VERSION ""

NS_ :

BS_:

BU_: TestTool AFL_AHL LDM_LH LDM_RH

BO_ 515 LightDistributionSystem: 5 AFL_AHL
 SG_ DistrCksm : 0|8@1+ (1,0) [0|255] ""  LDM_RH,LDM_LH
 SG_ RtCntryLghtDstrbtn : 15|1@1+ (1,0) [0|1] ""  LDM_LH,LDM_RH
 SG_ LftCntryLghtDstrbtn : 14|1@1+ (1,0) [0|1] ""  LDM_RH,LDM_LH
 SG_ RtAdvrsWthrLghtDstrbtn : 13|1@1+ (1,0) [0|1] ""  LDM_LH,LDM_RH
 SG_ LftAdvrsWthrLghtDstrbtn : 12|1@1+ (1,0) [0|1] ""  LDM_RH,LDM_LH
 SG_ DistrArc : 8|4@1+ (1,0) [0|15] ""  LDM_RH,LDM_LH
 SG_ RtGFHBLghtDstrbtnMtrwyLvl : 21|3@1+ (1,0) [0|7] ""  LDM_LH,LDM_RH
 SG_ RtDistrGFHB : 20|1@1+ (1,0) [0|1] ""  LDM_LH,LDM_RH
 SG_ LftGFHBLghtDstrbtnMtrwyLvl : 17|3@1+ (1,0) [0|7] ""  LDM_RH,LDM_LH
 SG_ LftDistrGFHB : 16|1@1+ (1,0) [0|1] ""  LDM_RH,LDM_LH
 SG_ LftMtrwyLghtDstrbtnLvl : 28|3@1+ (1,0) [0|7] ""  LDM_RH,LDM_LH
 SG_ RtMtrwyLghtDstrbtnLvl : 31|3@1+ (1,0) [0|7] ""  LDM_LH,LDM_RH
 SG_ RtHBLghtDstrbtn : 27|1@1+ (1,0) [0|1] ""  LDM_LH,LDM_RH
 SG_ LftHBLghtDstrbtn : 26|1@1+ (1,0) [0|1] ""  LDM_RH,LDM_LH
 SG_ RtHBFlshrLghtDstrbtn : 25|1@1+ (1,0) [0|1] ""  LDM_LH,LDM_RH
 SG_ LftHBFlshrLghtDstrbtn : 24|1@1+ (1,0) [0|1] ""  LDM_RH,LDM_LH
 SG_ RtTwnLghtDstrbtn : 37|1@1+ (1,0) [0|1] ""  LDM_LH,LDM_RH
 SG_ LftTwnLghtDstrbtn : 36|1@1+ (1,0) [0|1] ""  LDM_RH,LDM_LH
 SG_ RtPdstrnLghtDstrbtn : 35|1@1+ (1,0) [0|1] ""  LDM_LH,LDM_RH
 SG_ LftPdstrnLghtDstrbtn : 34|1@1+ (1,0) [0|1] ""  LDM_RH,LDM_LH

BO_ 1942 RtUsdtDiagResp: 8 LDM_RH
 SG_ RtUsdtDiagRsp : 7|64@0+ (1,0) [0|0] ""  TestTool

BO_ 1814 RtPhyDiagReq: 8 TestTool
 SG_ RtPhyDiagReq : 7|64@0+ (1,0) [0|1.84467440737096E+019] ""  LDM_RH

BO_ 2015 FuncDiagReq: 8 TestTool
 SG_ DiagInf : 7|64@0+ (1,0) [0|0] ""  LDM_RH,LDM_LH

BO_ 1813 LftPhyDiagReq: 8 TestTool
 SG_ LftPhyDiagReq : 7|64@0+ (1,0) [0|1.84467440737096E+019] ""  LDM_LH

BO_ 1941 LftUsdtDiagResp: 8 LDM_LH
 SG_ LftUsdtDiagRsp : 7|64@0+ (1,0) [0|0] ""  TestTool

BO_ 2161836032 ExtendIdTest: 8 TestTool
 SG_ Resp_LDMR_DgnInf : 7|64@0+ (1,0) [0|1.84467440737096E+019] ""  LDM_RH

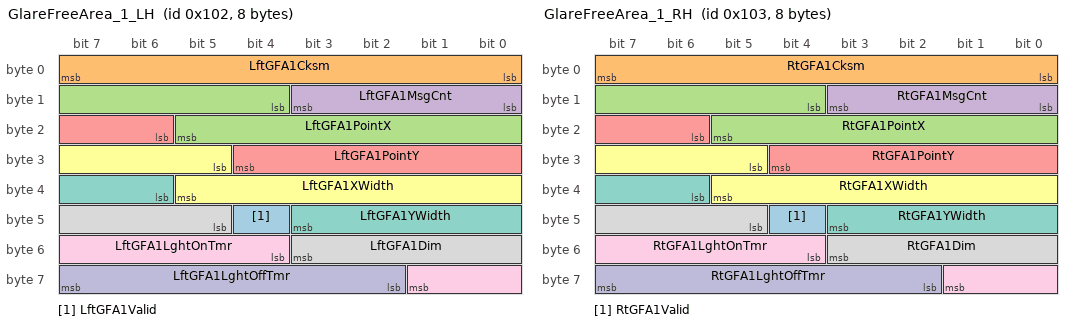
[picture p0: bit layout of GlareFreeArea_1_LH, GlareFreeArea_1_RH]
BO_ 258 GlareFreeArea_1_LH: 8 AFL_AHL
 SG_ LftGFA1Valid : 44|1@1+ (1,0) [0|1] ""  LDM_LH
 SG_ LftGFA1Cksm : 0|8@1+ (1,0) [0|255] ""  LDM_LH
 SG_ LftGFA1PointX : 12|10@1- (0.1,0) [-51.2|51.1] "deg"  LDM_LH
 SG_ LftGFA1MsgCnt : 8|4@1+ (1,0) [0|15] ""  LDM_LH
 SG_ LftGFA1PointY : 22|7@1- (0.1,0) [-6.4|6.3] "deg"  LDM_LH
 SG_ LftGFA1XWidth : 29|9@1+ (0.1,0) [0|51.1] "deg"  LDM_LH
 SG_ LftGFA1YWidth : 38|6@1+ (0.1,0) [0|6.3] "deg"  LDM_LH
 SG_ LftGFA1Dim : 45|7@1+ (1,0) [0|100] "%"  LDM_LH
 SG_ LftGFA1LghtOnTmr : 52|6@1+ (0.05,0) [0|3.15] "s"  LDM_LH
 SG_ LftGFA1LghtOffTmr : 58|6@1+ (0.05,0) [0|3.15] "s"  LDM_LH

BO_ 259 GlareFreeArea_1_RH: 8 AFL_AHL
 SG_ RtGFA1Valid : 44|1@1+ (1,0) [0|1] ""  LDM_RH
 SG_ RtGFA1Cksm : 0|8@1+ (1,0) [0|255] ""  LDM_RH
 SG_ RtGFA1PointX : 12|10@1- (0.1,0) [-51.2|51.1] "deg"  LDM_RH
 SG_ RtGFA1MsgCnt : 8|4@1+ (1,0) [0|15] ""  LDM_RH
 SG_ RtGFA1PointY : 22|7@1- (0.1,0) [-6.4|6.3] "deg"  LDM_RH
 SG_ RtGFA1XWidth : 29|9@1+ (0.1,0) [0|51.1] "deg"  LDM_RH
 SG_ RtGFA1YWidth : 38|6@1+ (0.1,0) [0|6.3] "deg"  LDM_RH
 SG_ RtGFA1Dim : 45|7@1+ (1,0) [0|100] "%"  LDM_RH
 SG_ RtGFA1LghtOnTmr : 52|6@1+ (0.05,0) [0|3.15] "s"  LDM_RH
 SG_ RtGFA1LghtOffTmr : 58|6@1+ (0.05,0) [0|3.15] "s"  LDM_RH

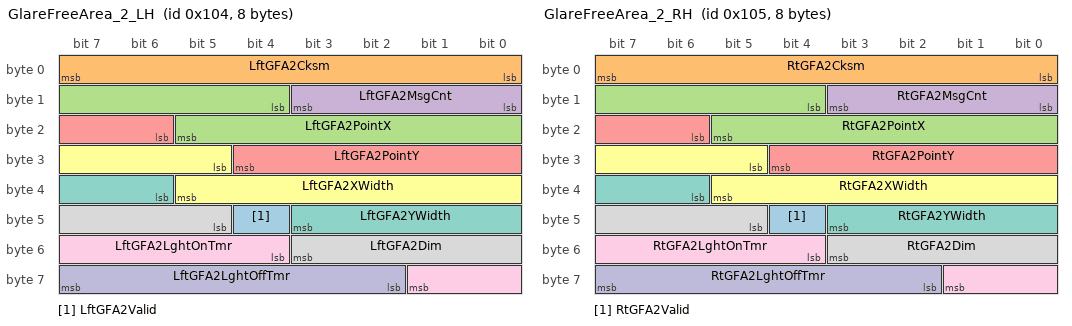
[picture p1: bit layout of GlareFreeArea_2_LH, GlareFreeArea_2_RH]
BO_ 260 GlareFreeArea_2_LH: 8 AFL_AHL
 SG_ LftGFA2Valid : 44|1@1+ (1,0) [0|1] ""  LDM_LH
 SG_ LftGFA2Cksm : 0|8@1+ (1,0) [0|255] ""  LDM_LH
 SG_ LftGFA2PointX : 12|10@1- (0.1,0) [-51.2|51.1] "deg"  LDM_LH
 SG_ LftGFA2MsgCnt : 8|4@1+ (1,0) [0|15] ""  LDM_LH
 SG_ LftGFA2PointY : 22|7@1- (0.1,0) [-6.4|6.3] "deg"  LDM_LH
 SG_ LftGFA2XWidth : 29|9@1+ (0.1,0) [0|51.1] "deg"  LDM_LH
 SG_ LftGFA2YWidth : 38|6@1+ (0.1,0) [0|6.3] "deg"  LDM_LH
 SG_ LftGFA2Dim : 45|7@1+ (1,0) [0|100] "%"  LDM_LH
 SG_ LftGFA2LghtOnTmr : 52|6@1+ (0.05,0) [0|3.15] "s"  LDM_LH
 SG_ LftGFA2LghtOffTmr : 58|6@1+ (0.05,0) [0|3.15] "s"  LDM_LH

BO_ 261 GlareFreeArea_2_RH: 8 AFL_AHL
 SG_ RtGFA2Valid : 44|1@1+ (1,0) [0|1] ""  LDM_RH
 SG_ RtGFA2Cksm : 0|8@1+ (1,0) [0|255] ""  LDM_RH
 SG_ RtGFA2PointX : 12|10@1- (0.1,0) [-51.2|51.1] "deg"  LDM_RH
 SG_ RtGFA2MsgCnt : 8|4@1+ (1,0) [0|15] ""  LDM_RH
 SG_ RtGFA2PointY : 22|7@1- (0.1,0) [-6.4|6.3] "deg"  LDM_RH
 SG_ RtGFA2XWidth : 29|9@1+ (0.1,0) [0|51.1] "deg"  LDM_RH
 SG_ RtGFA2YWidth : 38|6@1+ (0.1,0) [0|6.3] "deg"  LDM_RH
 SG_ RtGFA2Dim : 45|7@1+ (1,0) [0|100] "%"  LDM_RH
 SG_ RtGFA2LghtOnTmr : 52|6@1+ (0.05,0) [0|3.15] "s"  LDM_RH
 SG_ RtGFA2LghtOffTmr : 58|6@1+ (0.05,0) [0|3.15] "s"  LDM_RH

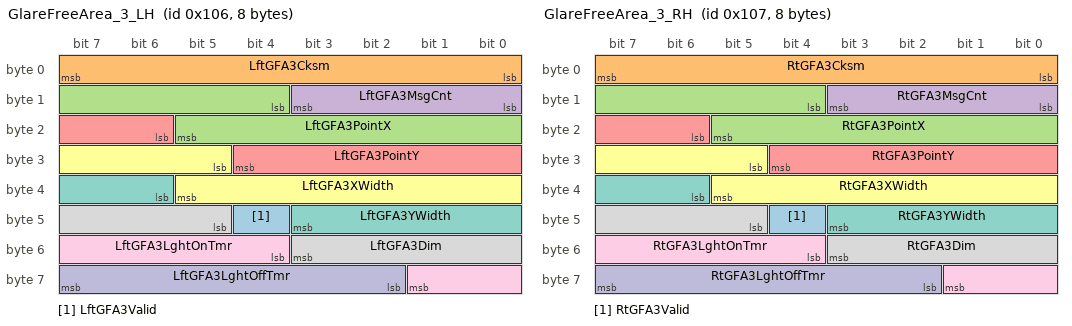
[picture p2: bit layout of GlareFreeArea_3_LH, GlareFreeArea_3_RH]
BO_ 262 GlareFreeArea_3_LH: 8 AFL_AHL
 SG_ LftGFA3Valid : 44|1@1+ (1,0) [0|1] ""  LDM_LH
 SG_ LftGFA3Cksm : 0|8@1+ (1,0) [0|255] ""  LDM_LH
 SG_ LftGFA3PointX : 12|10@1- (0.1,0) [-51.2|51.1] "deg"  LDM_LH
 SG_ LftGFA3MsgCnt : 8|4@1+ (1,0) [0|15] ""  LDM_LH
 SG_ LftGFA3PointY : 22|7@1- (0.1,0) [-6.4|6.3] "deg"  LDM_LH
 SG_ LftGFA3XWidth : 29|9@1+ (0.1,0) [0|51.1] "deg"  LDM_LH
 SG_ LftGFA3YWidth : 38|6@1+ (0.1,0) [0|6.3] "deg"  LDM_LH
 SG_ LftGFA3Dim : 45|7@1+ (1,0) [0|100] "%"  LDM_LH
 SG_ LftGFA3LghtOnTmr : 52|6@1+ (0.05,0) [0|3.15] "s"  LDM_LH
 SG_ LftGFA3LghtOffTmr : 58|6@1+ (0.05,0) [0|3.15] "s"  LDM_LH

BO_ 263 GlareFreeArea_3_RH: 8 AFL_AHL
 SG_ RtGFA3Valid : 44|1@1+ (1,0) [0|1] ""  LDM_RH
 SG_ RtGFA3Cksm : 0|8@1+ (1,0) [0|255] ""  LDM_RH
 SG_ RtGFA3PointX : 12|10@1- (0.1,0) [-51.2|51.1] "deg"  LDM_RH
 SG_ RtGFA3MsgCnt : 8|4@1+ (1,0) [0|15] ""  LDM_RH
 SG_ RtGFA3PointY : 22|7@1- (0.1,0) [-6.4|6.3] "deg"  LDM_RH
 SG_ RtGFA3XWidth : 29|9@1+ (0.1,0) [0|51.1] "deg"  LDM_RH
 SG_ RtGFA3YWidth : 38|6@1+ (0.1,0) [0|6.3] "deg"  LDM_RH
 SG_ RtGFA3Dim : 45|7@1+ (1,0) [0|100] "%"  LDM_RH
 SG_ RtGFA3LghtOnTmr : 52|6@1+ (0.05,0) [0|3.15] "s"  LDM_RH
 SG_ RtGFA3LghtOffTmr : 58|6@1+ (0.05,0) [0|3.15] "s"  LDM_RH

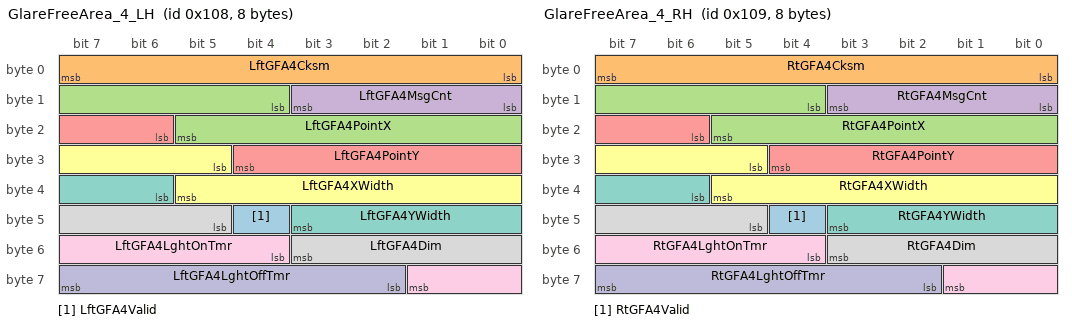
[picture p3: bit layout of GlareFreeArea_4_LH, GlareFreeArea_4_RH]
BO_ 264 GlareFreeArea_4_LH: 8 AFL_AHL
 SG_ LftGFA4Valid : 44|1@1+ (1,0) [0|1] ""  LDM_LH
 SG_ LftGFA4Cksm : 0|8@1+ (1,0) [0|255] ""  LDM_LH
 SG_ LftGFA4PointX : 12|10@1- (0.1,0) [-51.2|51.1] "deg"  LDM_LH
 SG_ LftGFA4MsgCnt : 8|4@1+ (1,0) [0|15] ""  LDM_LH
 SG_ LftGFA4PointY : 22|7@1- (0.1,0) [-6.4|6.3] "deg"  LDM_LH
 SG_ LftGFA4XWidth : 29|9@1+ (0.1,0) [0|51.1] "deg"  LDM_LH
 SG_ LftGFA4YWidth : 38|6@1+ (0.1,0) [0|6.3] "deg"  LDM_LH
 SG_ LftGFA4Dim : 45|7@1+ (1,0) [0|100] "%"  LDM_LH
 SG_ LftGFA4LghtOnTmr : 52|6@1+ (0.05,0) [0|3.15] "s"  LDM_LH
 SG_ LftGFA4LghtOffTmr : 58|6@1+ (0.05,0) [0|3.15] "s"  LDM_LH

BO_ 265 GlareFreeArea_4_RH: 8 AFL_AHL
 SG_ RtGFA4Valid : 44|1@1+ (1,0) [0|0] ""  LDM_RH
 SG_ RtGFA4Cksm : 0|8@1+ (1,0) [0|255] ""  LDM_RH
 SG_ RtGFA4PointX : 12|10@1- (0.1,0) [-51.2|51.1] "deg"  LDM_RH
 SG_ RtGFA4MsgCnt : 8|4@1+ (1,0) [0|15] ""  LDM_RH
 SG_ RtGFA4PointY : 22|7@1- (0.1,0) [-6.4|6.3] "deg"  LDM_RH
 SG_ RtGFA4XWidth : 29|9@1+ (0.1,0) [0|51.1] "deg"  LDM_RH
 SG_ RtGFA4YWidth : 38|6@1+ (0.1,0) [0|6.3] "deg"  LDM_RH
 SG_ RtGFA4Dim : 45|7@1+ (1,0) [0|100] "%"  LDM_RH
 SG_ RtGFA4LghtOnTmr : 52|6@1+ (0.05,0) [0|3.15] "s"  LDM_RH
 SG_ RtGFA4LghtOffTmr : 58|6@1+ (0.05,0) [0|3.15] "s"  LDM_RH

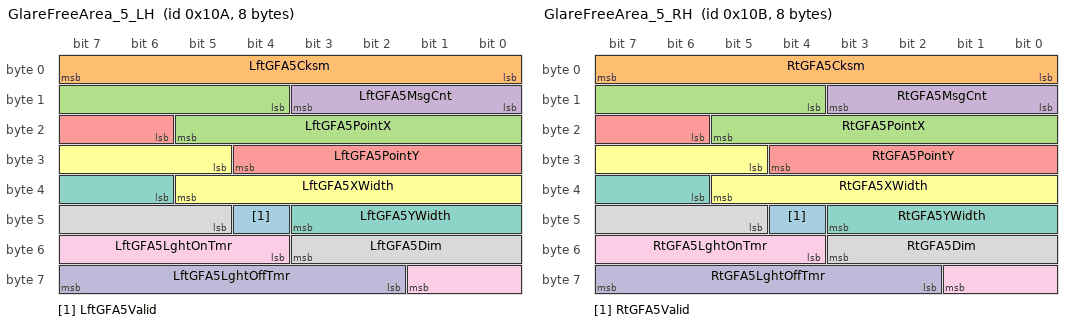
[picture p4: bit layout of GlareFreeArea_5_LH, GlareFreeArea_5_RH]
BO_ 266 GlareFreeArea_5_LH: 8 AFL_AHL
 SG_ LftGFA5Valid : 44|1@1+ (1,0) [0|0] ""  LDM_LH
 SG_ LftGFA5Cksm : 0|8@1+ (1,0) [0|255] ""  LDM_LH
 SG_ LftGFA5PointX : 12|10@1- (0.1,0) [-51.2|51.1] "deg"  LDM_LH
 SG_ LftGFA5MsgCnt : 8|4@1+ (1,0) [0|15] ""  LDM_LH
 SG_ LftGFA5PointY : 22|7@1- (0.1,0) [-6.4|6.3] "deg"  LDM_LH
 SG_ LftGFA5XWidth : 29|9@1+ (0.1,0) [0|51.1] "deg"  LDM_LH
 SG_ LftGFA5YWidth : 38|6@1+ (0.1,0) [0|6.3] "deg"  LDM_LH
 SG_ LftGFA5Dim : 45|7@1+ (1,0) [0|100] "%"  LDM_LH
 SG_ LftGFA5LghtOnTmr : 52|6@1+ (0.05,0) [0|3.15] "s"  LDM_LH
 SG_ LftGFA5LghtOffTmr : 58|6@1+ (0.05,0) [0|3.15] "s"  LDM_LH

BO_ 267 GlareFreeArea_5_RH: 8 AFL_AHL
 SG_ RtGFA5Valid : 44|1@1+ (1,0) [0|1] ""  LDM_RH
 SG_ RtGFA5Cksm : 0|8@1+ (1,0) [0|255] ""  LDM_RH
 SG_ RtGFA5PointX : 12|10@1- (0.1,0) [-51.2|51.1] "deg"  LDM_RH
 SG_ RtGFA5MsgCnt : 8|4@1+ (1,0) [0|15] ""  LDM_RH
 SG_ RtGFA5PointY : 22|7@1- (0.1,0) [-6.4|6.3] "deg"  LDM_RH
 SG_ RtGFA5XWidth : 29|9@1+ (0.1,0) [0|51.1] "deg"  LDM_RH
 SG_ RtGFA5YWidth : 38|6@1+ (0.1,0) [0|6.3] "deg"  LDM_RH
 SG_ RtGFA5Dim : 45|7@1+ (1,0) [0|100] "%"  LDM_RH
 SG_ RtGFA5LghtOnTmr : 52|6@1+ (0.05,0) [0|3.15] "s"  LDM_RH
 SG_ RtGFA5LghtOffTmr : 58|6@1+ (0.05,0) [0|3.15] "s"  LDM_RH

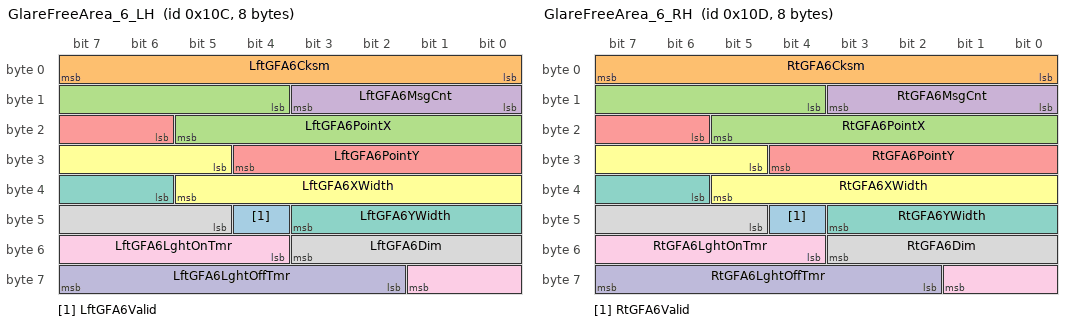
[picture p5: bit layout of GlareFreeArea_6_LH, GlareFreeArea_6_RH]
BO_ 268 GlareFreeArea_6_LH: 8 AFL_AHL
 SG_ LftGFA6Valid : 44|1@1+ (1,0) [0|1] ""  LDM_LH
 SG_ LftGFA6Cksm : 0|8@1+ (1,0) [0|255] ""  LDM_LH
 SG_ LftGFA6PointX : 12|10@1- (0.1,0) [-51.2|51.1] "deg"  LDM_LH
 SG_ LftGFA6MsgCnt : 8|4@1+ (1,0) [0|15] ""  LDM_LH
 SG_ LftGFA6PointY : 22|7@1- (0.1,0) [-6.4|6.3] "deg"  LDM_LH
 SG_ LftGFA6XWidth : 29|9@1+ (0.1,0) [0|51.1] "deg"  LDM_LH
 SG_ LftGFA6YWidth : 38|6@1+ (0.1,0) [0|6.3] "deg"  LDM_LH
 SG_ LftGFA6Dim : 45|7@1+ (1,0) [0|100] "%"  LDM_LH
 SG_ LftGFA6LghtOnTmr : 52|6@1+ (0.05,0) [0|3.15] "s"  LDM_LH
 SG_ LftGFA6LghtOffTmr : 58|6@1+ (0.05,0) [0|3.15] "s"  LDM_LH

BO_ 269 GlareFreeArea_6_RH: 8 AFL_AHL
 SG_ RtGFA6Valid : 44|1@1+ (1,0) [0|0] ""  LDM_RH
 SG_ RtGFA6Cksm : 0|8@1+ (1,0) [0|255] ""  LDM_RH
 SG_ RtGFA6PointX : 12|10@1- (0.1,0) [-51.2|51.1] "deg"  LDM_RH
 SG_ RtGFA6MsgCnt : 8|4@1+ (1,0) [0|15] ""  LDM_RH
 SG_ RtGFA6PointY : 22|7@1- (0.1,0) [-6.4|6.3] "deg"  LDM_RH
 SG_ RtGFA6XWidth : 29|9@1+ (0.1,0) [0|51.1] "deg"  LDM_RH
 SG_ RtGFA6YWidth : 38|6@1+ (0.1,0) [0|6.3] "deg"  LDM_RH
 SG_ RtGFA6Dim : 45|7@1+ (1,0) [0|100] "%"  LDM_RH
 SG_ RtGFA6LghtOnTmr : 52|6@1+ (0.05,0) [0|3.15] "s"  LDM_RH
 SG_ RtGFA6LghtOffTmr : 58|6@1+ (0.05,0) [0|3.15] "s"  LDM_RH

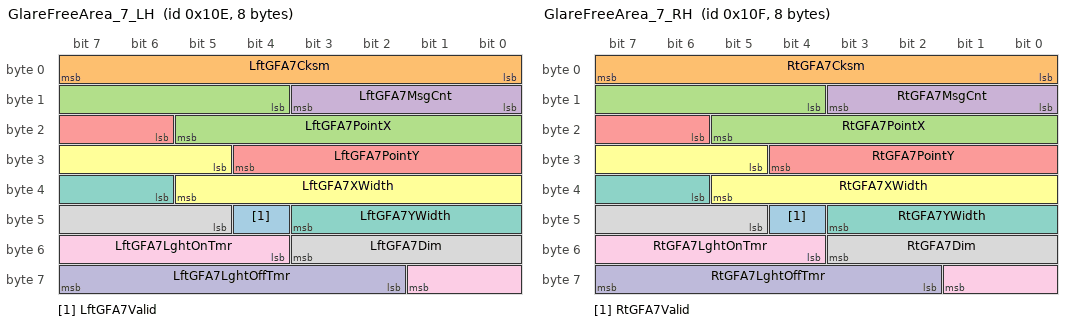
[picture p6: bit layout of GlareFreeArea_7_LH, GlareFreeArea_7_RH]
BO_ 270 GlareFreeArea_7_LH: 8 AFL_AHL
 SG_ LftGFA7Valid : 44|1@1+ (1,0) [0|0] ""  LDM_LH
 SG_ LftGFA7Cksm : 0|8@1+ (1,0) [0|255] ""  LDM_LH
 SG_ LftGFA7PointX : 12|10@1- (0.1,0) [-51.2|51.1] "deg"  LDM_LH
 SG_ LftGFA7MsgCnt : 8|4@1+ (1,0) [0|15] ""  LDM_LH
 SG_ LftGFA7PointY : 22|7@1- (0.1,0) [-6.4|6.3] "deg"  LDM_LH
 SG_ LftGFA7XWidth : 29|9@1+ (0.1,0) [0|51.1] "deg"  LDM_LH
 SG_ LftGFA7YWidth : 38|6@1+ (0.1,0) [0|6.3] "deg"  LDM_LH
 SG_ LftGFA7Dim : 45|7@1+ (1,0) [0|100] "%"  LDM_LH
 SG_ LftGFA7LghtOnTmr : 52|6@1+ (0.05,0) [0|3.15] "s"  LDM_LH
 SG_ LftGFA7LghtOffTmr : 58|6@1+ (0.05,0) [0|3.15] "s"  LDM_LH

BO_ 271 GlareFreeArea_7_RH: 8 AFL_AHL
 SG_ RtGFA7Valid : 44|1@1+ (1,0) [0|0] ""  LDM_RH
 SG_ RtGFA7Cksm : 0|8@1+ (1,0) [0|255] ""  LDM_RH
 SG_ RtGFA7PointX : 12|10@1- (0.1,0) [-51.2|51.1] "deg"  LDM_RH
 SG_ RtGFA7MsgCnt : 8|4@1+ (1,0) [0|15] ""  LDM_RH
 SG_ RtGFA7PointY : 22|7@1- (0.1,0) [-6.4|6.3] "deg"  LDM_RH
 SG_ RtGFA7XWidth : 29|9@1+ (0.1,0) [0|51.1] "deg"  LDM_RH
 SG_ RtGFA7YWidth : 38|6@1+ (0.1,0) [0|6.3] "deg"  LDM_RH
 SG_ RtGFA7Dim : 45|7@1+ (1,0) [0|100] "%"  LDM_RH
 SG_ RtGFA7LghtOnTmr : 52|6@1+ (0.05,0) [0|3.15] "s"  LDM_RH
 SG_ RtGFA7LghtOffTmr : 58|6@1+ (0.05,0) [0|3.15] "s"  LDM_RH

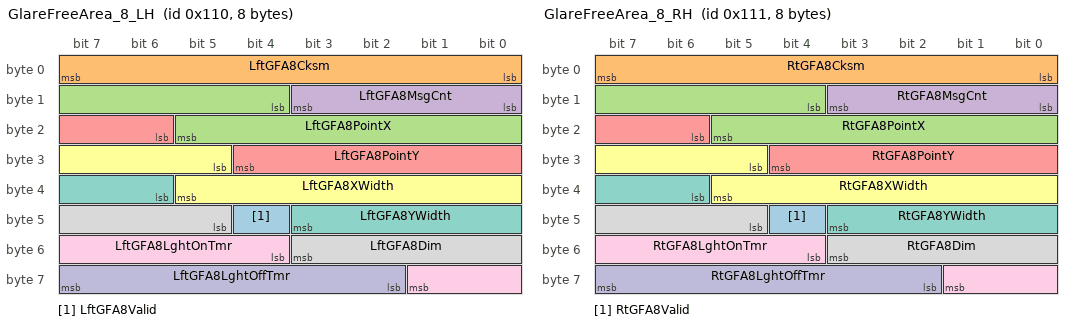
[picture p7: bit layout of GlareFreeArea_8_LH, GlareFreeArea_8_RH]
BO_ 272 GlareFreeArea_8_LH: 8 AFL_AHL
 SG_ LftGFA8Valid : 44|1@1+ (1,0) [0|0] ""  LDM_LH
 SG_ LftGFA8Cksm : 0|8@1+ (1,0) [0|255] ""  LDM_LH
 SG_ LftGFA8PointX : 12|10@1- (0.1,0) [-51.2|51.1] "deg"  LDM_LH
 SG_ LftGFA8MsgCnt : 8|4@1+ (1,0) [0|15] ""  LDM_LH
 SG_ LftGFA8PointY : 22|7@1- (0.1,0) [-6.4|6.3] "deg"  LDM_LH
 SG_ LftGFA8XWidth : 29|9@1+ (0.1,0) [0|51.1] "deg"  LDM_LH
 SG_ LftGFA8YWidth : 38|6@1+ (0.1,0) [0|6.3] "deg"  LDM_LH
 SG_ LftGFA8Dim : 45|7@1+ (1,0) [0|100] "%"  LDM_LH
 SG_ LftGFA8LghtOnTmr : 52|6@1+ (0.05,0) [0|3.15] "s"  LDM_LH
 SG_ LftGFA8LghtOffTmr : 58|6@1+ (0.05,0) [0|3.15] "s"  LDM_LH

BO_ 273 GlareFreeArea_8_RH: 8 AFL_AHL
 SG_ RtGFA8Valid : 44|1@1+ (1,0) [0|1] ""  LDM_RH
 SG_ RtGFA8Cksm : 0|8@1+ (1,0) [0|255] ""  LDM_RH
 SG_ RtGFA8PointX : 12|10@1- (0.1,0) [-51.2|51.1] "deg"  LDM_RH
 SG_ RtGFA8MsgCnt : 8|4@1+ (1,0) [0|15] ""  LDM_RH
 SG_ RtGFA8PointY : 22|7@1- (0.1,0) [-6.4|6.3] "deg"  LDM_RH
 SG_ RtGFA8XWidth : 29|9@1+ (0.1,0) [0|51.1] "deg"  LDM_RH
 SG_ RtGFA8YWidth : 38|6@1+ (0.1,0) [0|6.3] "deg"  LDM_RH
 SG_ RtGFA8Dim : 45|7@1+ (1,0) [0|100] "%"  LDM_RH
 SG_ RtGFA8LghtOnTmr : 52|6@1+ (0.05,0) [0|3.15] "s"  LDM_RH
 SG_ RtGFA8LghtOffTmr : 58|6@1+ (0.05,0) [0|3.15] "s"  LDM_RH

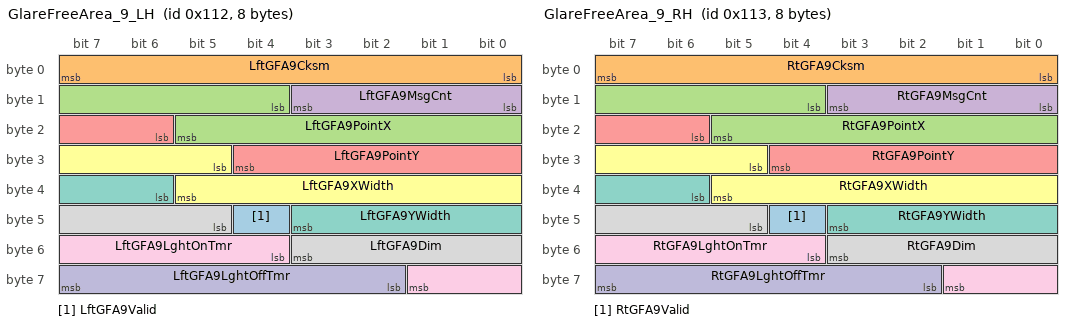
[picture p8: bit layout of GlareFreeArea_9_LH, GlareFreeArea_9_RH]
BO_ 274 GlareFreeArea_9_LH: 8 AFL_AHL
 SG_ LftGFA9Valid : 44|1@1+ (1,0) [0|0] ""  LDM_LH
 SG_ LftGFA9Cksm : 0|8@1+ (1,0) [0|255] ""  LDM_LH
 SG_ LftGFA9PointX : 12|10@1- (0.1,0) [-51.2|51.1] "deg"  LDM_LH
 SG_ LftGFA9MsgCnt : 8|4@1+ (1,0) [0|15] ""  LDM_LH
 SG_ LftGFA9PointY : 22|7@1- (0.1,0) [-6.4|6.3] "deg"  LDM_LH
 SG_ LftGFA9XWidth : 29|9@1+ (0.1,0) [0|51.1] "deg"  LDM_LH
 SG_ LftGFA9YWidth : 38|6@1+ (0.1,0) [0|6.3] "deg"  LDM_LH
 SG_ LftGFA9Dim : 45|7@1+ (1,0) [0|100] "%"  LDM_LH
 SG_ LftGFA9LghtOnTmr : 52|6@1+ (0.05,0) [0|3.15] "s"  LDM_LH
 SG_ LftGFA9LghtOffTmr : 58|6@1+ (0.05,0) [0|3.15] "s"  LDM_LH

BO_ 275 GlareFreeArea_9_RH: 8 AFL_AHL
 SG_ RtGFA9Valid : 44|1@1+ (1,0) [0|1] ""  LDM_RH
 SG_ RtGFA9Cksm : 0|8@1+ (1,0) [0|255] ""  LDM_RH
 SG_ RtGFA9PointX : 12|10@1- (0.1,0) [-51.2|51.1] "deg"  LDM_RH
 SG_ RtGFA9MsgCnt : 8|4@1+ (1,0) [0|15] ""  LDM_RH
 SG_ RtGFA9PointY : 22|7@1- (0.1,0) [-6.4|6.3] "deg"  LDM_RH
 SG_ RtGFA9XWidth : 29|9@1+ (0.1,0) [0|51.1] "deg"  LDM_RH
 SG_ RtGFA9YWidth : 38|6@1+ (0.1,0) [0|6.3] "deg"  LDM_RH
 SG_ RtGFA9Dim : 45|7@1+ (1,0) [0|100] "%"  LDM_RH
 SG_ RtGFA9LghtOnTmr : 52|6@1+ (0.05,0) [0|3.15] "s"  LDM_RH
 SG_ RtGFA9LghtOffTmr : 58|6@1+ (0.05,0) [0|3.15] "s"  LDM_RH

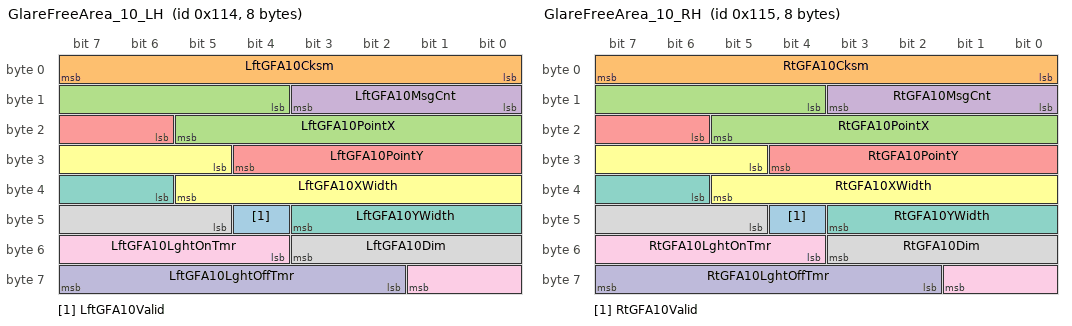
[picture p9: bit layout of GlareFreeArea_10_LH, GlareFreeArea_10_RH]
BO_ 276 GlareFreeArea_10_LH: 8 AFL_AHL
 SG_ LftGFA10Valid : 44|1@1+ (1,0) [0|1] ""  LDM_LH
 SG_ LftGFA10Cksm : 0|8@1+ (1,0) [0|255] ""  LDM_LH
 SG_ LftGFA10PointX : 12|10@1- (0.1,0) [-51.2|51.1] "deg"  LDM_LH
 SG_ LftGFA10MsgCnt : 8|4@1+ (1,0) [0|15] ""  LDM_LH
 SG_ LftGFA10PointY : 22|7@1- (0.1,0) [-6.4|6.3] "deg"  LDM_LH
 SG_ LftGFA10XWidth : 29|9@1+ (0.1,0) [0|51.1] "deg"  LDM_LH
 SG_ LftGFA10YWidth : 38|6@1+ (0.1,0) [0|6.3] "deg"  LDM_LH
 SG_ LftGFA10Dim : 45|7@1+ (1,0) [0|100] "%"  LDM_LH
 SG_ LftGFA10LghtOnTmr : 52|6@1+ (0.05,0) [0|3.15] "s"  LDM_LH
 SG_ LftGFA10LghtOffTmr : 58|6@1+ (0.05,0) [0|3.15] "s"  LDM_LH

BO_ 277 GlareFreeArea_10_RH: 8 AFL_AHL
 SG_ RtGFA10Valid : 44|1@1+ (1,0) [0|1] ""  LDM_RH
 SG_ RtGFA10Cksm : 0|8@1+ (1,0) [0|255] ""  LDM_RH
 SG_ RtGFA10PointX : 12|10@1- (0.1,0) [-51.2|51.1] "deg"  LDM_RH
 SG_ RtGFA10MsgCnt : 8|4@1+ (1,0) [0|15] ""  LDM_RH
 SG_ RtGFA10PointY : 22|7@1- (0.1,0) [-6.4|6.3] "deg"  LDM_RH
 SG_ RtGFA10XWidth : 29|9@1+ (0.1,0) [0|51.1] "deg"  LDM_RH
 SG_ RtGFA10YWidth : 38|6@1+ (0.1,0) [0|6.3] "deg"  LDM_RH
 SG_ RtGFA10Dim : 45|7@1+ (1,0) [0|100] "%"  LDM_RH
 SG_ RtGFA10LghtOnTmr : 52|6@1+ (0.05,0) [0|3.15] "s"  LDM_RH
 SG_ RtGFA10LghtOffTmr : 58|6@1+ (0.05,0) [0|3.15] "s"  LDM_RH

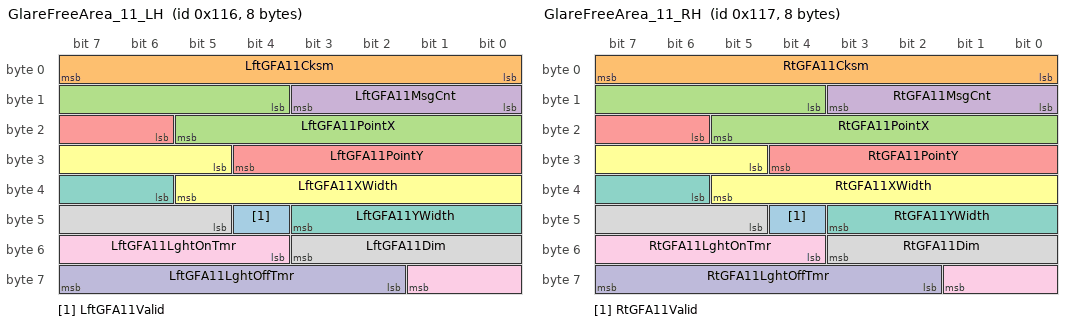
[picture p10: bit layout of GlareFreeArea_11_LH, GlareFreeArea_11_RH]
BO_ 278 GlareFreeArea_11_LH: 8 AFL_AHL
 SG_ LftGFA11Valid : 44|1@1+ (1,0) [0|1] ""  LDM_LH
 SG_ LftGFA11Cksm : 0|8@1+ (1,0) [0|255] ""  LDM_LH
 SG_ LftGFA11PointX : 12|10@1- (0.1,0) [-51.2|51.1] "deg"  LDM_LH
 SG_ LftGFA11MsgCnt : 8|4@1+ (1,0) [0|15] ""  LDM_LH
 SG_ LftGFA11PointY : 22|7@1- (0.1,0) [-6.4|6.3] "deg"  LDM_LH
 SG_ LftGFA11XWidth : 29|9@1+ (0.1,0) [0|51.1] "deg"  LDM_LH
 SG_ LftGFA11YWidth : 38|6@1+ (0.1,0) [0|6.3] "deg"  LDM_LH
 SG_ LftGFA11Dim : 45|7@1+ (1,0) [0|100] "%"  LDM_LH
 SG_ LftGFA11LghtOnTmr : 52|6@1+ (0.05,0) [0|3.15] "s"  LDM_LH
 SG_ LftGFA11LghtOffTmr : 58|6@1+ (0.05,0) [0|3.15] "s"  LDM_LH

BO_ 279 GlareFreeArea_11_RH: 8 AFL_AHL
 SG_ RtGFA11Valid : 44|1@1+ (1,0) [0|1] ""  LDM_RH
 SG_ RtGFA11Cksm : 0|8@1+ (1,0) [0|255] ""  LDM_RH
 SG_ RtGFA11PointX : 12|10@1- (0.1,0) [-51.2|51.1] "deg"  LDM_RH
 SG_ RtGFA11MsgCnt : 8|4@1+ (1,0) [0|15] ""  LDM_RH
 SG_ RtGFA11PointY : 22|7@1- (0.1,0) [-6.4|6.3] "deg"  LDM_RH
 SG_ RtGFA11XWidth : 29|9@1+ (0.1,0) [0|51.1] "deg"  LDM_RH
 SG_ RtGFA11YWidth : 38|6@1+ (0.1,0) [0|6.3] "deg"  LDM_RH
 SG_ RtGFA11Dim : 45|7@1+ (1,0) [0|100] "%"  LDM_RH
 SG_ RtGFA11LghtOnTmr : 52|6@1+ (0.05,0) [0|3.15] "s"  LDM_RH
 SG_ RtGFA11LghtOffTmr : 58|6@1+ (0.05,0) [0|3.15] "s"  LDM_RH

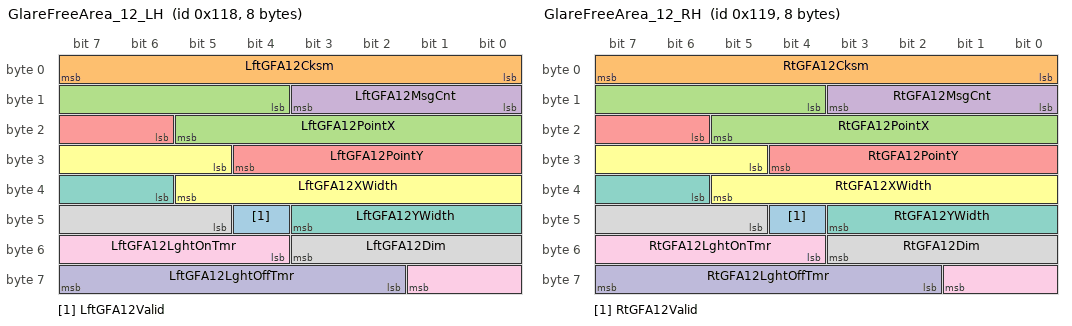
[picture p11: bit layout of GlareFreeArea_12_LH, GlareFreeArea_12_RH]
BO_ 280 GlareFreeArea_12_LH: 8 AFL_AHL
 SG_ LftGFA12Valid : 44|1@1+ (1,0) [0|1] ""  LDM_LH
 SG_ LftGFA12Cksm : 0|8@1+ (1,0) [0|255] ""  LDM_LH
 SG_ LftGFA12PointX : 12|10@1- (0.1,0) [-51.2|51.1] "deg"  LDM_LH
 SG_ LftGFA12MsgCnt : 8|4@1+ (1,0) [0|15] ""  LDM_LH
 SG_ LftGFA12PointY : 22|7@1- (0.1,0) [-6.4|6.3] "deg"  LDM_LH
 SG_ LftGFA12XWidth : 29|9@1+ (0.1,0) [0|51.1] "deg"  LDM_LH
 SG_ LftGFA12YWidth : 38|6@1+ (0.1,0) [0|6.3] "deg"  LDM_LH
 SG_ LftGFA12Dim : 45|7@1+ (1,0) [0|100] "%"  LDM_LH
 SG_ LftGFA12LghtOnTmr : 52|6@1+ (0.05,0) [0|3.15] "s"  LDM_LH
 SG_ LftGFA12LghtOffTmr : 58|6@1+ (0.05,0) [0|3.15] "s"  LDM_LH

BO_ 281 GlareFreeArea_12_RH: 8 AFL_AHL
 SG_ RtGFA12Valid : 44|1@1+ (1,0) [0|1] ""  LDM_RH
 SG_ RtGFA12Cksm : 0|8@1+ (1,0) [0|255] ""  LDM_RH
 SG_ RtGFA12PointX : 12|10@1- (0.1,0) [-51.2|51.1] "deg"  LDM_RH
 SG_ RtGFA12MsgCnt : 8|4@1+ (1,0) [0|15] ""  LDM_RH
 SG_ RtGFA12PointY : 22|7@1- (0.1,0) [-6.4|6.3] "deg"  LDM_RH
 SG_ RtGFA12XWidth : 29|9@1+ (0.1,0) [0|51.1] "deg"  LDM_RH
 SG_ RtGFA12YWidth : 38|6@1+ (0.1,0) [0|6.3] "deg"  LDM_RH
 SG_ RtGFA12Dim : 45|7@1+ (1,0) [0|100] "%"  LDM_RH
 SG_ RtGFA12LghtOnTmr : 52|6@1+ (0.05,0) [0|3.15] "s"  LDM_RH
 SG_ RtGFA12LghtOffTmr : 58|6@1+ (0.05,0) [0|3.15] "s"  LDM_RH

BO_ 481 GlareFreeHighBeamControl_RH: 2 AFL_AHL
 SG_ RtDiagLed : 15|8@0+ (1,0) [0|0] ""  LDM_RH
 SG_ RtRoutineCtrl : 7|1@0+ (1,0) [0|0] ""  LDM_RH

BO_ 512 LightCenterOfGravityMovement: 7 AFL_AHL
 SG_ LCGM_LghtCntrWdthLftSdEdg : 7|11@0- (0.1,0) [-102.4|102.3] "LCGM_LghtCntrWdthLftSdEdg_Units"  LDM_LH
 SG_ LCGM_LghtCntrWdthRtSdEdg : 23|11@0- (0.1,0) [-102.4|102.3] "LCGM_LghtCntrWdthRtSdEdg_Units"  LDM_RH
 SG_ LCGM_CntrLghtLvl : 39|8@0+ (0.5,0) [0|127.5] "LCGM_CntrLghtLvl_Units"  LDM_LH,LDM_RH
 SG_ LCGM_BckgrndLghtLvl : 47|8@0+ (0.5,0) [0|127.5] "LCGM_BckgrndLghtLvl_Units"  LDM_LH,LDM_RH
 SG_ LCGM_FnctnStat : 55|1@0+ (1,0) [0|1] ""  LDM_LH,LDM_RH

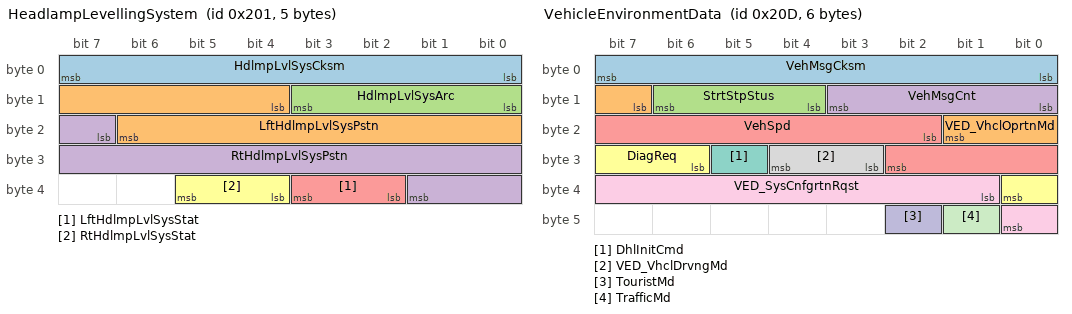
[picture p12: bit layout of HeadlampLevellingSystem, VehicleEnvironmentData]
BO_ 513 HeadlampLevellingSystem: 5 AFL_AHL
 SG_ HdlmpLvlSysCksm : 0|8@1+ (1,0) [0|255] ""  LDM_RH,LDM_LH
 SG_ LftHdlmpLvlSysPstn : 12|11@1- (0.01,0) [-10.24|10.23] "%"  LDM_RH,LDM_LH
 SG_ HdlmpLvlSysArc : 8|4@1+ (1,0) [0|15] ""  LDM_RH,LDM_LH
 SG_ RtHdlmpLvlSysPstn : 23|11@1- (0.01,0) [-10.24|10.23] "%"  LDM_LH,LDM_RH
 SG_ LftHdlmpLvlSysStat : 34|2@1+ (1,0) [0|3] "Enum"  LDM_RH,LDM_LH
 SG_ RtHdlmpLvlSysStat : 36|2@1+ (1,0) [0|3] "Enum"  LDM_LH,LDM_RH

BO_ 514 DynamicBendingLightSystem: 5 AFL_AHL
 SG_ DBLS_Chcksm : 0|8@1+ (1,0) [0|255] ""  LDM_RH,LDM_LH
 SG_ DBLS_LftHdlmpSwvlAngl : 12|11@1- (0.05,0) [-51.2|51.15] "DBLS_LftHdlmpSwvlAngl_Units"  LDM_RH,LDM_LH
 SG_ DBLS_MssgCntr : 8|4@1+ (1,0) [0|15] ""  LDM_RH,LDM_LH
 SG_ DBLS_RtHdlmpSwvlAngl : 23|11@1- (0.05,0) [-51.2|51.15] "DBLS_RtHdlmpSwvlAngl_Units"  LDM_LH,LDM_RH

BO_ 516 StaticBendingLightSystem: 2 AFL_AHL
 SG_ LftBndDim : 7|8@0+ (0.5,0) [0|100] "%"  LDM_LH
 SG_ RtBndDim : 15|8@0+ (0.5,0) [0|100] "%"  LDM_RH

BO_ 523 StartStopLightSystem: 4 AFL_AHL
 SG_ SSLS_Chcksm : 7|8@0+ (1,0) [0|255] ""  LDM_RH,LDM_LH
 SG_ SSLS_LftHdlmpStrtStpIntnstyVal : 11|8@0+ (0.5,0) [0|127.5] "SSLS_LftHdlmpStrtStpIntnstyVal_U"  LDM_RH,LDM_LH
 SG_ SSLS_MssgCntr : 15|4@0+ (1,0) [0|15] ""  LDM_RH,LDM_LH
 SG_ SSLS_RtHdlmpStrtStpIntnstyVal : 19|8@0+ (0.5,0) [0|127.5] "SSLS_RtHdlmpStrtStpIntnstyVal_"  LDM_RH,LDM_LH

BO_ 525 VehicleEnvironmentData: 6 AFL_AHL
 SG_ VehMsgCksm : 0|8@1+ (1,0) [0|255] ""  LDM_RH,LDM_LH
 SG_ VED_VhclOprtnMd : 15|3@1+ (1,0) [0|7] ""  LDM_RH,LDM_LH
 SG_ StrtStpStus : 12|3@1+ (1,0) [0|7] ""  LDM_LH,LDM_RH
 SG_ VehMsgCnt : 8|4@1+ (1,0) [0|15] ""  LDM_RH,LDM_LH
 SG_ VehSpd : 18|9@1+ (1,0) [0|511] "km/h"  LDM_LH,LDM_RH
 SG_ DiagReq : 30|3@1+ (1,0) [0|7] ""  LDM_RH,LDM_LH
 SG_ DhlInitCmd : 29|1@1+ (1,0) [0|1] "Enum"  LDM_LH,LDM_RH
 SG_ VED_VhclDrvngMd : 27|2@1+ (1,0) [0|3] ""  LDM_RH,LDM_LH
 SG_ VED_SysCnfgrtnRqst : 33|8@1+ (1,0) [0|255] ""  LDM_RH,LDM_LH
 SG_ TouristMd : 42|1@1+ (1,0) [0|1] ""  LDM_LH,LDM_RH
 SG_ TrafficMd : 41|1@1+ (1,0) [0|1] ""  LDM_LH,LDM_RH

BO_ 1024 SysSt_LftGlareFreeHighBeam: 8 LDM_LH
 SG_ LftGFHBSysSts : 8|56@1+ (1,0) [0|7.20575940379279E+016] ""  AFL_AHL
 SG_ LftGFHBCksm : 0|8@1+ (1,0) [0|255] ""  AFL_AHL

BO_ 1025 SysSt_RtGlareFreeHighBeam: 8 LDM_RH
 SG_ RtGFHBSysSts : 8|56@1+ (1,0) [0|7.20575940379279E+016] ""  AFL_AHL
 SG_ RtGFHBCksm : 0|8@1+ (1,0) [0|255] ""  AFL_AHL

BO_ 1026 SysSt_LftLevellingSystem: 8 LDM_LH
 SG_ LftDhlSysSts : 8|56@1+ (1,0) [0|7.20575940379279E+016] ""  AFL_AHL
 SG_ LftDhlCksm : 0|8@1+ (1,0) [0|255] ""  AFL_AHL

BO_ 1027 SysSt_RtLevellingSystem: 8 LDM_RH
 SG_ RtDhlSysSts : 8|56@1+ (1,0) [0|7.20575940379279E+016] ""  AFL_AHL
 SG_ RtDhlCksm : 0|8@1+ (1,0) [0|255] ""  AFL_AHL

BO_ 1028 SysSt_LftDynBendingLight: 8 LDM_LH
 SG_ LftDBndCksm : 0|8@1+ (1,0) [0|255] ""  AFL_AHL
 SG_ LftDBndSysSts : 8|56@1+ (1,0) [0|7.20575940379279E+016] ""  AFL_AHL

BO_ 1029 SysSt_RtDynBendingLight: 8 LDM_RH
 SG_ RtDBndCksm : 0|8@1+ (1,0) [0|255] ""  AFL_AHL
 SG_ RtDBndSysSts : 8|56@1+ (1,0) [0|7.20575940379279E+016] ""  AFL_AHL

BO_ 1030 SysSt_LftLightDistribution: 8 LDM_LH
 SG_ LftDistrSysSts : 8|56@1+ (1,0) [0|7.20575940379279E+016] ""  AFL_AHL
 SG_ LftDistrCksm : 0|8@1+ (1,0) [0|255] ""  AFL_AHL

BO_ 1031 SysSt_RtLightDistribution: 8 LDM_RH
 SG_ RtDistrSysSts : 8|56@1+ (1,0) [0|7.20575940379279E+016] ""  AFL_AHL
 SG_ RtDistrCksm : 0|8@1+ (1,0) [0|255] ""  AFL_AHL

BO_ 1032 SysSt_LftStaticBendingLight: 8 LDM_LH
 SG_ LftBndSysSts : 11|52@0+ (1,0) [0|4.5035996273705E+015] ""  AFL_AHL

BO_ 1033 SysSt_RtStaticBendingLight: 8 LDM_RH
 SG_ RtBndSysSts : 11|52@0+ (1,0) [0|4.5035996273705E+015] ""  AFL_AHL

BO_ 1042 SysSt_LftLowBeam: 8 LDM_LH
 SG_ LftLbSysSts : 8|56@1+ (1,0) [0|7.20575940379279E+016] ""  AFL_AHL
 SG_ LftLbCksm : 0|8@1+ (1,0) [0|255] ""  AFL_AHL

BO_ 1043 SysSt_RtLowBeam: 8 LDM_RH
 SG_ RtLbSysSts : 8|56@1+ (1,0) [0|7.20575940379279E+016] ""  AFL_AHL
 SG_ RtLbCksm : 0|8@1+ (1,0) [0|255] ""  AFL_AHL

BO_ 1044 SysSt_LftHighBeam: 8 LDM_LH
 SG_ LftHbSysSts : 8|56@1+ (1,0) [0|7.20575940379279E+016] ""  AFL_AHL
 SG_ LftHbCksm : 0|8@1+ (1,0) [0|255] ""  AFL_AHL

BO_ 1045 SysSt_RtHighBeam: 8 LDM_RH
 SG_ RtHbSysSts : 8|56@1+ (1,0) [0|7.20575940379279E+016] ""  AFL_AHL
 SG_ RtHbCksm : 0|8@1+ (1,0) [0|255] ""  AFL_AHL

BO_ 1280 LftEcuIdent: 8 LDM_LH
 SG_ LftLdmInfo : 15|56@0+ (1,0) [0|7.20575940379279E+016] ""  AFL_AHL
 SG_ LftLdmInfoIdx : 7|8@0+ (1,0) [0|255] ""  AFL_AHL

BO_ 1281 RtEcuIdent: 8 LDM_RH
 SG_ RtLdmInfo : 15|56@0+ (1,0) [0|7.20575940379279E+016] ""  AFL_AHL
 SG_ RtLdmInfoIdx : 7|8@0+ (1,0) [0|255] ""  AFL_AHL

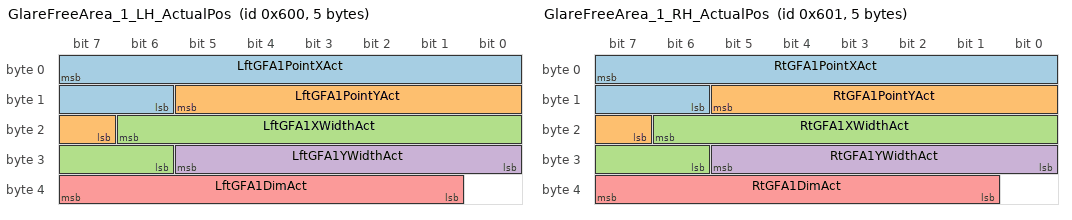
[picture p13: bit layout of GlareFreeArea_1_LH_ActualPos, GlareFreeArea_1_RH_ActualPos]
BO_ 1536 GlareFreeArea_1_LH_ActualPos: 5 LDM_LH
 SG_ LftGFA1PointXAct : 7|10@0- (0.1,0) [-51.2|51.1] "deg"  AFL_AHL
 SG_ LftGFA1PointYAct : 13|7@0- (0.1,0) [-6.4|6.3] "deg"  AFL_AHL
 SG_ LftGFA1XWidthAct : 22|9@0+ (0.1,0) [0|51.1] "deg"  AFL_AHL
 SG_ LftGFA1YWidthAct : 29|6@0+ (0.1,0) [0|6.3] "deg"  AFL_AHL
 SG_ LftGFA1DimAct : 39|7@0+ (1,0) [0|100] "%"  AFL_AHL

BO_ 1537 GlareFreeArea_1_RH_ActualPos: 5 LDM_RH
 SG_ RtGFA1PointXAct : 7|10@0- (0.1,0) [-51.2|51.1] "deg"  AFL_AHL
 SG_ RtGFA1PointYAct : 13|7@0- (0.1,0) [-6.4|6.3] "deg"  AFL_AHL
 SG_ RtGFA1XWidthAct : 22|9@0+ (0.1,0) [0|51.1] "deg"  AFL_AHL
 SG_ RtGFA1YWidthAct : 29|6@0+ (0.1,0) [0|6.3] "deg"  AFL_AHL
 SG_ RtGFA1DimAct : 39|7@0+ (1,0) [0|100] "%"  AFL_AHL

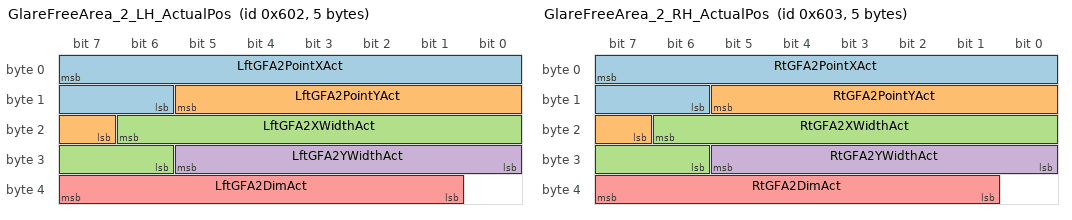
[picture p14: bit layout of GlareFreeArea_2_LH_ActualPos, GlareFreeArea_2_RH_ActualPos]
BO_ 1538 GlareFreeArea_2_LH_ActualPos: 5 LDM_LH
 SG_ LftGFA2PointXAct : 7|10@0- (0.1,0) [-51.2|51.1] "deg"  AFL_AHL
 SG_ LftGFA2PointYAct : 13|7@0- (0.1,0) [-6.4|6.3] "deg"  AFL_AHL
 SG_ LftGFA2XWidthAct : 22|9@0+ (0.1,0) [0|51.1] "deg"  AFL_AHL
 SG_ LftGFA2YWidthAct : 29|6@0+ (0.1,0) [0|6.3] "deg"  AFL_AHL
 SG_ LftGFA2DimAct : 39|7@0+ (1,0) [0|100] "%"  AFL_AHL

BO_ 1539 GlareFreeArea_2_RH_ActualPos: 5 LDM_RH
 SG_ RtGFA2PointXAct : 7|10@0- (0.1,0) [-51.2|51.1] "deg"  AFL_AHL
 SG_ RtGFA2PointYAct : 13|7@0- (0.1,0) [-6.4|6.3] "deg"  AFL_AHL
 SG_ RtGFA2XWidthAct : 22|9@0+ (0.1,0) [0|51.1] "deg"  AFL_AHL
 SG_ RtGFA2YWidthAct : 29|6@0+ (0.1,0) [0|6.3] "deg"  AFL_AHL
 SG_ RtGFA2DimAct : 39|7@0+ (1,0) [0|100] "%"  AFL_AHL

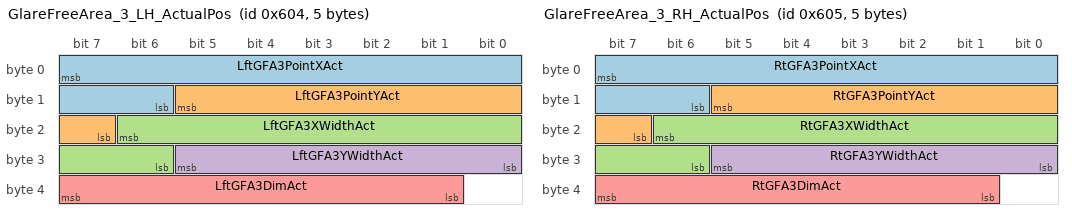
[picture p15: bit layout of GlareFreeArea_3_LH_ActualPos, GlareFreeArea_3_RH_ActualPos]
BO_ 1540 GlareFreeArea_3_LH_ActualPos: 5 LDM_LH
 SG_ LftGFA3PointXAct : 7|10@0- (0.1,0) [-51.2|51.1] "deg"  AFL_AHL
 SG_ LftGFA3PointYAct : 13|7@0- (0.1,0) [-6.4|6.3] "deg"  AFL_AHL
 SG_ LftGFA3XWidthAct : 22|9@0+ (0.1,0) [0|51.1] "deg"  AFL_AHL
 SG_ LftGFA3YWidthAct : 29|6@0+ (0.1,0) [0|6.3] "deg"  AFL_AHL
 SG_ LftGFA3DimAct : 39|7@0+ (1,0) [0|100] "%"  AFL_AHL

BO_ 1541 GlareFreeArea_3_RH_ActualPos: 5 LDM_RH
 SG_ RtGFA3PointXAct : 7|10@0- (0.1,0) [-51.2|51.1] "deg"  AFL_AHL
 SG_ RtGFA3PointYAct : 13|7@0- (0.1,0) [-6.4|6.3] "deg"  AFL_AHL
 SG_ RtGFA3XWidthAct : 22|9@0+ (0.1,0) [0|51.1] "deg"  AFL_AHL
 SG_ RtGFA3YWidthAct : 29|6@0+ (0.1,0) [0|6.3] "deg"  AFL_AHL
 SG_ RtGFA3DimAct : 39|7@0+ (1,0) [0|100] "%"  AFL_AHL

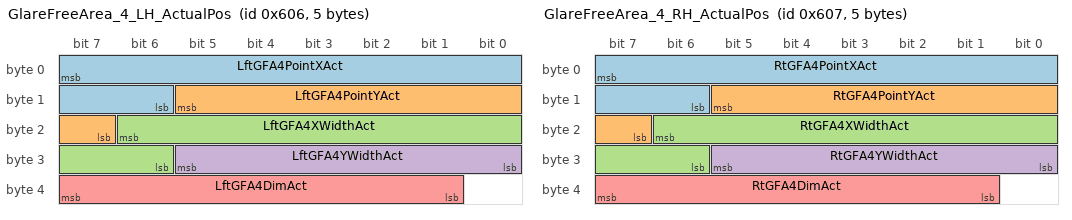
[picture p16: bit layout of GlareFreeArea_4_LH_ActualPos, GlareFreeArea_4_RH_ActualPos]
BO_ 1542 GlareFreeArea_4_LH_ActualPos: 5 LDM_LH
 SG_ LftGFA4PointXAct : 7|10@0- (0.1,0) [-51.2|51.1] "deg"  AFL_AHL
 SG_ LftGFA4PointYAct : 13|7@0- (0.1,0) [-6.4|6.3] "deg"  AFL_AHL
 SG_ LftGFA4XWidthAct : 22|9@0+ (0.1,0) [0|51.1] "deg"  AFL_AHL
 SG_ LftGFA4YWidthAct : 29|6@0+ (0.1,0) [0|6.3] "deg"  AFL_AHL
 SG_ LftGFA4DimAct : 39|7@0+ (1,0) [0|100] "%"  AFL_AHL

BO_ 1543 GlareFreeArea_4_RH_ActualPos: 5 LDM_RH
 SG_ RtGFA4PointXAct : 7|10@0- (0.1,0) [-51.2|51.1] "deg"  AFL_AHL
 SG_ RtGFA4PointYAct : 13|7@0- (0.1,0) [-6.4|6.3] "deg"  AFL_AHL
 SG_ RtGFA4XWidthAct : 22|9@0+ (0.1,0) [0|51.1] "deg"  AFL_AHL
 SG_ RtGFA4YWidthAct : 29|6@0+ (0.1,0) [0|6.3] "deg"  AFL_AHL
 SG_ RtGFA4DimAct : 39|7@0+ (1,0) [0|100] "%"  AFL_AHL

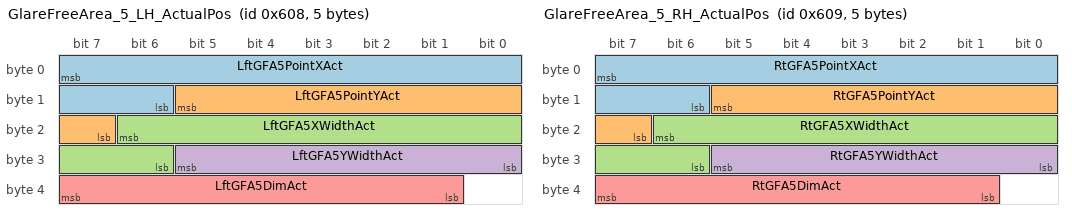
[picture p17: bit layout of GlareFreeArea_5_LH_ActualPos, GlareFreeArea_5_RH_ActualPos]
BO_ 1544 GlareFreeArea_5_LH_ActualPos: 5 LDM_LH
 SG_ LftGFA5PointXAct : 7|10@0- (0.1,0) [-51.2|51.1] "deg"  AFL_AHL
 SG_ LftGFA5PointYAct : 13|7@0- (0.1,0) [-6.4|6.3] "deg"  AFL_AHL
 SG_ LftGFA5XWidthAct : 22|9@0+ (0.1,0) [0|51.1] "deg"  AFL_AHL
 SG_ LftGFA5YWidthAct : 29|6@0+ (0.1,0) [0|6.3] "deg"  AFL_AHL
 SG_ LftGFA5DimAct : 39|7@0+ (1,0) [0|100] "%"  AFL_AHL

BO_ 1545 GlareFreeArea_5_RH_ActualPos: 5 LDM_RH
 SG_ RtGFA5PointXAct : 7|10@0- (0.1,0) [-51.2|51.1] "deg"  AFL_AHL
 SG_ RtGFA5PointYAct : 13|7@0- (0.1,0) [-6.4|6.3] "deg"  AFL_AHL
 SG_ RtGFA5XWidthAct : 22|9@0+ (0.1,0) [0|51.1] "deg"  AFL_AHL
 SG_ RtGFA5YWidthAct : 29|6@0+ (0.1,0) [0|6.3] "deg"  AFL_AHL
 SG_ RtGFA5DimAct : 39|7@0+ (1,0) [0|100] "%"  AFL_AHL

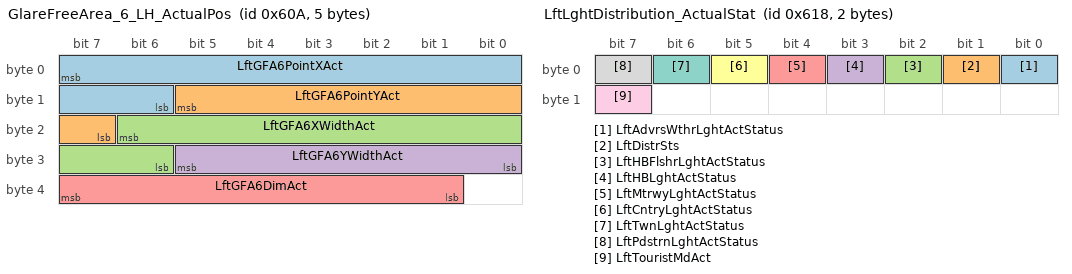
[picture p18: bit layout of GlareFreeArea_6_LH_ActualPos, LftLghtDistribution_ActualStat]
BO_ 1546 GlareFreeArea_6_LH_ActualPos: 5 LDM_LH
 SG_ LftGFA6PointXAct : 7|10@0- (0.1,0) [-51.2|51.1] "deg"  AFL_AHL
 SG_ LftGFA6PointYAct : 13|7@0- (0.1,0) [-6.4|6.3] "deg"  AFL_AHL
 SG_ LftGFA6XWidthAct : 22|9@0+ (0.1,0) [0|51.1] "deg"  AFL_AHL
 SG_ LftGFA6YWidthAct : 29|6@0+ (0.1,0) [0|6.3] "deg"  AFL_AHL
 SG_ LftGFA6DimAct : 39|7@0+ (1,0) [0|100] "%"  AFL_AHL

BO_ 1547 GlareFreeArea_6_RH_ActualPos: 5 LDM_RH
 SG_ RtGFA6PointXAct : 7|10@0- (0.1,0) [-51.2|51.1] "deg"  AFL_AHL
 SG_ RtGFA6PointYAct : 13|7@0- (0.1,0) [-6.4|6.3] "deg"  AFL_AHL
 SG_ RtGFA6XWidthAct : 22|9@0+ (0.1,0) [0|51.1] "deg"  AFL_AHL
 SG_ RtGFA6YWidthAct : 29|6@0+ (0.1,0) [0|6.3] "deg"  AFL_AHL
 SG_ RtGFA6DimAct : 39|7@0+ (1,0) [0|100] "%"  AFL_AHL

BO_ 1552 LftLghtCenterOfGravMov_ActPos: 6 LDM_LH
 SG_ LftLghtCntrWdthLftSdActPos : 7|11@0- (0.1,0) [-102.4|102.3] "LftLghtCntrWdthLftSdActPos_"  AFL_AHL
 SG_ LftLghtCntrWdthRtSdActPos : 23|11@0- (0.1,0) [-102.4|102.3] "LftLghtCntrWdthRtSdActPos"  AFL_AHL
 SG_ LftCntrLghtLvlActPos : 39|8@0+ (0.5,0) [0|127.5] "LftCntrLghtLvlActPos_Units"  AFL_AHL
 SG_ LftBckgrndLghtLvlActPos : 47|8@0+ (0.5,0) [0|127.5] "LftBckgrndLghtLvlActPos_Uni"  AFL_AHL

BO_ 1553 RtLghtCenterOfGravMov_ActPos: 6 LDM_RH
 SG_ RtLghtCntrWdthLftSdActPos : 7|11@0- (0.1,0) [-102.4|102.3] "RtLghtCntrWdthLftSdActPos_"  AFL_AHL
 SG_ RtLghtCntrWdthRtSdActPos : 23|11@0- (0.1,0) [-102.4|102.3] "RtLghtCntrWdthRtSdActPos"  AFL_AHL
 SG_ RtCntrLghtLvlActPos : 39|8@0+ (0.5,0) [0|127.5] "RtCntrLghtLvlActPos_Units"  AFL_AHL
 SG_ RtBckgrndLghtLvlActPos : 47|8@0+ (0.5,0) [0|127.5] "RtBckgrndLghtLvlActPos_Uni"  AFL_AHL

BO_ 1554 LftHdLmpLvlSystmActualPstn: 2 LDM_LH
 SG_ LftDhlPosAct : 7|11@0- (0.01,0) [-10.24|10.23] "%"  AFL_AHL

BO_ 1555 RtHdLmpLvlSystmActualPstn: 2 LDM_RH
 SG_ RtDhlPosAct : 7|11@0- (0.01,0) [-10.24|10.23] "%"  AFL_AHL

BO_ 1556 LftDynamicBendingLightSys_ActPos: 2 LDM_LH
 SG_ LftHdlmpSwvlActAngl : 7|11@0- (0.05,0) [-51.2|51.15] "LH_DBLS_LftHdlmpSwvlActAngl_Unit"  AFL_AHL

BO_ 1557 RtDynamicBendingLightSys_ActPos: 2 LDM_RH
 SG_ RtHdlmpSwvlActAngl : 7|11@0- (0.05,0) [-51.2|51.15] "RH_DBLS_RtHdlmpSwvlActAngl_Uni"  AFL_AHL

BO_ 1558 LftStaticBendingLightSys_ActPos: 1 LDM_LH
 SG_ LftBndDimAct : 7|8@0+ (0.5,0) [0|127.5] "%"  AFL_AHL

BO_ 1559 RtStaticBendingLightSys_ActPos: 1 LDM_RH
 SG_ RtBndDimAct : 7|8@0+ (0.5,0) [0|127.5] "%"  AFL_AHL

BO_ 1560 LftLghtDistribution_ActualStat: 2 LDM_LH
 SG_ LftAdvrsWthrLghtActStatus : 0|1@0+ (1,0) [0|1] ""  AFL_AHL
 SG_ LftDistrSts : 1|1@0+ (1,0) [0|1] ""  AFL_AHL
 SG_ LftHBFlshrLghtActStatus : 2|1@0+ (1,0) [0|1] ""  AFL_AHL
 SG_ LftHBLghtActStatus : 3|1@0+ (1,0) [0|1] ""  AFL_AHL
 SG_ LftMtrwyLghtActStatus : 4|1@0+ (1,0) [0|1] ""  AFL_AHL
 SG_ LftCntryLghtActStatus : 5|1@0+ (1,0) [0|1] ""  AFL_AHL
 SG_ LftTwnLghtActStatus : 6|1@0+ (1,0) [0|1] ""  AFL_AHL
 SG_ LftPdstrnLghtActStatus : 7|1@0+ (1,0) [0|1] ""  AFL_AHL
 SG_ LftTouristMdAct : 15|1@0+ (1,0) [0|1] ""  AFL_AHL

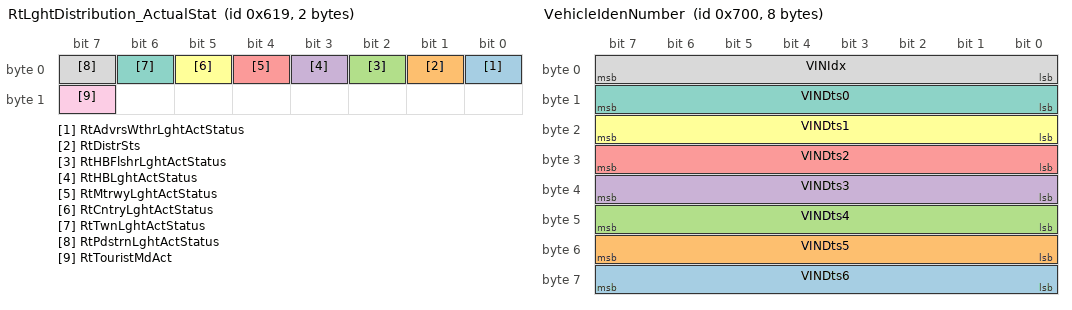
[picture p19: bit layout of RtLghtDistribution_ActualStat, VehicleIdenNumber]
BO_ 1561 RtLghtDistribution_ActualStat: 2 LDM_RH
 SG_ RtAdvrsWthrLghtActStatus : 0|1@0+ (1,0) [0|1] ""  AFL_AHL
 SG_ RtDistrSts : 1|1@0+ (1,0) [0|1] ""  AFL_AHL
 SG_ RtHBFlshrLghtActStatus : 2|1@0+ (1,0) [0|1] ""  AFL_AHL
 SG_ RtHBLghtActStatus : 3|1@0+ (1,0) [0|1] ""  AFL_AHL
 SG_ RtMtrwyLghtActStatus : 4|1@0+ (1,0) [0|1] ""  AFL_AHL
 SG_ RtCntryLghtActStatus : 5|1@0+ (1,0) [0|1] ""  AFL_AHL
 SG_ RtTwnLghtActStatus : 6|1@0+ (1,0) [0|1] ""  AFL_AHL
 SG_ RtPdstrnLghtActStatus : 7|1@0+ (1,0) [0|1] ""  AFL_AHL
 SG_ RtTouristMdAct : 15|1@0+ (1,0) [0|1] ""  AFL_AHL

BO_ 1584 GlareFreeArea_7_LH_ActualPos: 5 LDM_LH
 SG_ LftGFA7PointXAct : 7|10@0- (0.1,0) [-51.2|51.1] "deg"  AFL_AHL
 SG_ LftGFA7PointYAct : 13|7@0- (0.1,0) [-6.4|6.3] "deg"  AFL_AHL
 SG_ LftGFA7XWidthAct : 22|9@0+ (0.1,0) [0|51.1] "deg"  AFL_AHL
 SG_ LftGFA7YWidthAct : 29|6@0+ (0.1,0) [0|6.3] "deg"  AFL_AHL
 SG_ LftGFA7DimAct : 39|7@0+ (1,0) [0|100] "%"  AFL_AHL

BO_ 1585 GlareFreeArea_7_RH_ActualPos: 5 LDM_RH
 SG_ RtGFA7PointXAct : 7|10@0- (0.1,0) [-51.2|51.1] "deg"  AFL_AHL
 SG_ RtGFA7PointYAct : 13|7@0- (0.1,0) [-6.4|6.3] "deg"  AFL_AHL
 SG_ RtGFA7XWidthAct : 22|9@0+ (0.1,0) [0|51.1] "deg"  AFL_AHL
 SG_ RtGFA7YWidthAct : 29|6@0+ (0.1,0) [0|6.3] "deg"  AFL_AHL
 SG_ RtGFA7DimAct : 39|7@0+ (1,0) [0|100] "%"  AFL_AHL

BO_ 1586 GlareFreeArea_8_LH_ActualPos: 5 LDM_LH
 SG_ LftGFA8PointXAct : 7|10@0- (0.1,0) [-51.2|51.1] "deg"  AFL_AHL
 SG_ LftGFA8PointYAct : 13|7@0- (0.1,0) [-6.4|6.3] "deg"  AFL_AHL
 SG_ LftGFA8XWidthAct : 22|9@0+ (0.1,0) [0|51.1] "deg"  AFL_AHL
 SG_ LftGFA8YWidthAct : 29|6@0+ (0.1,0) [0|6.3] "deg"  AFL_AHL
 SG_ LftGFA8DimAct : 39|7@0+ (1,0) [0|100] "%"  AFL_AHL

BO_ 1587 GlareFreeArea_8_RH_ActualPos: 5 LDM_RH
 SG_ RtGFA8PointXAct : 7|10@0- (0.1,0) [-51.2|51.1] "deg"  AFL_AHL
 SG_ RtGFA8PointYAct : 13|7@0- (0.1,0) [-6.4|6.3] "deg"  AFL_AHL
 SG_ RtGFA8XWidthAct : 22|9@0+ (0.1,0) [0|51.1] "deg"  AFL_AHL
 SG_ RtGFA8YWidthAct : 29|6@0+ (0.1,0) [0|6.3] "deg"  AFL_AHL
 SG_ RtGFA8DimAct : 39|7@0+ (1,0) [0|100] "%"  AFL_AHL

BO_ 1588 GlareFreeArea_9_LH_ActualPos: 5 LDM_LH
 SG_ LftGFA9PointXAct : 7|10@0- (0.1,0) [-51.2|51.1] "deg"  AFL_AHL
 SG_ LftGFA9PointYAct : 13|7@0- (0.1,0) [-6.4|6.3] "deg"  AFL_AHL
 SG_ LftGFA9XWidthAct : 22|9@0+ (0.1,0) [0|51.1] "deg"  AFL_AHL
 SG_ LftGFA9YWidthAct : 29|6@0+ (0.1,0) [0|6.3] "deg"  AFL_AHL
 SG_ LftGFA9DimAct : 39|7@0+ (1,0) [0|100] "%"  AFL_AHL

BO_ 1589 GlareFreeArea_9_RH_ActualPos: 5 LDM_RH
 SG_ RtGFA9PointXAct : 7|10@0- (0.1,0) [-51.2|51.1] "deg"  AFL_AHL
 SG_ RtGFA9PointYAct : 13|7@0- (0.1,0) [-6.4|6.3] "deg"  AFL_AHL
 SG_ RtGFA9XWidthAct : 22|9@0+ (0.1,0) [0|51.1] "deg"  AFL_AHL
 SG_ RtGFA9YWidthAct : 29|6@0+ (0.1,0) [0|6.3] "deg"  AFL_AHL
 SG_ RtGFA9DimAct : 39|7@0+ (1,0) [0|100] "%"  AFL_AHL

BO_ 1590 GlareFreeArea_10_LH_ActualPos: 5 LDM_LH
 SG_ LftGFA10PointXAct : 7|10@0- (0.1,0) [-51.2|51.1] "deg"  AFL_AHL
 SG_ LftGFA10PointYAct : 13|7@0- (0.1,0) [-6.4|6.3] "deg"  AFL_AHL
 SG_ LftGFA10XWidthAct : 22|9@0+ (0.1,0) [0|51.1] "deg"  AFL_AHL
 SG_ LftGFA10YWidthAct : 29|6@0+ (0.1,0) [0|6.3] "deg"  AFL_AHL
 SG_ LftGFA10DimAct : 39|7@0+ (1,0) [0|100] "%"  AFL_AHL

BO_ 1591 GlareFreeArea_10_RH_ActualPos: 5 LDM_RH
 SG_ RtGFA10PointXAct : 7|10@0- (0.1,0) [-51.2|51.1] "deg"  AFL_AHL
 SG_ RtGFA10PointYAct : 13|7@0- (0.1,0) [-6.4|6.3] "deg"  AFL_AHL
 SG_ RtGFA10XWidthAct : 22|9@0+ (0.1,0) [0|51.1] "deg"  AFL_AHL
 SG_ RtGFA10YWidthAct : 29|6@0+ (0.1,0) [0|6.3] "deg"  AFL_AHL
 SG_ RtGFA10DimAct : 39|7@0+ (1,0) [0|100] "%"  AFL_AHL

BO_ 1592 GlareFreeArea_11_LH_ActualPos: 5 LDM_LH
 SG_ LftGFA11PointXAct : 7|10@0- (0.1,0) [-51.2|51.1] "deg"  AFL_AHL
 SG_ LftGFA11PointYAct : 13|7@0- (0.1,0) [-6.4|6.3] "deg"  AFL_AHL
 SG_ LftGFA11XWidthAct : 22|9@0+ (0.1,0) [0|51.1] "deg"  AFL_AHL
 SG_ LftGFA11YWidthAct : 29|6@0+ (0.1,0) [0|6.3] "deg"  AFL_AHL
 SG_ LftGFA11DimAct : 39|7@0+ (1,0) [0|100] "%"  AFL_AHL

BO_ 1593 GlareFreeArea_11_RH_ActualPos: 5 LDM_RH
 SG_ RtGFA11PointXAct : 7|10@0- (0.1,0) [-51.2|51.1] "deg"  AFL_AHL
 SG_ RtGFA11PointYAct : 13|7@0- (0.1,0) [-6.4|6.3] "deg"  AFL_AHL
 SG_ RtGFA11XWidthAct : 22|9@0+ (0.1,0) [0|51.1] "deg"  AFL_AHL
 SG_ RtGFA11YWidthAct : 29|6@0+ (0.1,0) [0|6.3] "deg"  AFL_AHL
 SG_ RtGFA11DimAct : 39|7@0+ (1,0) [0|100] "%"  AFL_AHL

BO_ 1594 GlareFreeArea_12_LH_ActualPos: 5 LDM_LH
 SG_ LftGFA12PointXAct : 7|10@0- (0.1,0) [-51.2|51.1] "deg"  AFL_AHL
 SG_ LftGFA12PointYAct : 13|7@0- (0.1,0) [-6.4|6.3] "deg"  AFL_AHL
 SG_ LftGFA12XWidthAct : 22|9@0+ (0.1,0) [0|51.1] "deg"  AFL_AHL
 SG_ LftGFA12YWidthAct : 29|6@0+ (0.1,0) [0|6.3] "deg"  AFL_AHL
 SG_ LftGFA12DimAct : 39|7@0+ (1,0) [0|100] "%"  AFL_AHL

BO_ 1595 GlareFreeArea_12_RH_ActualPos: 5 LDM_RH
 SG_ RtGFA12PointXAct : 7|10@0- (0.1,0) [-51.2|51.1] "deg"  AFL_AHL
 SG_ RtGFA12PointYAct : 13|7@0- (0.1,0) [-6.4|6.3] "deg"  AFL_AHL
 SG_ RtGFA12XWidthAct : 22|9@0+ (0.1,0) [0|51.1] "deg"  AFL_AHL
 SG_ RtGFA12YWidthAct : 29|6@0+ (0.1,0) [0|6.3] "deg"  AFL_AHL
 SG_ RtGFA12DimAct : 39|7@0+ (1,0) [0|100] "%"  AFL_AHL

BO_ 1792 VehicleIdenNumber: 8 AFL_AHL
 SG_ VINDts6 : 63|8@0+ (1,0) [0|0] "VIN_6_Units"  LDM_RH,LDM_LH
 SG_ VINDts5 : 55|8@0+ (1,0) [0|0] "VIN_5_Units"  LDM_RH,LDM_LH
 SG_ VINDts4 : 47|8@0+ (1,0) [0|0] "VIN_4_Units"  LDM_RH,LDM_LH
 SG_ VINDts3 : 39|8@0+ (1,0) [0|0] "VIN_3_Units"  LDM_RH,LDM_LH
 SG_ VINDts2 : 31|8@0+ (1,0) [0|0] "VIN_2_Units"  LDM_RH,LDM_LH
 SG_ VINDts1 : 23|8@0+ (1,0) [0|0] "VIN_1_Units"  LDM_RH,LDM_LH
 SG_ VINDts0 : 15|8@0+ (1,0) [0|0] ""  LDM_RH,LDM_LH
 SG_ VINIdx : 7|8@0+ (1,0) [0|255] ""  LDM_RH,LDM_LH

CM_ SG_ 515 DistrCksm "Light Distribution System Information : Light Distribution Cksm";
CM_ SG_ 515 RtCntryLghtDstrbtn "Light Distribution System Information : Right Headlamp Country Light Distribution";
CM_ SG_ 515 LftCntryLghtDstrbtn "Light Distribution System Information : Left Headlamp Country Light Distribution";
CM_ SG_ 515 RtAdvrsWthrLghtDstrbtn "Light Distribution System Information : Right Headlamp Adverse Weather Light Distribution";
CM_ SG_ 515 LftAdvrsWthrLghtDstrbtn "Light Distribution System Information : Left Headlamp Adverse Weather Light Distribution";
CM_ SG_ 515 DistrArc "Light Distribution System Information : Light Distribution Message Counter";
CM_ SG_ 515 RtGFHBLghtDstrbtnMtrwyLvl "Light Distribution System Information : Right Headlamp Glare Free High Beam Light Distribution Motorway Level 1";
CM_ SG_ 515 RtDistrGFHB "Light Distribution System Information : Right Headlamp Glare Free High Beam Light Distribution";
CM_ SG_ 515 LftGFHBLghtDstrbtnMtrwyLvl "Light Distribution System Information : Left Headlamp Glare Free High Beam Light Distribution Motorway Level 1";
CM_ SG_ 515 LftDistrGFHB "Light Distribution System Information : Left Headlamp Glare Free High Beam Light Distribution";
CM_ SG_ 515 LftMtrwyLghtDstrbtnLvl "Light Distribution System Information : Left Headlamp Motorway Light Distribution Level E1";
CM_ SG_ 515 RtMtrwyLghtDstrbtnLvl "Light Distribution System Information : Left Headlamp Motorway Light Distribution Level E0";
CM_ SG_ 515 RtHBLghtDstrbtn "Light Distribution System Information : Right Headlamp High Beam Light Distribution";
CM_ SG_ 515 LftHBLghtDstrbtn "Light Distribution System Information : Left Headlamp High Beam Light Distribution";
CM_ SG_ 515 RtHBFlshrLghtDstrbtn "Light Distribution System Information : Right Headlamp High Beam Flasher Light Distribution";
CM_ SG_ 515 LftHBFlshrLghtDstrbtn "Light Distribution System Information : Left Headlamp High Beam Flasher Light Distribution";
CM_ SG_ 515 RtTwnLghtDstrbtn "Light Distribution System Information : Right Headlamp Town Light Distribution";
CM_ SG_ 515 LftTwnLghtDstrbtn "Light Distribution System Information : Left Headlamp Town Light Distribution";
CM_ SG_ 515 RtPdstrnLghtDstrbtn "Light Distribution System Information : Right Headlamp Pedestrian Light Distribution";
CM_ SG_ 515 LftPdstrnLghtDstrbtn "Light Distribution System Information : Left Headlamp Pedestrian Light Distribution";
CM_ SG_ 258 LftGFA1Cksm "Glare Free Area 1 Left Headlamp Information : Left Headlamp Glare Free Area 1 Cksm";
CM_ SG_ 258 LftGFA1PointX "Glare Free Area 1 Left Headlamp Information : Left Headlamp Glare Free Area 1 Center Horizontal Position";
CM_ SG_ 258 LftGFA1MsgCnt "Glare Free Area 1 Left Headlamp Information : Left Headlamp Glare Free Area 1 Message Counter";
CM_ SG_ 258 LftGFA1PointY "Glare Free Area 1 Left Headlamp Information : Left Headlamp Glare Free Area 1 Center Vertical Position";
CM_ SG_ 258 LftGFA1XWidth "Glare Free Area 1 Left Headlamp Information : Left Headlamp Glare Free Area 1 Horizontal Half Width";
CM_ SG_ 258 LftGFA1YWidth "Glare Free Area 1 Left Headlamp Information : Left Headlamp Glare Free Area 1 Vertical Half Width";
CM_ SG_ 258 LftGFA1Dim "Glare Free Area 1 Left Headlamp Information : Left Headlamp Glare Free Area 1 Dim Value";
CM_ SG_ 258 LftGFA1LghtOnTmr "Glare Free Area 1 Left Headlamp Information : Left Headlamp Glare Free Area 1 Dim Up Time";
CM_ SG_ 258 LftGFA1LghtOffTmr "Glare Free Area 1 Left Headlamp Information : Left Headlamp Glare Free Area 1 Dim Down Time";
CM_ SG_ 259 RtGFA1Cksm "Glare Free Area 1 Right Headlamp Information : Right Headlamp Glare Free Area 1 Cksm";
CM_ SG_ 259 RtGFA1PointX "Glare Free Area 1 Right Headlamp Information : Right Headlamp Glare Free Area 1 Center Horizontal Position";
CM_ SG_ 259 RtGFA1MsgCnt "Glare Free Area 1 Right Headlamp Information : Right Headlamp Glare Free Area 1 Message Counter";
CM_ SG_ 259 RtGFA1PointY "Glare Free Area 1 Right Headlamp Information : Right Headlamp Glare Free Area 1 Center Vertical Position";
CM_ SG_ 259 RtGFA1XWidth "Glare Free Area 1 Right Headlamp Information : Right Headlamp Glare Free Area 1 Horizontal Half Width";
CM_ SG_ 259 RtGFA1YWidth "Glare Free Area 1 Right Headlamp Information : Right Headlamp Glare Free Area 1 Vertical Half Width";
CM_ SG_ 259 RtGFA1Dim "Glare Free Area 1 Right Headlamp Information : Right Headlamp Glare Free Area 1 Dim Value";
CM_ SG_ 259 RtGFA1LghtOnTmr "Glare Free Area 1 Right Headlamp Information : Right Headlamp Glare Free Area 1 Dim Up Time";
CM_ SG_ 259 RtGFA1LghtOffTmr "Glare Free Area 1 Right Headlamp Information : Right Headlamp Glare Free Area 1 Dim Down Time";
CM_ SG_ 260 LftGFA2Cksm "Glare Free Area 2 Left Headlamp Information : Left Headlamp Glare Free Area 2 Cksm";
CM_ SG_ 260 LftGFA2PointX "Glare Free Area 2 Left Headlamp Information : Left Headlamp Glare Free Area 2 Center Horizontal Position";
CM_ SG_ 260 LftGFA2MsgCnt "Glare Free Area 2 Left Headlamp Information : Left Headlamp Glare Free Area 2 Message Counter";
CM_ SG_ 260 LftGFA2PointY "Glare Free Area 2 Left Headlamp Information : Left Headlamp Glare Free Area 2 Center Vertical Position";
CM_ SG_ 260 LftGFA2XWidth "Glare Free Area 2 Left Headlamp Information : Left Headlamp Glare Free Area 2 Horizontal Half Width";
CM_ SG_ 260 LftGFA2YWidth "Glare Free Area 2 Left Headlamp Information : Left Headlamp Glare Free Area 2 Vertical Half Width";
CM_ SG_ 260 LftGFA2Dim "Glare Free Area 2 Left Headlamp Information : Left Headlamp Glare Free Area 2 Dim Value";
CM_ SG_ 260 LftGFA2LghtOnTmr "Glare Free Area 2 Left Headlamp Information : Left Headlamp Glare Free Area 2 Dim Up Time";
CM_ SG_ 260 LftGFA2LghtOffTmr "Glare Free Area 2 Left Headlamp Information : Left Headlamp Glare Free Area 2 Dim Down Time";
CM_ SG_ 261 RtGFA2Cksm "Glare Free Area 2 Right Headlamp Information : Right Headlamp Glare Free Area 2 Cksm";
CM_ SG_ 261 RtGFA2PointX "Glare Free Area 2 Right Headlamp Information : Right Headlamp Glare Free Area 2 Center Horizontal Position";
CM_ SG_ 261 RtGFA2MsgCnt "Glare Free Area 2 Right Headlamp Information : Right Headlamp Glare Free Area 2 Message Counter";
CM_ SG_ 261 RtGFA2PointY "Glare Free Area 2 Right Headlamp Information : Right Headlamp Glare Free Area 2 Center Vertical Position";
CM_ SG_ 261 RtGFA2XWidth "Glare Free Area 2 Right Headlamp Information : Right Headlamp Glare Free Area 2 Horizontal Half Width";
CM_ SG_ 261 RtGFA2YWidth "Glare Free Area 2 Right Headlamp Information : Right Headlamp Glare Free Area 2 Vertical Half Width";
CM_ SG_ 261 RtGFA2Dim "Glare Free Area 2 Right Headlamp Information : Right Headlamp Glare Free Area 2 Dim Value";
CM_ SG_ 261 RtGFA2LghtOnTmr "Glare Free Area 2 Right Headlamp Information : Right Headlamp Glare Free Area 2 Dim Up Time";
CM_ SG_ 261 RtGFA2LghtOffTmr "Glare Free Area 2 Right Headlamp Information : Right Headlamp Glare Free Area 2 Dim Down Time";
CM_ SG_ 262 LftGFA3Cksm "Glare Free Area 3 Left Headlamp Information : Left Headlamp Glare Free Area 3 Cksm";
CM_ SG_ 262 LftGFA3PointX "Glare Free Area 3 Left Headlamp Information : Left Headlamp Glare Free Area 3 Center Horizontal Position";
CM_ SG_ 262 LftGFA3MsgCnt "Glare Free Area 3 Left Headlamp Information : Left Headlamp Glare Free Area 3 Message Counter";
CM_ SG_ 262 LftGFA3PointY "Glare Free Area 3 Left Headlamp Information : Left Headlamp Glare Free Area 3 Center Vertical Position";
CM_ SG_ 262 LftGFA3XWidth "Glare Free Area 3 Left Headlamp Information : Left Headlamp Glare Free Area 3 Horizontal Half Width";
CM_ SG_ 262 LftGFA3YWidth "Glare Free Area 3 Left Headlamp Information : Left Headlamp Glare Free Area 3 Vertical Half Width";
CM_ SG_ 262 LftGFA3Dim "Glare Free Area 3 Left Headlamp Information : Left Headlamp Glare Free Area 3 Dim Value";
CM_ SG_ 262 LftGFA3LghtOnTmr "Glare Free Area 3 Left Headlamp Information : Left Headlamp Glare Free Area 3 Dim Up Time";
CM_ SG_ 262 LftGFA3LghtOffTmr "Glare Free Area 3 Left Headlamp Information : Left Headlamp Glare Free Area 3 Dim Down Time";
CM_ SG_ 263 RtGFA3Cksm "Glare Free Area 3 Right Headlamp Information : Right Headlamp Glare Free Area 3 Cksm";
CM_ SG_ 263 RtGFA3PointX "Glare Free Area 3 Right Headlamp Information : Right Headlamp Glare Free Area 3 Center Horizontal Position";
CM_ SG_ 263 RtGFA3MsgCnt "Glare Free Area 3 Right Headlamp Information : Right Headlamp Glare Free Area 3 Message Counter";
CM_ SG_ 263 RtGFA3PointY "Glare Free Area 3 Right Headlamp Information : Right Headlamp Glare Free Area 3 Center Vertical Position";
CM_ SG_ 263 RtGFA3XWidth "Glare Free Area 3 Right Headlamp Information : Right Headlamp Glare Free Area 3 Horizontal Half Width";
CM_ SG_ 263 RtGFA3YWidth "Glare Free Area 3 Right Headlamp Information : Right Headlamp Glare Free Area 3 Vertical Half Width";
CM_ SG_ 263 RtGFA3Dim "Glare Free Area 3 Right Headlamp Information : Right Headlamp Glare Free Area 3 Dim Value";
CM_ SG_ 263 RtGFA3LghtOnTmr "Glare Free Area 3 Right Headlamp Information : Right Headlamp Glare Free Area 3 Dim Up Time";
CM_ SG_ 263 RtGFA3LghtOffTmr "Glare Free Area 3 Right Headlamp Information : Right Headlamp Glare Free Area 3 Dim Down Time";
CM_ SG_ 264 LftGFA4Cksm "Glare Free Area 4 Left Headlamp Information : Left Headlamp Glare Free Area 4 Cksm";
CM_ SG_ 264 LftGFA4PointX "Glare Free Area 4 Left Headlamp Information : Left Headlamp Glare Free Area 4 Center Horizontal Position";
CM_ SG_ 264 LftGFA4MsgCnt "Glare Free Area 4 Left Headlamp Information : Left Headlamp Glare Free Area 4 Message Counter";
CM_ SG_ 264 LftGFA4PointY "Glare Free Area 4 Left Headlamp Information : Left Headlamp Glare Free Area 4 Center Vertical Position";
CM_ SG_ 264 LftGFA4XWidth "Glare Free Area 4 Left Headlamp Information : Left Headlamp Glare Free Area 4 Horizontal Half Width";
CM_ SG_ 264 LftGFA4YWidth "Glare Free Area 4 Left Headlamp Information : Left Headlamp Glare Free Area 4 Vertical Half Width";
CM_ SG_ 264 LftGFA4Dim "Glare Free Area 4 Left Headlamp Information : Left Headlamp Glare Free Area 4 Dim Value";
CM_ SG_ 264 LftGFA4LghtOnTmr "Glare Free Area 4 Left Headlamp Information : Left Headlamp Glare Free Area 4 Dim Up Time";
CM_ SG_ 264 LftGFA4LghtOffTmr "Glare Free Area 4 Left Headlamp Information : Left Headlamp Glare Free Area 4 Dim Down Time";
CM_ SG_ 265 RtGFA4Cksm "Glare Free Area 4 Right Headlamp Information : Right Headlamp Glare Free Area 4 Cksm";
CM_ SG_ 265 RtGFA4PointX "Glare Free Area 4 Right Headlamp Information : Right Headlamp Glare Free Area 4 Center Horizontal Position";
CM_ SG_ 265 RtGFA4MsgCnt "Glare Free Area 4 Right Headlamp Information : Right Headlamp Glare Free Area 4 Message Counter";
CM_ SG_ 265 RtGFA4PointY "Glare Free Area 4 Right Headlamp Information : Right Headlamp Glare Free Area 4 Center Vertical Position";
CM_ SG_ 265 RtGFA4XWidth "Glare Free Area 4 Right Headlamp Information : Right Headlamp Glare Free Area 4 Horizontal Half Width";
CM_ SG_ 265 RtGFA4YWidth "Glare Free Area 4 Right Headlamp Information : Right Headlamp Glare Free Area 4 Vertical Half Width";
CM_ SG_ 265 RtGFA4Dim "Glare Free Area 4 Right Headlamp Information : Right Headlamp Glare Free Area 4 Dim Value";
CM_ SG_ 265 RtGFA4LghtOnTmr "Glare Free Area 4 Right Headlamp Information : Right Headlamp Glare Free Area 4 Dim Up Time";
CM_ SG_ 265 RtGFA4LghtOffTmr "Glare Free Area 4 Right Headlamp Information : Right Headlamp Glare Free Area 4 Dim Down Time";
CM_ SG_ 266 LftGFA5Cksm "Glare Free Area 5 Left Headlamp Information : Left Headlamp Glare Free Area 5 Cksm";
CM_ SG_ 266 LftGFA5PointX "Glare Free Area 5 Left Headlamp Information : Left Headlamp Glare Free Area 5 Center Horizontal Position";
CM_ SG_ 266 LftGFA5MsgCnt "Glare Free Area 5 Left Headlamp Information : Left Headlamp Glare Free Area 5 Message Counter";
CM_ SG_ 266 LftGFA5PointY "Glare Free Area 5 Left Headlamp Information : Left Headlamp Glare Free Area 5 Center Vertical Position";
CM_ SG_ 266 LftGFA5XWidth "Glare Free Area 5 Left Headlamp Information : Left Headlamp Glare Free Area 5 Horizontal Half Width";
CM_ SG_ 266 LftGFA5YWidth "Glare Free Area 5 Left Headlamp Information : Left Headlamp Glare Free Area 5 Vertical Half Width";
CM_ SG_ 266 LftGFA5Dim "Glare Free Area 5 Left Headlamp Information : Left Headlamp Glare Free Area 5 Dim Value";
CM_ SG_ 266 LftGFA5LghtOnTmr "Glare Free Area 5 Left Headlamp Information : Left Headlamp Glare Free Area 5 Dim Up Time";
CM_ SG_ 266 LftGFA5LghtOffTmr "Glare Free Area 5 Left Headlamp Information : Left Headlamp Glare Free Area 5 Dim Down Time";
CM_ SG_ 267 RtGFA5Cksm "Glare Free Area 5 Right Headlamp Information : Right Headlamp Glare Free Area 5 Cksm";
CM_ SG_ 267 RtGFA5PointX "Glare Free Area 5 Right Headlamp Information : Right Headlamp Glare Free Area 5 Center Horizontal Position";
CM_ SG_ 267 RtGFA5MsgCnt "Glare Free Area 5 Right Headlamp Information : Right Headlamp Glare Free Area 5 Message Counter";
CM_ SG_ 267 RtGFA5PointY "Glare Free Area 5 Right Headlamp Information : Right Headlamp Glare Free Area 5 Center Vertical Position";
CM_ SG_ 267 RtGFA5XWidth "Glare Free Area 5 Right Headlamp Information : Right Headlamp Glare Free Area 5 Horizontal Half Width";
CM_ SG_ 267 RtGFA5YWidth "Glare Free Area 5 Right Headlamp Information : Right Headlamp Glare Free Area 5 Vertical Half Width";
CM_ SG_ 267 RtGFA5Dim "Glare Free Area 5 Right Headlamp Information : Right Headlamp Glare Free Area 5 Dim Value";
CM_ SG_ 267 RtGFA5LghtOnTmr "Glare Free Area 5 Right Headlamp Information : Right Headlamp Glare Free Area 5 Dim Up Time";
CM_ SG_ 267 RtGFA5LghtOffTmr "Glare Free Area 5 Right Headlamp Information : Right Headlamp Glare Free Area 5 Dim Down Time";
CM_ SG_ 268 LftGFA6Cksm "Glare Free Area 6 Left Headlamp Information : Left Headlamp Glare Free Area 6 Cksm";
CM_ SG_ 268 LftGFA6PointX "Glare Free Area 6 Left Headlamp Information : Left Headlamp Glare Free Area 6 Center Horizontal Position";
CM_ SG_ 268 LftGFA6MsgCnt "Glare Free Area 6 Left Headlamp Information : Left Headlamp Glare Free Area 6 Message Counter";
CM_ SG_ 268 LftGFA6PointY "Glare Free Area 6 Left Headlamp Information : Left Headlamp Glare Free Area 6 Center Vertical Position";
CM_ SG_ 268 LftGFA6XWidth "Glare Free Area 6 Left Headlamp Information : Left Headlamp Glare Free Area 6 Horizontal Half Width";
CM_ SG_ 268 LftGFA6YWidth "Glare Free Area 6 Left Headlamp Information : Left Headlamp Glare Free Area 6 Vertical Half Width";
CM_ SG_ 268 LftGFA6Dim "Glare Free Area 6 Left Headlamp Information : Left Headlamp Glare Free Area 6 Dim Value";
CM_ SG_ 268 LftGFA6LghtOnTmr "Glare Free Area 6 Left Headlamp Information : Left Headlamp Glare Free Area 6 Dim Up Time";
CM_ SG_ 268 LftGFA6LghtOffTmr "Glare Free Area 6 Left Headlamp Information : Left Headlamp Glare Free Area 6 Dim Down Time";
CM_ SG_ 269 RtGFA6Cksm "Glare Free Area 6 Right Headlamp Information : Right Headlamp Glare Free Area 6 Cksm";
CM_ SG_ 269 RtGFA6PointX "Glare Free Area 6 Right Headlamp Information : Right Headlamp Glare Free Area 6 Center Horizontal Position";
CM_ SG_ 269 RtGFA6MsgCnt "Glare Free Area 6 Right Headlamp Information : Right Headlamp Glare Free Area 6 Message Counter";
CM_ SG_ 269 RtGFA6PointY "Glare Free Area 6 Right Headlamp Information : Right Headlamp Glare Free Area 6 Center Vertical Position";
CM_ SG_ 269 RtGFA6XWidth "Glare Free Area 6 Right Headlamp Information : Right Headlamp Glare Free Area 6 Horizontal Half Width";
CM_ SG_ 269 RtGFA6YWidth "Glare Free Area 6 Right Headlamp Information : Right Headlamp Glare Free Area 6 Vertical Half Width";
CM_ SG_ 269 RtGFA6Dim "Glare Free Area 6 Right Headlamp Information : Right Headlamp Glare Free Area 6 Dim Value";
CM_ SG_ 269 RtGFA6LghtOnTmr "Glare Free Area 6 Right Headlamp Information : Right Headlamp Glare Free Area 6 Dim Up Time";
CM_ SG_ 269 RtGFA6LghtOffTmr "Glare Free Area 6 Right Headlamp Information : Right Headlamp Glare Free Area 6 Dim Down Time";
CM_ SG_ 270 LftGFA7Cksm "Glare Free Area 7 Left Headlamp Information : Left Headlamp Glare Free Area 7 Cksm";
CM_ SG_ 270 LftGFA7PointX "Glare Free Area 7 Left Headlamp Information : Left Headlamp Glare Free Area 7 Center Horizontal Position";
CM_ SG_ 270 LftGFA7MsgCnt "Glare Free Area 7 Left Headlamp Information : Left Headlamp Glare Free Area 7 Message Counter";
CM_ SG_ 270 LftGFA7PointY "Glare Free Area 7 Left Headlamp Information : Left Headlamp Glare Free Area 7 Center Vertical Position";
CM_ SG_ 270 LftGFA7XWidth "Glare Free Area 7 Left Headlamp Information : Left Headlamp Glare Free Area 7 Horizontal Half Width";
CM_ SG_ 270 LftGFA7YWidth "Glare Free Area 7 Left Headlamp Information : Left Headlamp Glare Free Area 7 Vertical Half Width";
CM_ SG_ 270 LftGFA7Dim "Glare Free Area 7 Left Headlamp Information : Left Headlamp Glare Free Area 7 Dim Value";
CM_ SG_ 270 LftGFA7LghtOnTmr "Glare Free Area 7 Left Headlamp Information : Left Headlamp Glare Free Area 7 Dim Up Time";
CM_ SG_ 270 LftGFA7LghtOffTmr "Glare Free Area 7 Left Headlamp Information : Left Headlamp Glare Free Area 7 Dim Down Time";
CM_ SG_ 271 RtGFA7Cksm "Glare Free Area 7 Right Headlamp Information : Right Headlamp Glare Free Area 7 Cksm";
CM_ SG_ 271 RtGFA7PointX "Glare Free Area 7 Right Headlamp Information : Right Headlamp Glare Free Area 7 Center Horizontal Position";
CM_ SG_ 271 RtGFA7MsgCnt "Glare Free Area 7 Right Headlamp Information : Right Headlamp Glare Free Area 7 Message Counter";
CM_ SG_ 271 RtGFA7PointY "Glare Free Area 7 Right Headlamp Information : Right Headlamp Glare Free Area 7 Center Vertical Position";
CM_ SG_ 271 RtGFA7XWidth "Glare Free Area 7 Right Headlamp Information : Right Headlamp Glare Free Area 7 Horizontal Half Width";
CM_ SG_ 271 RtGFA7YWidth "Glare Free Area 7 Right Headlamp Information : Right Headlamp Glare Free Area 7 Vertical Half Width";
CM_ SG_ 271 RtGFA7Dim "Glare Free Area 7 Right Headlamp Information : Right Headlamp Glare Free Area 7 Dim Value";
CM_ SG_ 271 RtGFA7LghtOnTmr "Glare Free Area 7 Right Headlamp Information : Right Headlamp Glare Free Area 7 Dim Up Time";
CM_ SG_ 271 RtGFA7LghtOffTmr "Glare Free Area 7 Right Headlamp Information : Right Headlamp Glare Free Area 7 Dim Down Time";
CM_ SG_ 272 LftGFA8Cksm "Glare Free Area 8 Left Headlamp Information : Left Headlamp Glare Free Area 8 Cksm";
CM_ SG_ 272 LftGFA8PointX "Glare Free Area 8 Left Headlamp Information : Left Headlamp Glare Free Area 8 Center Horizontal Position";
CM_ SG_ 272 LftGFA8MsgCnt "Glare Free Area 8 Left Headlamp Information : Left Headlamp Glare Free Area 8 Message Counter";
CM_ SG_ 272 LftGFA8PointY "Glare Free Area 8 Left Headlamp Information : Left Headlamp Glare Free Area 8 Center Vertical Position";
CM_ SG_ 272 LftGFA8XWidth "Glare Free Area 8 Left Headlamp Information : Left Headlamp Glare Free Area 8 Horizontal Half Width";
CM_ SG_ 272 LftGFA8YWidth "Glare Free Area 8 Left Headlamp Information : Left Headlamp Glare Free Area 8 Vertical Half Width";
CM_ SG_ 272 LftGFA8Dim "Glare Free Area 8 Left Headlamp Information : Left Headlamp Glare Free Area 8 Dim Value";
CM_ SG_ 272 LftGFA8LghtOnTmr "Glare Free Area 8 Left Headlamp Information : Left Headlamp Glare Free Area 8 Dim Up Time";
CM_ SG_ 272 LftGFA8LghtOffTmr "Glare Free Area 8 Left Headlamp Information : Left Headlamp Glare Free Area 8 Dim Down Time";
CM_ SG_ 273 RtGFA8Cksm "Glare Free Area 8 Right Headlamp Information : Right Headlamp Glare Free Area 8 Cksm";
CM_ SG_ 273 RtGFA8PointX "Glare Free Area 8 Right Headlamp Information : Right Headlamp Glare Free Area 8 Center Horizontal Position";
CM_ SG_ 273 RtGFA8MsgCnt "Glare Free Area 8 Right Headlamp Information : Right Headlamp Glare Free Area 8 Message Counter";
CM_ SG_ 273 RtGFA8PointY "Glare Free Area 8 Right Headlamp Information : Right Headlamp Glare Free Area 8 Center Vertical Position";
CM_ SG_ 273 RtGFA8XWidth "Glare Free Area 8 Right Headlamp Information : Right Headlamp Glare Free Area 8 Horizontal Half Width";
CM_ SG_ 273 RtGFA8YWidth "Glare Free Area 8 Right Headlamp Information : Right Headlamp Glare Free Area 8 Vertical Half Width";
CM_ SG_ 273 RtGFA8Dim "Glare Free Area 8 Right Headlamp Information : Right Headlamp Glare Free Area 8 Dim Value";
CM_ SG_ 273 RtGFA8LghtOnTmr "Glare Free Area 8 Right Headlamp Information : Right Headlamp Glare Free Area 8 Dim Up Time";
CM_ SG_ 273 RtGFA8LghtOffTmr "Glare Free Area 8 Right Headlamp Information : Right Headlamp Glare Free Area 8 Dim Down Time";
CM_ SG_ 274 LftGFA9Cksm "Glare Free Area 9 Left Headlamp Information : Left Headlamp Glare Free Area 9 Cksm";
CM_ SG_ 274 LftGFA9PointX "Glare Free Area 9 Left Headlamp Information : Left Headlamp Glare Free Area 9 Center Horizontal Position";
CM_ SG_ 274 LftGFA9MsgCnt "Glare Free Area 9 Left Headlamp Information : Left Headlamp Glare Free Area 9 Message Counter";
CM_ SG_ 274 LftGFA9PointY "Glare Free Area 9 Left Headlamp Information : Left Headlamp Glare Free Area 9 Center Vertical Position";
CM_ SG_ 274 LftGFA9XWidth "Glare Free Area 9 Left Headlamp Information : Left Headlamp Glare Free Area 9 Horizontal Half Width";
CM_ SG_ 274 LftGFA9YWidth "Glare Free Area 9 Left Headlamp Information : Left Headlamp Glare Free Area 9 Vertical Half Width";
CM_ SG_ 274 LftGFA9Dim "Glare Free Area 9 Left Headlamp Information : Left Headlamp Glare Free Area 9 Dim Value";
CM_ SG_ 274 LftGFA9LghtOnTmr "Glare Free Area 9 Left Headlamp Information : Left Headlamp Glare Free Area 9 Dim Up Time";
CM_ SG_ 274 LftGFA9LghtOffTmr "Glare Free Area 9 Left Headlamp Information : Left Headlamp Glare Free Area 9 Dim Down Time";
CM_ SG_ 275 RtGFA9Cksm "Glare Free Area 9 Right Headlamp Information : Right Headlamp Glare Free Area 9 Cksm";
CM_ SG_ 275 RtGFA9PointX "Glare Free Area 9 Right Headlamp Information : Right Headlamp Glare Free Area 9 Center Horizontal Position";
CM_ SG_ 275 RtGFA9MsgCnt "Glare Free Area 9 Right Headlamp Information : Right Headlamp Glare Free Area 9 Message Counter";
CM_ SG_ 275 RtGFA9PointY "Glare Free Area 9 Right Headlamp Information : Right Headlamp Glare Free Area 9 Center Vertical Position";
CM_ SG_ 275 RtGFA9XWidth "Glare Free Area 9 Right Headlamp Information : Right Headlamp Glare Free Area 9 Horizontal Half Width";
CM_ SG_ 275 RtGFA9YWidth "Glare Free Area 9 Right Headlamp Information : Right Headlamp Glare Free Area 9 Vertical Half Width";
CM_ SG_ 275 RtGFA9Dim "Glare Free Area 9 Right Headlamp Information : Right Headlamp Glare Free Area 9 Dim Value";
CM_ SG_ 275 RtGFA9LghtOnTmr "Glare Free Area 9 Right Headlamp Information : Right Headlamp Glare Free Area 9 Dim Up Time";
CM_ SG_ 275 RtGFA9LghtOffTmr "Glare Free Area 9 Right Headlamp Information : Right Headlamp Glare Free Area 9 Dim Down Time";
CM_ SG_ 276 LftGFA10Cksm "Glare Free Area 10 Left Headlamp Information : Left Headlamp Glare Free Area 10 Cksm";
CM_ SG_ 276 LftGFA10PointX "Glare Free Area 10 Left Headlamp Information : Left Headlamp Glare Free Area 10 Center Horizontal Position";
CM_ SG_ 276 LftGFA10MsgCnt "Glare Free Area 10 Left Headlamp Information : Left Headlamp Glare Free Area 10 Message Counter";
CM_ SG_ 276 LftGFA10PointY "Glare Free Area 10 Left Headlamp Information : Left Headlamp Glare Free Area 10 Center Vertical Position";
CM_ SG_ 276 LftGFA10XWidth "Glare Free Area 10 Left Headlamp Information : Left Headlamp Glare Free Area 10 Horizontal Half Width";
CM_ SG_ 276 LftGFA10YWidth "Glare Free Area 10 Left Headlamp Information : Left Headlamp Glare Free Area 10 Vertical Half Width";
CM_ SG_ 276 LftGFA10Dim "Glare Free Area 10 Left Headlamp Information : Left Headlamp Glare Free Area 10 Dim Value";
CM_ SG_ 276 LftGFA10LghtOnTmr "Glare Free Area 10 Left Headlamp Information : Left Headlamp Glare Free Area 10 Dim Up Time";
CM_ SG_ 276 LftGFA10LghtOffTmr "Glare Free Area 10 Left Headlamp Information : Left Headlamp Glare Free Area 10 Dim Down Time";
CM_ SG_ 277 RtGFA10Cksm "Glare Free Area 10 Right Headlamp Information : Right Headlamp Glare Free Area 10 Cksm";
CM_ SG_ 277 RtGFA10PointX "Glare Free Area 10 Right Headlamp Information : Right Headlamp Glare Free Area 10 Center Horizontal Position";
CM_ SG_ 277 RtGFA10MsgCnt "Glare Free Area 10 Right Headlamp Information : Right Headlamp Glare Free Area 10 Message Counter";
CM_ SG_ 277 RtGFA10PointY "Glare Free Area 10 Right Headlamp Information : Right Headlamp Glare Free Area 10 Center Vertical Position";
CM_ SG_ 277 RtGFA10XWidth "Glare Free Area 10 Right Headlamp Information : Right Headlamp Glare Free Area 10 Horizontal Half Width";
CM_ SG_ 277 RtGFA10YWidth "Glare Free Area 10 Right Headlamp Information : Right Headlamp Glare Free Area 10 Vertical Half Width";
CM_ SG_ 277 RtGFA10Dim "Glare Free Area 10 Right Headlamp Information : Right Headlamp Glare Free Area 10 Dim Value";
CM_ SG_ 277 RtGFA10LghtOnTmr "Glare Free Area 10 Right Headlamp Information : Right Headlamp Glare Free Area 10 Dim Up Time";
CM_ SG_ 277 RtGFA10LghtOffTmr "Glare Free Area 10 Right Headlamp Information : Right Headlamp Glare Free Area 10 Dim Down Time";
CM_ SG_ 278 LftGFA11Cksm "Glare Free Area 11 Left Headlamp Information : Left Headlamp Glare Free Area 11 Cksm";
CM_ SG_ 278 LftGFA11PointX "Glare Free Area 11 Left Headlamp Information : Left Headlamp Glare Free Area 11 Center Horizontal Position";
CM_ SG_ 278 LftGFA11MsgCnt "Glare Free Area 11 Left Headlamp Information : Left Headlamp Glare Free Area 11 Message Counter";
CM_ SG_ 278 LftGFA11PointY "Glare Free Area 11 Left Headlamp Information : Left Headlamp Glare Free Area 11 Center Vertical Position";
CM_ SG_ 278 LftGFA11XWidth "Glare Free Area 11 Left Headlamp Information : Left Headlamp Glare Free Area 11 Horizontal Half Width";
CM_ SG_ 278 LftGFA11YWidth "Glare Free Area 11 Left Headlamp Information : Left Headlamp Glare Free Area 11 Vertical Half Width";
CM_ SG_ 278 LftGFA11Dim "Glare Free Area 11 Left Headlamp Information : Left Headlamp Glare Free Area 11 Dim Value";
CM_ SG_ 278 LftGFA11LghtOnTmr "Glare Free Area 11 Left Headlamp Information : Left Headlamp Glare Free Area 11 Dim Up Time";
CM_ SG_ 278 LftGFA11LghtOffTmr "Glare Free Area 11 Left Headlamp Information : Left Headlamp Glare Free Area 11 Dim Down Time";
CM_ SG_ 279 RtGFA11Cksm "Glare Free Area 11 Right Headlamp Information : Right Headlamp Glare Free Area 11 Cksm";
CM_ SG_ 279 RtGFA11PointX "Glare Free Area 11 Right Headlamp Information : Right Headlamp Glare Free Area 11 Center Horizontal Position";
CM_ SG_ 279 RtGFA11MsgCnt "Glare Free Area 11 Right Headlamp Information : Right Headlamp Glare Free Area 11 Message Counter";
CM_ SG_ 279 RtGFA11PointY "Glare Free Area 11 Right Headlamp Information : Right Headlamp Glare Free Area 11 Center Vertical Position";
CM_ SG_ 279 RtGFA11XWidth "Glare Free Area 11 Right Headlamp Information : Right Headlamp Glare Free Area 11 Horizontal Half Width";
CM_ SG_ 279 RtGFA11YWidth "Glare Free Area 11 Right Headlamp Information : Right Headlamp Glare Free Area 11 Vertical Half Width";
CM_ SG_ 279 RtGFA11Dim "Glare Free Area 11 Right Headlamp Information : Right Headlamp Glare Free Area 11 Dim Value";
CM_ SG_ 279 RtGFA11LghtOnTmr "Glare Free Area 11 Right Headlamp Information : Right Headlamp Glare Free Area 11 Dim Up Time";
CM_ SG_ 279 RtGFA11LghtOffTmr "Glare Free Area 11 Right Headlamp Information : Right Headlamp Glare Free Area 11 Dim Down Time";
CM_ SG_ 280 LftGFA12Cksm "Glare Free Area 12 Left Headlamp Information : Left Headlamp Glare Free Area 12 Cksm";
CM_ SG_ 280 LftGFA12PointX "Glare Free Area 12 Left Headlamp Information : Left Headlamp Glare Free Area 12 Center Horizontal Position";
CM_ SG_ 280 LftGFA12MsgCnt "Glare Free Area 12 Left Headlamp Information : Left Headlamp Glare Free Area 12 Message Counter";
CM_ SG_ 280 LftGFA12PointY "Glare Free Area 12 Left Headlamp Information : Left Headlamp Glare Free Area 12 Center Vertical Position";
CM_ SG_ 280 LftGFA12XWidth "Glare Free Area 12 Left Headlamp Information : Left Headlamp Glare Free Area 12 Horizontal Half Width";
CM_ SG_ 280 LftGFA12YWidth "Glare Free Area 12 Left Headlamp Information : Left Headlamp Glare Free Area 12 Vertical Half Width";
CM_ SG_ 280 LftGFA12Dim "Glare Free Area 12 Left Headlamp Information : Left Headlamp Glare Free Area 12 Dim Value";
CM_ SG_ 280 LftGFA12LghtOnTmr "Glare Free Area 12 Left Headlamp Information : Left Headlamp Glare Free Area 12 Dim Up Time";
CM_ SG_ 280 LftGFA12LghtOffTmr "Glare Free Area 12 Left Headlamp Information : Left Headlamp Glare Free Area 12 Dim Down Time";
CM_ SG_ 281 RtGFA12Cksm "Glare Free Area 12 Right Headlamp Information : Right Headlamp Glare Free Area 12 Cksm";
CM_ SG_ 281 RtGFA12PointX "Glare Free Area 12 Right Headlamp Information : Right Headlamp Glare Free Area 12 Center Horizontal Position";
CM_ SG_ 281 RtGFA12MsgCnt "Glare Free Area 12 Right Headlamp Information : Right Headlamp Glare Free Area 12 Message Counter";
CM_ SG_ 281 RtGFA12PointY "Glare Free Area 12 Right Headlamp Information : Right Headlamp Glare Free Area 12 Center Vertical Position";
CM_ SG_ 281 RtGFA12XWidth "Glare Free Area 12 Right Headlamp Information : Right Headlamp Glare Free Area 12 Horizontal Half Width";
CM_ SG_ 281 RtGFA12YWidth "Glare Free Area 12 Right Headlamp Information : Right Headlamp Glare Free Area 12 Vertical Half Width";
CM_ SG_ 281 RtGFA12Dim "Glare Free Area 12 Right Headlamp Information : Right Headlamp Glare Free Area 12 Dim Value";
CM_ SG_ 281 RtGFA12LghtOnTmr "Glare Free Area 12 Right Headlamp Information : Right Headlamp Glare Free Area 12 Dim Up Time";
CM_ SG_ 281 RtGFA12LghtOffTmr "Glare Free Area 12 Right Headlamp Information : Right Headlamp Glare Free Area 12 Dim Down Time";
CM_ SG_ 512 LCGM_LghtCntrWdthLftSdEdg "Light Center Of Gravity Movement Information : Light Center Width Left Side Edge";
CM_ SG_ 512 LCGM_LghtCntrWdthRtSdEdg "Light Center Of Gravity Movement Information : Light Center Width Right Side Edge";
CM_ SG_ 512 LCGM_CntrLghtLvl "Light Center Of Gravity Movement Information : Center Light Level";
CM_ SG_ 512 LCGM_BckgrndLghtLvl "Light Center Of Gravity Movement Information : Background Light Level";
CM_ SG_ 512 LCGM_FnctnStat "Light Center Of Gravity Movement Information : Light Center Function Status";
CM_ SG_ 513 HdlmpLvlSysCksm "Headlamp Levelling System Information : Headlamp Levelling Cksm";
CM_ SG_ 513 LftHdlmpLvlSysPstn "Headlamp Levelling System Information : Left Headlamp Levelling Position";
CM_ SG_ 513 HdlmpLvlSysArc "Headlamp Levelling System Information : Headlamp Levelling Message Counter";
CM_ SG_ 513 RtHdlmpLvlSysPstn "Headlamp Levelling System Information : Right Headlamp Levelling Position";
CM_ SG_ 513 LftHdlmpLvlSysStat "Headlamp Levelling System Information : Right Headlamp Levelling Status";
CM_ SG_ 513 RtHdlmpLvlSysStat "Headlamp Levelling System Information : Left Headlamp Levelling Status";
CM_ SG_ 514 DBLS_Chcksm "Dynamic Bending Light System Information : Dynamic Bending Light System Information Cksm";
CM_ SG_ 514 DBLS_LftHdlmpSwvlAngl "Dynamic Bending Light System Information : Left Headlamp Swivel Angle";
CM_ SG_ 514 DBLS_MssgCntr "Dynamic Bending Light System Information : Dynamic Bending Light System Information Message Counter";
CM_ SG_ 514 DBLS_RtHdlmpSwvlAngl "Dynamic Bending Light System Information : Right Headlamp Swivel Angle";
CM_ SG_ 516 LftBndDim "Static Bending Light/Cornering Light System Information : Left Headlamp Static Bending/Cornering Light Dim Value";
CM_ SG_ 516 RtBndDim "Static Bending Light/Cornering Light System Information : Right Headlamp Static Bending/Cornering Light Dim Value";
CM_ SG_ 523 SSLS_Chcksm "Start/Stop Light System Information : Start/Stop Light Cksm";
CM_ SG_ 523 SSLS_LftHdlmpStrtStpIntnstyVal "Start/Stop Light System Information : Left Headlamp Start/Stop Light Intensity Value";
CM_ SG_ 523 SSLS_MssgCntr "Start/Stop Light System Information : Start/Stop Light Message Counter";
CM_ SG_ 523 SSLS_RtHdlmpStrtStpIntnstyVal "Start/Stop Light System Information : Right Headlamp Start/Stop Light Intensity Value";
CM_ SG_ 525 VehMsgCksm "Vehicle Environment Data Information : Vehicle Environment Data Information Cksm";
CM_ SG_ 525 VED_VhclOprtnMd "Vehicle Environment Data Information : Vehicle Operation Mode";
CM_ SG_ 525 StrtStpStus "Vehicle Environment Data Information : Start Stop Status";
CM_ SG_ 525 VehMsgCnt "Vehicle Environment Data Information : Vehicle Environment Data Information Message Counter";
CM_ SG_ 525 VehSpd "Vehicle Environment Data Information : Vehicle Speed";
CM_ SG_ 525 DiagReq "Vehicle Environment Data Information : Master ECU Request";
CM_ SG_ 525 DhlInitCmd "Vehicle Environment Data Information : Reference Run";
CM_ SG_ 525 VED_VhclDrvngMd "Vehicle Environment Data Information : Vehicle Driving Mode";
CM_ SG_ 525 VED_SysCnfgrtnRqst "Vehicle Environment Data Information : System Configuration Request";
CM_ SG_ 525 TouristMd "Vehicle Environment Data Information : Tourist Mode";
CM_ SG_ 525 TrafficMd "Vehicle Environment Data Information : Traffic Mode";
CM_ SG_ 1032 LftBndSysSts "Dynamic Bending Light System Information : Dynamic Bending Light System Information Cksm";
CM_ SG_ 1033 RtBndSysSts "Dynamic Bending Light System Information : Dynamic Bending Light System Information Cksm";
CM_ SG_ 1280 LftLdmInfo "ECU 1 Left Headlamp Identification Information : Identification Byte 0";
CM_ SG_ 1280 LftLdmInfoIdx "ECU 1 Left Headlamp Identification Information : Identification Byte 0";
CM_ SG_ 1281 RtLdmInfo "ECU 1 Right Headlamp Identification Information : Identification Byte 0";
CM_ SG_ 1281 RtLdmInfoIdx "ECU 1 Right Headlamp Identification Information : Identification Byte 0";
CM_ SG_ 1536 LftGFA1PointXAct "Glare Free Area 1 Left Headlamp Actual Position Information : Left Headlamp Glare Free Area 1 Center Horizontal Actual Position";
CM_ SG_ 1536 LftGFA1PointYAct "Glare Free Area 1 Left Headlamp Actual Position Information : Left Headlamp Glare Free Area 1 Center Vertical Actual Position";
CM_ SG_ 1536 LftGFA1XWidthAct "Glare Free Area 1 Left Headlamp Actual Position Information : Left Headlamp Glare Free Area 1 Horizontal Half Width Actual Position";
CM_ SG_ 1536 LftGFA1YWidthAct "Glare Free Area 1 Left Headlamp Actual Position Information : Left Headlamp Glare Free Area 1 Vertical Half Width Actual Position";
CM_ SG_ 1536 LftGFA1DimAct "Glare Free Area 1 Left Headlamp Actual Position Information : Left Headlamp Glare Free Area 1 Dim Actual Value";
CM_ SG_ 1537 RtGFA1PointXAct "Glare Free Area 1 Right Headlamp Actual Position Information : Right Headlamp Glare Free Area 1 Center Horizontal Actual Position";
CM_ SG_ 1537 RtGFA1PointYAct "Glare Free Area 1 Right Headlamp Actual Position Information : Right Headlamp Glare Free Area 1 Center Vertical Actual Position";
CM_ SG_ 1537 RtGFA1XWidthAct "Glare Free Area 1 Right Headlamp Actual Position Information : Right Headlamp Glare Free Area 1 Horizontal Half Width Actual Position";
CM_ SG_ 1537 RtGFA1YWidthAct "Glare Free Area 1 Right Headlamp Actual Position Information : Right Headlamp Glare Free Area 1 Vertical Half Width Actual Position";
CM_ SG_ 1537 RtGFA1DimAct "Glare Free Area 1 Right Headlamp Actual Position Information : Right Headlamp Glare Free Area 1 Dim Actual Value";
CM_ SG_ 1538 LftGFA2PointXAct "Glare Free Area 2 Left Headlamp Actual Position Information : Left Headlamp Glare Free Area 2 Center Horizontal Actual Position";
CM_ SG_ 1538 LftGFA2PointYAct "Glare Free Area 2 Left Headlamp Actual Position Information : Left Headlamp Glare Free Area 2 Center Vertical Actual Position";
CM_ SG_ 1538 LftGFA2XWidthAct "Glare Free Area 2 Left Headlamp Actual Position Information : Left Headlamp Glare Free Area 2 Horizontal Half Width Actual Position";
CM_ SG_ 1538 LftGFA2YWidthAct "Glare Free Area 2 Left Headlamp Actual Position Information : Left Headlamp Glare Free Area 2 Vertical Half Width Actual Position";
CM_ SG_ 1538 LftGFA2DimAct "Glare Free Area 2 Left Headlamp Actual Position Information : Left Headlamp Glare Free Area 2 Dim Actual Value";
CM_ SG_ 1539 RtGFA2PointXAct "Glare Free Area 2 Right Headlamp Actual Position Information : Right Headlamp Glare Free Area 2 Center Horizontal Actual Position";
CM_ SG_ 1539 RtGFA2PointYAct "Glare Free Area 2 Right Headlamp Actual Position Information : Right Headlamp Glare Free Area 2 Center Vertical Actual Position";
CM_ SG_ 1539 RtGFA2XWidthAct "Glare Free Area 2 Right Headlamp Actual Position Information : Right Headlamp Glare Free Area 2 Horizontal Half Width Actual Position";
CM_ SG_ 1539 RtGFA2YWidthAct "Glare Free Area 2 Right Headlamp Actual Position Information : Right Headlamp Glare Free Area 2 Vertical Half Width Actual Position";
CM_ SG_ 1539 RtGFA2DimAct "Glare Free Area 2 Right Headlamp Actual Position Information : Right Headlamp Glare Free Area 2 Dim Actual Value";
CM_ SG_ 1540 LftGFA3PointXAct "Glare Free Area 3 Left Headlamp Actual Position Information : Left Headlamp Glare Free Area 3 Center Horizontal Actual Position";
CM_ SG_ 1540 LftGFA3PointYAct "Glare Free Area 3 Left Headlamp Actual Position Information : Left Headlamp Glare Free Area 3 Center Vertical Actual Position";
CM_ SG_ 1540 LftGFA3XWidthAct "Glare Free Area 3 Left Headlamp Actual Position Information : Left Headlamp Glare Free Area 3 Horizontal Half Width Actual Position";
CM_ SG_ 1540 LftGFA3YWidthAct "Glare Free Area 3 Left Headlamp Actual Position Information : Left Headlamp Glare Free Area 3 Vertical Half Width Actual Position";
CM_ SG_ 1540 LftGFA3DimAct "Glare Free Area 3 Left Headlamp Actual Position Information : Left Headlamp Glare Free Area 3 Dim Actual Value";
CM_ SG_ 1541 RtGFA3PointXAct "Glare Free Area 3 Right Headlamp Actual Position Information : Right Headlamp Glare Free Area 3 Center Horizontal Actual Position";
CM_ SG_ 1541 RtGFA3PointYAct "Glare Free Area 3 Right Headlamp Actual Position Information : Right Headlamp Glare Free Area 3 Center Vertical Actual Position";
CM_ SG_ 1541 RtGFA3XWidthAct "Glare Free Area 3 Right Headlamp Actual Position Information : Right Headlamp Glare Free Area 3 Horizontal Half Width Actual Position";
CM_ SG_ 1541 RtGFA3YWidthAct "Glare Free Area 3 Right Headlamp Actual Position Information : Right Headlamp Glare Free Area 3 Vertical Half Width Actual Position";
CM_ SG_ 1541 RtGFA3DimAct "Glare Free Area 3 Right Headlamp Actual Position Information : Right Headlamp Glare Free Area 3 Dim Actual Value";
CM_ SG_ 1542 LftGFA4PointXAct "Glare Free Area 4 Left Headlamp Actual Position Information : Left Headlamp Glare Free Area 4 Center Horizontal Actual Position";
CM_ SG_ 1542 LftGFA4PointYAct "Glare Free Area 4 Left Headlamp Actual Position Information : Left Headlamp Glare Free Area 4 Center Vertical Actual Position";
CM_ SG_ 1542 LftGFA4XWidthAct "Glare Free Area 4 Left Headlamp Actual Position Information : Left Headlamp Glare Free Area 4 Horizontal Half Width Actual Position";
CM_ SG_ 1542 LftGFA4YWidthAct "Glare Free Area 4 Left Headlamp Actual Position Information : Left Headlamp Glare Free Area 4 Vertical Half Width Actual Position";
CM_ SG_ 1542 LftGFA4DimAct "Glare Free Area 4 Left Headlamp Actual Position Information : Left Headlamp Glare Free Area 4 Dim Actual Value";
CM_ SG_ 1543 RtGFA4PointXAct "Glare Free Area 4 Right Headlamp Actual Position Information : Right Headlamp Glare Free Area 4 Center Horizontal Actual Position";
CM_ SG_ 1543 RtGFA4PointYAct "Glare Free Area 4 Right Headlamp Actual Position Information : Right Headlamp Glare Free Area 4 Center Vertical Actual Position";
CM_ SG_ 1543 RtGFA4XWidthAct "Glare Free Area 4 Right Headlamp Actual Position Information : Right Headlamp Glare Free Area 4 Horizontal Half Width Actual Position";
CM_ SG_ 1543 RtGFA4YWidthAct "Glare Free Area 4 Right Headlamp Actual Position Information : Right Headlamp Glare Free Area 4 Vertical Half Width Actual Position";
CM_ SG_ 1543 RtGFA4DimAct "Glare Free Area 4 Right Headlamp Actual Position Information : Right Headlamp Glare Free Area 4 Dim Actual Value";
CM_ SG_ 1544 LftGFA5PointXAct "Glare Free Area 5 Left Headlamp Actual Position Information : Left Headlamp Glare Free Area 5 Center Horizontal Actual Position";
CM_ SG_ 1544 LftGFA5PointYAct "Glare Free Area 5 Left Headlamp Actual Position Information : Left Headlamp Glare Free Area 5 Center Vertical Actual Position";
CM_ SG_ 1544 LftGFA5XWidthAct "Glare Free Area 5 Left Headlamp Actual Position Information : Left Headlamp Glare Free Area 5 Horizontal Half Width Actual Position";
CM_ SG_ 1544 LftGFA5YWidthAct "Glare Free Area 5 Left Headlamp Actual Position Information : Left Headlamp Glare Free Area 5 Vertical Half Width Actual Position";
CM_ SG_ 1544 LftGFA5DimAct "Glare Free Area 5 Left Headlamp Actual Position Information : Left Headlamp Glare Free Area 5 Dim Actual Value";
CM_ SG_ 1545 RtGFA5PointXAct "Glare Free Area 5 Right Headlamp Actual Position Information : Right Headlamp Glare Free Area 5 Center Horizontal Actual Position";
CM_ SG_ 1545 RtGFA5PointYAct "Glare Free Area 5 Right Headlamp Actual Position Information : Right Headlamp Glare Free Area 5 Center Vertical Actual Position";
CM_ SG_ 1545 RtGFA5XWidthAct "Glare Free Area 5 Right Headlamp Actual Position Information : Right Headlamp Glare Free Area 5 Horizontal Half Width Actual Position";
CM_ SG_ 1545 RtGFA5YWidthAct "Glare Free Area 5 Right Headlamp Actual Position Information : Right Headlamp Glare Free Area 5 Vertical Half Width Actual Position";
CM_ SG_ 1545 RtGFA5DimAct "Glare Free Area 5 Right Headlamp Actual Position Information : Right Headlamp Glare Free Area 5 Dim Actual Value";
CM_ SG_ 1546 LftGFA6PointXAct "Glare Free Area 6 Left Headlamp Actual Position Information : Left Headlamp Glare Free Area 6 Center Horizontal Actual Position";
CM_ SG_ 1546 LftGFA6PointYAct "Glare Free Area 6 Left Headlamp Actual Position Information : Left Headlamp Glare Free Area 6 Center Vertical Actual Position";
CM_ SG_ 1546 LftGFA6XWidthAct "Glare Free Area 6 Left Headlamp Actual Position Information : Left Headlamp Glare Free Area 6 Horizontal Half Width Actual Position";
CM_ SG_ 1546 LftGFA6YWidthAct "Glare Free Area 6 Left Headlamp Actual Position Information : Left Headlamp Glare Free Area 6 Vertical Half Width Actual Position";
CM_ SG_ 1546 LftGFA6DimAct "Glare Free Area 6 Left Headlamp Actual Position Information : Left Headlamp Glare Free Area 6 Dim Actual Value Actual Position";
CM_ SG_ 1547 RtGFA6PointXAct "Glare Free Area 6 Right Headlamp Actual Position Information : Right Headlamp Glare Free Area 6 Center Horizontal Actual Position";
CM_ SG_ 1547 RtGFA6PointYAct "Glare Free Area 6 Right Headlamp Actual Position Information : Right Headlamp Glare Free Area 6 Center Vertical Actual Position";
CM_ SG_ 1547 RtGFA6XWidthAct "Glare Free Area 6 Right Headlamp Actual Position Information : Right Headlamp Glare Free Area 6 Horizontal Half Width Actual Position";
CM_ SG_ 1547 RtGFA6YWidthAct "Glare Free Area 6 Right Headlamp Actual Position Information : Right Headlamp Glare Free Area 6 Vertical Half Width Actual Position";
CM_ SG_ 1547 RtGFA6DimAct "Glare Free Area 6 Right Headlamp Actual Position Information : Right Headlamp Glare Free Area 6 Dim Actual Value";
CM_ SG_ 1552 LftLghtCntrWdthLftSdActPos "Light Center Of Gravity Movement Left Headlamp Actual Position Information : Left Headlamp Light Center Width Left Side Edge Actual Position";
CM_ SG_ 1552 LftLghtCntrWdthRtSdActPos "Light Center Of Gravity Movement Left Headlamp Actual Position Information : Left Headlamp Light Center Width Right Side Edge Actual Position";
CM_ SG_ 1552 LftCntrLghtLvlActPos "Light Center Of Gravity Movement Left Headlamp Actual Position Information : Left Headlamp Center Light Level Actual Position";
CM_ SG_ 1552 LftBckgrndLghtLvlActPos "Light Center Of Gravity Movement Left Headlamp Actual Position Information : Left Headlamp Background Light Level Actual Position";
CM_ SG_ 1553 RtLghtCntrWdthLftSdActPos "Light Center Of Gravity Movement Right Headlamp Actual Position Information : Right Headlamp Light Center Width Left Side Edge Actual Position";
CM_ SG_ 1553 RtLghtCntrWdthRtSdActPos "Light Center Of Gravity Movement Right Headlamp Actual Position Information : Right Headlamp Light Center Width Right Side Edge Actual Position";
CM_ SG_ 1553 RtCntrLghtLvlActPos "Light Center Of Gravity Movement Right Headlamp Actual Position Information : Right Headlamp Center Light Level Actual Position";
CM_ SG_ 1553 RtBckgrndLghtLvlActPos "Light Center Of Gravity Movement Right Headlamp Actual Position Information : Right Headlamp Background Light Level Actual Position";
CM_ SG_ 1554 LftDhlPosAct "Left Headlamp Levelling Actual Position";
CM_ SG_ 1555 RtDhlPosAct "Right Headlamp Levelling Actual Position";
CM_ SG_ 1556 LftHdlmpSwvlActAngl "Left Headlamp Dynamic Bending Light Angle Actual Position";
CM_ SG_ 1557 RtHdlmpSwvlActAngl "Right Headlamp Dynamic Bending Light Angle Actual Position";
CM_ SG_ 1558 LftBndDimAct "Left Headlamp Static Bending Light Actual Dim Value";
CM_ SG_ 1559 RtBndDimAct "Right Headlamp Static Bending Light Actual Dim Value";
CM_ SG_ 1560 LftAdvrsWthrLghtActStatus "Light Distribution Left Headlamp Actual Status Information : Left Headlamp Adverse Weather Light Actual Status";
CM_ SG_ 1560 LftDistrSts "Light Distribution Left Headlamp Actual Status Information : Left Headlamp Glare Free High Beam Light Actual Status";
CM_ SG_ 1560 LftHBFlshrLghtActStatus "Light Distribution Left Headlamp Actual Status Information : Left Headlamp High Beam Flasher Light Actual Status";
CM_ SG_ 1560 LftHBLghtActStatus "Light Distribution Left Headlamp Actual Status Information : Left Headlamp High Beam Light Actual Status";
CM_ SG_ 1560 LftMtrwyLghtActStatus "Light Distribution Left Headlamp Actual Status Information : Left Headlamp Motorway Light Actual Status";
CM_ SG_ 1560 LftCntryLghtActStatus "Light Distribution Left Headlamp Actual Status Information : Left Headlamp Country Light Actual Status";
CM_ SG_ 1560 LftTwnLghtActStatus "Light Distribution Left Headlamp Actual Status Information : Left Headlamp Town Light Actual Status";
CM_ SG_ 1560 LftPdstrnLghtActStatus "Light Distribution Left Headlamp Actual Status Information : Left Headlamp Pedestrian Light Actual Status";
CM_ SG_ 1560 LftTouristMdAct "Light Distribution Left Headlamp Actual Status Information : Left Headlamp Tourist Mode Light Actual Status";
CM_ SG_ 1561 RtAdvrsWthrLghtActStatus "Light Distribution Right Headlamp Actual Status Information : Right Headlamp Adverse Weather Light Actual Status";
CM_ SG_ 1561 RtDistrSts "Light Distribution Right Headlamp Actual Status Information : Right Headlamp Glare Free High Beam Light Actual Status";
CM_ SG_ 1561 RtHBFlshrLghtActStatus "Light Distribution Right Headlamp Actual Status Information : Right Headlamp High Beam Flasher Light Actual Status";
CM_ SG_ 1561 RtHBLghtActStatus "Light Distribution Right Headlamp Actual Status Information : Right Headlamp High Beam Light Actual Status";
CM_ SG_ 1561 RtMtrwyLghtActStatus "Light Distribution Right Headlamp Actual Status Information : Right Headlamp Motorway Light Actual Status";
CM_ SG_ 1561 RtCntryLghtActStatus "Light Distribution Right Headlamp Actual Status Information : Right Headlamp Country Light Actual Status";
CM_ SG_ 1561 RtTwnLghtActStatus "Light Distribution Right Headlamp Actual Status Information : Right Headlamp Town Light Actual Status";
CM_ SG_ 1561 RtPdstrnLghtActStatus "Light Distribution Right Headlamp Actual Status Information : Right Headlamp Pedestrian Light Actual Status";
CM_ SG_ 1561 RtTouristMdAct "Light Distribution Right Headlamp Actual Status Information : Right Headlamp Tourist Mode Light Actual Status";
CM_ SG_ 1584 LftGFA7PointXAct "Glare Free Area 7 Left Headlamp Actual Position Information : Left Headlamp Glare Free Area 7 Center Horizontal Actual Position";
CM_ SG_ 1584 LftGFA7PointYAct "Glare Free Area 7 Left Headlamp Actual Position Information : Left Headlamp Glare Free Area 7 Center Vertical Actual Position";
CM_ SG_ 1584 LftGFA7XWidthAct "Glare Free Area 7 Left Headlamp Actual Position Information : Left Headlamp Glare Free Area 7 Horizontal Half Width Actual Position";
CM_ SG_ 1584 LftGFA7YWidthAct "Glare Free Area 7 Left Headlamp Actual Position Information : Left Headlamp Glare Free Area 7 Vertical Half Width Actual Position";
CM_ SG_ 1584 LftGFA7DimAct "Glare Free Area 7 Left Headlamp Actual Position Information : Left Headlamp Glare Free Area 7 Dim Actual Value";
CM_ SG_ 1585 RtGFA7PointXAct "Glare Free Area 7 Right Headlamp Actual Position Information : Right Headlamp Glare Free Area 7 Center Horizontal Actual Position";
CM_ SG_ 1585 RtGFA7PointYAct "Glare Free Area 7 Right Headlamp Actual Position Information : Right Headlamp Glare Free Area 7 Center Vertical Actual Position";
CM_ SG_ 1585 RtGFA7XWidthAct "Glare Free Area 7 Right Headlamp Actual Position Information : Right Headlamp Glare Free Area 7 Horizontal Half Width Actual Position";
CM_ SG_ 1585 RtGFA7YWidthAct "Glare Free Area 7 Right Headlamp Actual Position Information : Right Headlamp Glare Free Area 7 Vertical Half Width Actual Position";
CM_ SG_ 1585 RtGFA7DimAct "Glare Free Area 7 Right Headlamp Actual Position Information : Right Headlamp Glare Free Area 7 Dim Actual Value";
CM_ SG_ 1586 LftGFA8PointXAct "Glare Free Area 8 Left Headlamp Actual Position Information : Left Headlamp Glare Free Area 8 Center Horizontal Actual Position";
CM_ SG_ 1586 LftGFA8PointYAct "Glare Free Area 8 Left Headlamp Actual Position Information : Left Headlamp Glare Free Area 8 Center Vertical Actual Position";
CM_ SG_ 1586 LftGFA8XWidthAct "Glare Free Area 8 Left Headlamp Actual Position Information : Left Headlamp Glare Free Area 8 Horizontal Half Width Actual Position";
CM_ SG_ 1586 LftGFA8YWidthAct "Glare Free Area 8 Left Headlamp Actual Position Information : Left Headlamp Glare Free Area 8 Vertical Half Width Actual Position";
CM_ SG_ 1586 LftGFA8DimAct "Glare Free Area 8 Left Headlamp Actual Position Information : Left Headlamp Glare Free Area 8 Dim Actual Value";
CM_ SG_ 1587 RtGFA8PointXAct "Glare Free Area 8 Right Headlamp Actual Position Information : Right Headlamp Glare Free Area 8 Center Horizontal Actual Position";
CM_ SG_ 1587 RtGFA8PointYAct "Glare Free Area 8 Right Headlamp Actual Position Information : Right Headlamp Glare Free Area 8 Center Vertical Actual Position";
CM_ SG_ 1587 RtGFA8XWidthAct "Glare Free Area 8 Right Headlamp Actual Position Information : Right Headlamp Glare Free Area 8 Horizontal Half Width Actual Position";
CM_ SG_ 1587 RtGFA8YWidthAct "Glare Free Area 8 Right Headlamp Actual Position Information : Right Headlamp Glare Free Area 8 Vertical Half Width Actual Position";
CM_ SG_ 1587 RtGFA8DimAct "Glare Free Area 8 Right Headlamp Actual Position Information : Right Headlamp Glare Free Area 8 Dim Actual Value";
CM_ SG_ 1588 LftGFA9PointXAct "Glare Free Area 9 Left Headlamp Actual Position Information : Left Headlamp Glare Free Area 9 Center Horizontal Actual Position";
CM_ SG_ 1588 LftGFA9PointYAct "Glare Free Area 9 Left Headlamp Actual Position Information : Left Headlamp Glare Free Area 9 Center Vertical Actual Position";
CM_ SG_ 1588 LftGFA9XWidthAct "Glare Free Area 9 Left Headlamp Actual Position Information : Left Headlamp Glare Free Area 9 Horizontal Half Width Actual Position";
CM_ SG_ 1588 LftGFA9YWidthAct "Glare Free Area 9 Left Headlamp Actual Position Information : Left Headlamp Glare Free Area 9 Vertical Half Width Actual Position";
CM_ SG_ 1588 LftGFA9DimAct "Glare Free Area 9 Left Headlamp Actual Position Information : Left Headlamp Glare Free Area 9 Dim Actual Value";
CM_ SG_ 1589 RtGFA9PointXAct "Glare Free Area 9 Right Headlamp Actual Position Information : Right Headlamp Glare Free Area 9 Center Horizontal Actual Position";
CM_ SG_ 1589 RtGFA9PointYAct "Glare Free Area 9 Right Headlamp Actual Position Information : Right Headlamp Glare Free Area 9 Center Vertical Actual Position";
CM_ SG_ 1589 RtGFA9XWidthAct "Glare Free Area 9 Right Headlamp Actual Position Information : Right Headlamp Glare Free Area 9 Horizontal Half Width Actual Position";
CM_ SG_ 1589 RtGFA9YWidthAct "Glare Free Area 9 Right Headlamp Actual Position Information : Right Headlamp Glare Free Area 9 Vertical Half Width Actual Position";
CM_ SG_ 1589 RtGFA9DimAct "Glare Free Area 9 Right Headlamp Actual Position Information : Right Headlamp Glare Free Area 9 Dim Actual Value";
CM_ SG_ 1590 LftGFA10PointXAct "Glare Free Area 10 Left Headlamp Actual Position Information : Left Headlamp Glare Free Area 10 Center Horizontal Actual Position";
CM_ SG_ 1590 LftGFA10PointYAct "Glare Free Area 10 Left Headlamp Actual Position Information : Left Headlamp Glare Free Area 10 Center Vertical Actual Position";
CM_ SG_ 1590 LftGFA10XWidthAct "Glare Free Area 10 Left Headlamp Actual Position Information : Left Headlamp Glare Free Area 10 Horizontal Half Width Actual Position";
CM_ SG_ 1590 LftGFA10YWidthAct "Glare Free Area 10 Left Headlamp Actual Position Information : Left Headlamp Glare Free Area 10 Vertical Half Width Actual Position";
CM_ SG_ 1590 LftGFA10DimAct "Glare Free Area 10 Left Headlamp Actual Position Information : Left Headlamp Glare Free Area 10 Dim Actual Value";
CM_ SG_ 1591 RtGFA10PointXAct "Glare Free Area 10 Right Headlamp Actual Position Information : Right Headlamp Glare Free Area 10 Center Horizontal Actual Position";
CM_ SG_ 1591 RtGFA10PointYAct "Glare Free Area 10 Right Headlamp Actual Position Information : Right Headlamp Glare Free Area 10 Center Vertical Actual Position";
CM_ SG_ 1591 RtGFA10XWidthAct "Glare Free Area 10 Right Headlamp Actual Position Information : Right Headlamp Glare Free Area 10 Horizontal Half Width Actual Position";
CM_ SG_ 1591 RtGFA10YWidthAct "Glare Free Area 10 Right Headlamp Actual Position Information : Right Headlamp Glare Free Area 10 Vertical Half Width Actual Position";
CM_ SG_ 1591 RtGFA10DimAct "Glare Free Area 10 Right Headlamp Actual Position Information : Right Headlamp Glare Free Area 10 Dim Actual Value";
CM_ SG_ 1592 LftGFA11PointXAct "Glare Free Area 11 Left Headlamp Actual Position Information : Left Headlamp Glare Free Area 11 Center Horizontal Actual Position";
CM_ SG_ 1592 LftGFA11PointYAct "Glare Free Area 11 Left Headlamp Actual Position Information : Left Headlamp Glare Free Area 11 Center Vertical Actual Position";
CM_ SG_ 1592 LftGFA11XWidthAct "Glare Free Area 11 Left Headlamp Actual Position Information : Left Headlamp Glare Free Area 11 Horizontal Half Width Actual Position";
CM_ SG_ 1592 LftGFA11YWidthAct "Glare Free Area 11 Left Headlamp Actual Position Information : Left Headlamp Glare Free Area 11 Vertical Half Width Actual Position";
CM_ SG_ 1592 LftGFA11DimAct "Glare Free Area 11 Left Headlamp Actual Position Information : Left Headlamp Glare Free Area 11 Dim Actual Value";
CM_ SG_ 1593 RtGFA11PointXAct "Glare Free Area 11 Right Headlamp Actual Position Information : Right Headlamp Glare Free Area 11 Center Horizontal Actual Position";
CM_ SG_ 1593 RtGFA11PointYAct "Glare Free Area 11 Right Headlamp Actual Position Information : Right Headlamp Glare Free Area 11 Center Vertical Actual Position";
CM_ SG_ 1593 RtGFA11XWidthAct "Glare Free Area 11 Right Headlamp Actual Position Information : Right Headlamp Glare Free Area 11 Horizontal Half Width Actual Position";
CM_ SG_ 1593 RtGFA11YWidthAct "Glare Free Area 11 Right Headlamp Actual Position Information : Right Headlamp Glare Free Area 11 Vertical Half Width Actual Position";
CM_ SG_ 1593 RtGFA11DimAct "Glare Free Area 11 Right Headlamp Actual Position Information : Right Headlamp Glare Free Area 11 Dim Actual Value";
CM_ SG_ 1594 LftGFA12PointXAct "Glare Free Area 12 Left Headlamp Actual Position Information : Left Headlamp Glare Free Area 12 Center Horizontal Actual Position";
CM_ SG_ 1594 LftGFA12PointYAct "Glare Free Area 12 Left Headlamp Actual Position Information : Left Headlamp Glare Free Area 12 Center Vertical Actual Position";
CM_ SG_ 1594 LftGFA12XWidthAct "Glare Free Area 12 Left Headlamp Actual Position Information : Left Headlamp Glare Free Area 12 Horizontal Half Width Actual Position";
CM_ SG_ 1594 LftGFA12YWidthAct "Glare Free Area 12 Left Headlamp Actual Position Information : Left Headlamp Glare Free Area 12 Vertical Half Width Actual Position";
CM_ SG_ 1594 LftGFA12DimAct "Glare Free Area 12 Left Headlamp Actual Position Information : Left Headlamp Glare Free Area 12 Dim Actual Value Actual Position";
CM_ SG_ 1595 RtGFA12PointXAct "Glare Free Area 12 Right Headlamp Actual Position Information : Right Headlamp Glare Free Area 12 Center Horizontal Actual Position";
CM_ SG_ 1595 RtGFA12PointYAct "Glare Free Area 12 Right Headlamp Actual Position Information : Right Headlamp Glare Free Area 12 Center Vertical Actual Position";
CM_ SG_ 1595 RtGFA12XWidthAct "Glare Free Area 12 Right Headlamp Actual Position Information : Right Headlamp Glare Free Area 12 Horizontal Half Width Actual Position";
CM_ SG_ 1595 RtGFA12YWidthAct "Glare Free Area 12 Right Headlamp Actual Position Information : Right Headlamp Glare Free Area 12 Vertical Half Width Actual Position";
CM_ SG_ 1595 RtGFA12DimAct "Glare Free Area 12 Right Headlamp Actual Position Information : Right Headlamp Glare Free Area 12 Dim Actual Value";
CM_ SG_ 1792 VINDts6 "Vehicle Identification Number Information : VIN Byte 6";
CM_ SG_ 1792 VINDts5 "Vehicle Identification Number Information : VIN Byte 5";
CM_ SG_ 1792 VINDts4 "Vehicle Identification Number Information : VIN Byte 4";
CM_ SG_ 1792 VINDts3 "Vehicle Identification Number Information : VIN Byte 3";
CM_ SG_ 1792 VINDts2 "Vehicle Identification Number Information : VIN Byte 2";
CM_ SG_ 1792 VINDts1 "Vehicle Identification Number Information : VIN Byte 1";
CM_ SG_ 1792 VINDts0 "Vehicle Identification Number Information : VIN Byte 0";
CM_ SG_ 1792 VINIdx "Vehicle Identification Number Information : VIN Byte 0";
BA_DEF_ SG_  "GenSigSendType" ENUM  "NotUsed","OnWrite","OnWriteWithRepetition","OnChange","OnChangeWithRepetition","IfActive","IfActiveWithRepeition","NoSigSendType";
BA_DEF_ SG_  "GenSigSendOnInit" ENUM  "Not Initialized","Application","Handler";
BA_DEF_ BO_  "GenMsgSendType" ENUM  "Cyclic","NotUsed","NotUsed","NotUsed","NotUsed","NotUsed","NotUsed","NotUsed","NoMsgSendType";
BA_DEF_ BO_  "GenMsgStartDelayTime" INT 0 100000;
BA_DEF_ BO_  "MessageSubnet" ENUM  "BB","PB","CB","Body","HS","Powertrain","Chassis","Spare","PE","CC";
BA_DEF_ BO_  "DiagState" ENUM  "No","Yes";
BA_DEF_ BO_  "DiagResponse" ENUM  "No","Yes";
BA_DEF_ BO_  "DiagRequest" ENUM  "No","Yes";
BA_DEF_ BO_  "GenMsgDelayTime" INT 0 100000;
BA_DEF_ BO_  "GenMsgCycleTime" INT 0 100000;
BA_DEF_ BO_  "GenMsgILSupport" ENUM  "No","Yes";
BA_DEF_REL_ BU_SG_REL_  "GenSigTimeoutTime" INT 0 15000;
BA_DEF_REL_ BU_SG_REL_  "GenSigTimeoutMsg" HEX 0 65535;
BA_DEF_DEF_  "GenSigSendType" "NoSigSendType";
BA_DEF_DEF_  "GenSigSendOnInit" "Not Initialized";
BA_DEF_DEF_  "GenMsgSendType" "NoMsgSendType";
BA_DEF_DEF_  "GenMsgStartDelayTime" 0;
BA_DEF_DEF_  "MessageSubnet" "Body";
BA_DEF_DEF_  "DiagState" "No";
BA_DEF_DEF_  "DiagResponse" "No";
BA_DEF_DEF_  "DiagRequest" "No";
BA_DEF_DEF_  "GenMsgDelayTime" 0;
BA_DEF_DEF_  "GenMsgCycleTime" 0;
BA_DEF_DEF_  "GenMsgILSupport" "Yes";
BA_DEF_DEF_REL_ "GenSigTimeoutTime" 0;
BA_DEF_DEF_REL_ "GenSigTimeoutMsg" 0;
BA_ "GenMsgSendType" BO_ 515 0;
BA_ "MessageSubnet" BO_ 515 1;
BA_ "GenMsgCycleTime" BO_ 515 20;
BA_ "MessageSubnet" BO_ 1942 1;
BA_ "DiagResponse" BO_ 1942 1;
BA_ "MessageSubnet" BO_ 1814 1;
BA_ "DiagRequest" BO_ 1814 1;
BA_ "MessageSubnet" BO_ 2015 1;
BA_ "DiagState" BO_ 2015 1;
BA_ "MessageSubnet" BO_ 1813 1;
BA_ "DiagRequest" BO_ 1813 1;
BA_ "MessageSubnet" BO_ 1941 1;
BA_ "DiagResponse" BO_ 1941 1;
BA_ "MessageSubnet" BO_ 2161836032 1;
BA_ "GenMsgCycleTime" BO_ 2161836032 5000;
BA_ "MessageSubnet" BO_ 258 1;
BA_ "GenMsgCycleTime" BO_ 258 20;
BA_ "GenMsgSendType" BO_ 258 0;
BA_ "MessageSubnet" BO_ 259 1;
BA_ "GenMsgCycleTime" BO_ 259 20;
BA_ "GenMsgSendType" BO_ 259 0;
BA_ "MessageSubnet" BO_ 260 1;
BA_ "GenMsgCycleTime" BO_ 260 20;
BA_ "GenMsgSendType" BO_ 260 0;
BA_ "MessageSubnet" BO_ 261 1;
BA_ "GenMsgCycleTime" BO_ 261 20;
BA_ "GenMsgSendType" BO_ 261 0;
BA_ "MessageSubnet" BO_ 262 1;
BA_ "GenMsgCycleTime" BO_ 262 20;
BA_ "GenMsgSendType" BO_ 262 0;
BA_ "MessageSubnet" BO_ 263 1;
BA_ "GenMsgCycleTime" BO_ 263 20;
BA_ "GenMsgSendType" BO_ 263 0;
BA_ "MessageSubnet" BO_ 264 1;
BA_ "GenMsgCycleTime" BO_ 264 20;
BA_ "GenMsgSendType" BO_ 264 0;
BA_ "MessageSubnet" BO_ 265 1;
BA_ "GenMsgCycleTime" BO_ 265 20;
BA_ "GenMsgSendType" BO_ 265 0;
BA_ "MessageSubnet" BO_ 266 1;
BA_ "GenMsgCycleTime" BO_ 266 20;
BA_ "GenMsgSendType" BO_ 266 0;
BA_ "MessageSubnet" BO_ 267 1;
BA_ "GenMsgCycleTime" BO_ 267 20;
BA_ "GenMsgSendType" BO_ 267 0;
BA_ "MessageSubnet" BO_ 268 1;
BA_ "GenMsgCycleTime" BO_ 268 20;
BA_ "GenMsgSendType" BO_ 268 0;
BA_ "MessageSubnet" BO_ 269 1;
BA_ "GenMsgCycleTime" BO_ 269 20;
BA_ "GenMsgSendType" BO_ 269 0;
BA_ "MessageSubnet" BO_ 270 1;
BA_ "GenMsgCycleTime" BO_ 270 20;
BA_ "GenMsgSendType" BO_ 270 0;
BA_ "MessageSubnet" BO_ 271 1;
BA_ "GenMsgCycleTime" BO_ 271 20;
BA_ "GenMsgSendType" BO_ 271 0;
BA_ "MessageSubnet" BO_ 272 1;
BA_ "GenMsgCycleTime" BO_ 272 20;
BA_ "GenMsgSendType" BO_ 272 0;
BA_ "MessageSubnet" BO_ 273 1;
BA_ "GenMsgCycleTime" BO_ 273 20;
BA_ "GenMsgSendType" BO_ 273 0;
BA_ "MessageSubnet" BO_ 274 1;
BA_ "GenMsgCycleTime" BO_ 274 20;
BA_ "GenMsgSendType" BO_ 274 0;
BA_ "MessageSubnet" BO_ 275 1;
BA_ "GenMsgCycleTime" BO_ 275 20;
BA_ "GenMsgSendType" BO_ 275 0;
BA_ "MessageSubnet" BO_ 276 1;
BA_ "GenMsgCycleTime" BO_ 276 20;
BA_ "GenMsgSendType" BO_ 276 0;
BA_ "MessageSubnet" BO_ 277 1;
BA_ "GenMsgCycleTime" BO_ 277 20;
BA_ "GenMsgSendType" BO_ 277 0;
BA_ "MessageSubnet" BO_ 278 1;
BA_ "GenMsgCycleTime" BO_ 278 20;
BA_ "GenMsgSendType" BO_ 278 0;
BA_ "MessageSubnet" BO_ 279 1;
BA_ "GenMsgCycleTime" BO_ 279 20;
BA_ "GenMsgSendType" BO_ 279 0;
BA_ "MessageSubnet" BO_ 280 1;
BA_ "GenMsgCycleTime" BO_ 280 20;
BA_ "GenMsgSendType" BO_ 280 0;
BA_ "MessageSubnet" BO_ 281 1;
BA_ "GenMsgCycleTime" BO_ 281 20;
BA_ "GenMsgSendType" BO_ 281 0;
BA_ "MessageSubnet" BO_ 481 1;
BA_ "GenMsgCycleTime" BO_ 481 100;
BA_ "GenMsgSendType" BO_ 481 0;
BA_ "MessageSubnet" BO_ 512 1;
BA_ "GenMsgCycleTime" BO_ 512 20;
BA_ "GenMsgSendType" BO_ 512 0;
BA_ "MessageSubnet" BO_ 513 1;
BA_ "GenMsgCycleTime" BO_ 513 20;
BA_ "GenMsgSendType" BO_ 513 0;
BA_ "MessageSubnet" BO_ 514 1;
BA_ "GenMsgCycleTime" BO_ 514 20;
BA_ "GenMsgSendType" BO_ 514 0;
BA_ "MessageSubnet" BO_ 516 1;
BA_ "GenMsgCycleTime" BO_ 516 20;
BA_ "GenMsgSendType" BO_ 516 0;
BA_ "MessageSubnet" BO_ 523 1;
BA_ "GenMsgCycleTime" BO_ 523 500;
BA_ "GenMsgSendType" BO_ 523 0;
BA_ "MessageSubnet" BO_ 525 1;
BA_ "GenMsgCycleTime" BO_ 525 100;
BA_ "GenMsgSendType" BO_ 525 0;
BA_ "MessageSubnet" BO_ 1024 1;
BA_ "GenMsgSendType" BO_ 1024 0;
BA_ "GenMsgCycleTime" BO_ 1024 100;
BA_ "GenMsgStartDelayTime" BO_ 1024 10;
BA_ "MessageSubnet" BO_ 1025 1;
BA_ "GenMsgCycleTime" BO_ 1025 100;
BA_ "GenMsgSendType" BO_ 1025 0;
BA_ "GenMsgStartDelayTime" BO_ 1025 10;
BA_ "MessageSubnet" BO_ 1026 1;
BA_ "GenMsgSendType" BO_ 1026 0;
BA_ "GenMsgCycleTime" BO_ 1026 100;
BA_ "GenMsgStartDelayTime" BO_ 1026 20;
BA_ "MessageSubnet" BO_ 1027 1;
BA_ "GenMsgCycleTime" BO_ 1027 100;
BA_ "GenMsgSendType" BO_ 1027 0;
BA_ "GenMsgStartDelayTime" BO_ 1027 20;
BA_ "MessageSubnet" BO_ 1028 1;
BA_ "GenMsgSendType" BO_ 1028 0;
BA_ "GenMsgCycleTime" BO_ 1028 100;
BA_ "GenMsgStartDelayTime" BO_ 1028 20;
BA_ "MessageSubnet" BO_ 1029 1;
BA_ "GenMsgCycleTime" BO_ 1029 100;
BA_ "GenMsgSendType" BO_ 1029 0;
BA_ "GenMsgStartDelayTime" BO_ 1029 20;
BA_ "MessageSubnet" BO_ 1030 1;
BA_ "GenMsgSendType" BO_ 1030 0;
BA_ "GenMsgCycleTime" BO_ 1030 100;
BA_ "GenMsgStartDelayTime" BO_ 1030 20;
BA_ "MessageSubnet" BO_ 1031 1;
BA_ "GenMsgCycleTime" BO_ 1031 100;
BA_ "GenMsgSendType" BO_ 1031 0;
BA_ "GenMsgStartDelayTime" BO_ 1031 20;
BA_ "MessageSubnet" BO_ 1032 1;
BA_ "GenMsgSendType" BO_ 1032 0;
BA_ "GenMsgCycleTime" BO_ 1032 100;
BA_ "GenMsgStartDelayTime" BO_ 1032 30;
BA_ "MessageSubnet" BO_ 1033 1;
BA_ "GenMsgCycleTime" BO_ 1033 100;
BA_ "GenMsgSendType" BO_ 1033 0;
BA_ "GenMsgStartDelayTime" BO_ 1033 30;
BA_ "MessageSubnet" BO_ 1042 1;
BA_ "GenMsgSendType" BO_ 1042 0;
BA_ "GenMsgCycleTime" BO_ 1042 100;
BA_ "GenMsgStartDelayTime" BO_ 1042 30;
BA_ "MessageSubnet" BO_ 1043 1;
BA_ "GenMsgCycleTime" BO_ 1043 100;
BA_ "GenMsgSendType" BO_ 1043 0;
BA_ "GenMsgStartDelayTime" BO_ 1043 30;
BA_ "MessageSubnet" BO_ 1044 1;
BA_ "GenMsgSendType" BO_ 1044 0;
BA_ "GenMsgCycleTime" BO_ 1044 100;
BA_ "GenMsgStartDelayTime" BO_ 1044 30;
BA_ "MessageSubnet" BO_ 1045 1;
BA_ "GenMsgCycleTime" BO_ 1045 100;
BA_ "GenMsgSendType" BO_ 1045 0;
BA_ "GenMsgStartDelayTime" BO_ 1045 30;
BA_ "GenMsgStartDelayTime" BO_ 1280 40;
BA_ "MessageSubnet" BO_ 1280 1;
BA_ "GenMsgSendType" BO_ 1280 0;
BA_ "GenMsgCycleTime" BO_ 1280 40;
BA_ "GenMsgStartDelayTime" BO_ 1281 40;
BA_ "MessageSubnet" BO_ 1281 1;
BA_ "GenMsgCycleTime" BO_ 1281 40;
BA_ "GenMsgSendType" BO_ 1281 0;
BA_ "MessageSubnet" BO_ 1536 1;
BA_ "GenMsgSendType" BO_ 1536 0;
BA_ "GenMsgCycleTime" BO_ 1536 100;
BA_ "GenMsgStartDelayTime" BO_ 1536 40;
BA_ "MessageSubnet" BO_ 1537 1;
BA_ "GenMsgCycleTime" BO_ 1537 100;
BA_ "GenMsgSendType" BO_ 1537 0;
BA_ "GenMsgStartDelayTime" BO_ 1537 40;
BA_ "MessageSubnet" BO_ 1538 1;
BA_ "GenMsgSendType" BO_ 1538 0;
BA_ "GenMsgCycleTime" BO_ 1538 100;
BA_ "GenMsgStartDelayTime" BO_ 1538 40;
BA_ "MessageSubnet" BO_ 1539 1;
BA_ "GenMsgCycleTime" BO_ 1539 100;
BA_ "GenMsgSendType" BO_ 1539 0;
BA_ "GenMsgStartDelayTime" BO_ 1539 40;
BA_ "MessageSubnet" BO_ 1540 1;
BA_ "GenMsgSendType" BO_ 1540 0;
BA_ "GenMsgCycleTime" BO_ 1540 100;
BA_ "GenMsgStartDelayTime" BO_ 1540 50;
BA_ "MessageSubnet" BO_ 1541 1;
BA_ "GenMsgCycleTime" BO_ 1541 100;
BA_ "GenMsgSendType" BO_ 1541 0;
BA_ "GenMsgStartDelayTime" BO_ 1541 50;
BA_ "MessageSubnet" BO_ 1542 1;
BA_ "GenMsgSendType" BO_ 1542 0;
BA_ "GenMsgCycleTime" BO_ 1542 100;
BA_ "GenMsgStartDelayTime" BO_ 1542 50;
BA_ "MessageSubnet" BO_ 1543 1;
BA_ "GenMsgCycleTime" BO_ 1543 100;
BA_ "GenMsgSendType" BO_ 1543 0;
BA_ "GenMsgStartDelayTime" BO_ 1543 50;
BA_ "MessageSubnet" BO_ 1544 1;
BA_ "GenMsgSendType" BO_ 1544 0;
BA_ "GenMsgCycleTime" BO_ 1544 100;
BA_ "GenMsgStartDelayTime" BO_ 1544 50;
BA_ "MessageSubnet" BO_ 1545 1;
BA_ "GenMsgCycleTime" BO_ 1545 100;
BA_ "GenMsgSendType" BO_ 1545 0;
BA_ "GenMsgStartDelayTime" BO_ 1545 50;
BA_ "MessageSubnet" BO_ 1546 1;
BA_ "GenMsgSendType" BO_ 1546 0;
BA_ "GenMsgCycleTime" BO_ 1546 100;
BA_ "GenMsgStartDelayTime" BO_ 1546 60;
BA_ "MessageSubnet" BO_ 1547 1;
BA_ "GenMsgCycleTime" BO_ 1547 100;
BA_ "GenMsgSendType" BO_ 1547 0;
BA_ "GenMsgStartDelayTime" BO_ 1547 60;
BA_ "GenMsgStartDelayTime" BO_ 1552 60;
BA_ "MessageSubnet" BO_ 1552 1;
BA_ "GenMsgSendType" BO_ 1552 0;
BA_ "GenMsgCycleTime" BO_ 1552 100;
BA_ "GenMsgStartDelayTime" BO_ 1553 60;
BA_ "MessageSubnet" BO_ 1553 1;
BA_ "GenMsgCycleTime" BO_ 1553 100;
BA_ "GenMsgSendType" BO_ 1553 0;
BA_ "GenMsgStartDelayTime" BO_ 1554 60;
BA_ "MessageSubnet" BO_ 1554 1;
BA_ "GenMsgSendType" BO_ 1554 0;
BA_ "GenMsgCycleTime" BO_ 1554 100;
BA_ "GenMsgStartDelayTime" BO_ 1555 60;
BA_ "MessageSubnet" BO_ 1555 1;
BA_ "GenMsgCycleTime" BO_ 1555 100;
BA_ "GenMsgSendType" BO_ 1555 0;
BA_ "GenMsgStartDelayTime" BO_ 1556 70;
BA_ "MessageSubnet" BO_ 1556 1;
BA_ "GenMsgSendType" BO_ 1556 0;
BA_ "GenMsgCycleTime" BO_ 1556 100;
BA_ "GenMsgStartDelayTime" BO_ 1557 70;
BA_ "MessageSubnet" BO_ 1557 1;
BA_ "GenMsgCycleTime" BO_ 1557 100;
BA_ "GenMsgSendType" BO_ 1557 0;
BA_ "GenMsgStartDelayTime" BO_ 1558 70;
BA_ "MessageSubnet" BO_ 1558 1;
BA_ "GenMsgSendType" BO_ 1558 0;
BA_ "GenMsgCycleTime" BO_ 1558 100;
BA_ "GenMsgStartDelayTime" BO_ 1559 70;
BA_ "MessageSubnet" BO_ 1559 1;
BA_ "GenMsgCycleTime" BO_ 1559 100;
BA_ "GenMsgSendType" BO_ 1559 0;
BA_ "GenMsgStartDelayTime" BO_ 1560 70;
BA_ "MessageSubnet" BO_ 1560 1;
BA_ "GenMsgSendType" BO_ 1560 0;
BA_ "GenMsgCycleTime" BO_ 1560 100;
BA_ "GenMsgStartDelayTime" BO_ 1561 70;
BA_ "MessageSubnet" BO_ 1561 1;
BA_ "GenMsgCycleTime" BO_ 1561 100;
BA_ "GenMsgSendType" BO_ 1561 0;
BA_ "MessageSubnet" BO_ 1584 1;
BA_ "GenMsgSendType" BO_ 1584 0;
BA_ "GenMsgCycleTime" BO_ 1584 100;
BA_ "GenMsgStartDelayTime" BO_ 1584 80;
BA_ "MessageSubnet" BO_ 1585 1;
BA_ "GenMsgCycleTime" BO_ 1585 100;
BA_ "GenMsgSendType" BO_ 1585 0;
BA_ "GenMsgStartDelayTime" BO_ 1585 80;
BA_ "MessageSubnet" BO_ 1586 1;
BA_ "GenMsgSendType" BO_ 1586 0;
BA_ "GenMsgCycleTime" BO_ 1586 100;
BA_ "GenMsgStartDelayTime" BO_ 1586 80;
BA_ "MessageSubnet" BO_ 1587 1;
BA_ "GenMsgCycleTime" BO_ 1587 100;
BA_ "GenMsgSendType" BO_ 1587 0;
BA_ "GenMsgStartDelayTime" BO_ 1587 80;
BA_ "MessageSubnet" BO_ 1588 1;
BA_ "GenMsgSendType" BO_ 1588 0;
BA_ "GenMsgCycleTime" BO_ 1588 100;
BA_ "GenMsgStartDelayTime" BO_ 1588 80;
BA_ "MessageSubnet" BO_ 1589 1;
BA_ "GenMsgCycleTime" BO_ 1589 100;
BA_ "GenMsgSendType" BO_ 1589 0;
BA_ "GenMsgStartDelayTime" BO_ 1589 80;
BA_ "MessageSubnet" BO_ 1590 1;
BA_ "GenMsgSendType" BO_ 1590 0;
BA_ "GenMsgCycleTime" BO_ 1590 100;
BA_ "GenMsgStartDelayTime" BO_ 1590 90;
BA_ "MessageSubnet" BO_ 1591 1;
BA_ "GenMsgCycleTime" BO_ 1591 100;
BA_ "GenMsgSendType" BO_ 1591 0;
BA_ "GenMsgStartDelayTime" BO_ 1591 90;
BA_ "MessageSubnet" BO_ 1592 1;
BA_ "GenMsgSendType" BO_ 1592 0;
BA_ "GenMsgCycleTime" BO_ 1592 100;
BA_ "GenMsgStartDelayTime" BO_ 1592 90;
BA_ "MessageSubnet" BO_ 1593 1;
BA_ "GenMsgCycleTime" BO_ 1593 100;
BA_ "GenMsgSendType" BO_ 1593 0;
BA_ "GenMsgStartDelayTime" BO_ 1593 90;
BA_ "MessageSubnet" BO_ 1594 1;
BA_ "GenMsgSendType" BO_ 1594 0;
BA_ "GenMsgCycleTime" BO_ 1594 100;
BA_ "GenMsgStartDelayTime" BO_ 1594 90;
BA_ "MessageSubnet" BO_ 1595 1;
BA_ "GenMsgCycleTime" BO_ 1595 100;
BA_ "GenMsgSendType" BO_ 1595 0;
BA_ "GenMsgStartDelayTime" BO_ 1595 90;
BA_ "MessageSubnet" BO_ 1792 1;
BA_ "GenMsgCycleTime" BO_ 1792 1000;
BA_ "GenMsgSendType" BO_ 1792 0;
BA_REL_ "GenSigTimeoutMsg" BU_SG_REL_ LDM_RH SG_ 515 DistrCksm 515;
BA_REL_ "GenSigTimeoutTime" BU_SG_REL_ LDM_RH SG_ 515 DistrCksm 250;
BA_REL_ "GenSigTimeoutMsg" BU_SG_REL_ LDM_LH SG_ 515 DistrCksm 515;
BA_REL_ "GenSigTimeoutTime" BU_SG_REL_ LDM_LH SG_ 515 DistrCksm 250;
BA_REL_ "GenSigTimeoutTime" BU_SG_REL_ LDM_LH SG_ 258 LftGFA1Cksm 250;
BA_REL_ "GenSigTimeoutMsg" BU_SG_REL_ LDM_LH SG_ 258 LftGFA1Cksm 258;
BA_REL_ "GenSigTimeoutTime" BU_SG_REL_ LDM_RH SG_ 259 RtGFA1Cksm 250;
BA_REL_ "GenSigTimeoutMsg" BU_SG_REL_ LDM_RH SG_ 259 RtGFA1Cksm 259;
BA_REL_ "GenSigTimeoutTime" BU_SG_REL_ LDM_LH SG_ 260 LftGFA2Cksm 250;
BA_REL_ "GenSigTimeoutMsg" BU_SG_REL_ LDM_LH SG_ 260 LftGFA2Cksm 260;
BA_REL_ "GenSigTimeoutTime" BU_SG_REL_ LDM_RH SG_ 261 RtGFA2Cksm 250;
BA_REL_ "GenSigTimeoutMsg" BU_SG_REL_ LDM_RH SG_ 261 RtGFA2Cksm 261;
BA_REL_ "GenSigTimeoutTime" BU_SG_REL_ LDM_LH SG_ 262 LftGFA3Cksm 250;
BA_REL_ "GenSigTimeoutMsg" BU_SG_REL_ LDM_LH SG_ 262 LftGFA3Cksm 262;
BA_REL_ "GenSigTimeoutTime" BU_SG_REL_ LDM_RH SG_ 263 RtGFA3Cksm 250;
BA_REL_ "GenSigTimeoutMsg" BU_SG_REL_ LDM_RH SG_ 263 RtGFA3Cksm 263;
BA_REL_ "GenSigTimeoutTime" BU_SG_REL_ LDM_LH SG_ 264 LftGFA4Cksm 250;
BA_REL_ "GenSigTimeoutMsg" BU_SG_REL_ LDM_LH SG_ 264 LftGFA4Cksm 264;
BA_REL_ "GenSigTimeoutTime" BU_SG_REL_ LDM_RH SG_ 265 RtGFA4Cksm 250;
BA_REL_ "GenSigTimeoutMsg" BU_SG_REL_ LDM_RH SG_ 265 RtGFA4Cksm 265;
BA_REL_ "GenSigTimeoutTime" BU_SG_REL_ LDM_LH SG_ 266 LftGFA5Cksm 250;
BA_REL_ "GenSigTimeoutMsg" BU_SG_REL_ LDM_LH SG_ 266 LftGFA5Cksm 266;
BA_REL_ "GenSigTimeoutTime" BU_SG_REL_ LDM_RH SG_ 267 RtGFA5Cksm 250;
BA_REL_ "GenSigTimeoutMsg" BU_SG_REL_ LDM_RH SG_ 267 RtGFA5Cksm 267;
BA_REL_ "GenSigTimeoutTime" BU_SG_REL_ LDM_LH SG_ 268 LftGFA6Cksm 250;
BA_REL_ "GenSigTimeoutMsg" BU_SG_REL_ LDM_LH SG_ 268 LftGFA6Cksm 268;
BA_REL_ "GenSigTimeoutTime" BU_SG_REL_ LDM_RH SG_ 269 RtGFA6Cksm 250;
BA_REL_ "GenSigTimeoutMsg" BU_SG_REL_ LDM_RH SG_ 269 RtGFA6Cksm 269;
BA_REL_ "GenSigTimeoutTime" BU_SG_REL_ LDM_LH SG_ 270 LftGFA7Cksm 250;
BA_REL_ "GenSigTimeoutMsg" BU_SG_REL_ LDM_LH SG_ 270 LftGFA7Cksm 270;
BA_REL_ "GenSigTimeoutTime" BU_SG_REL_ LDM_RH SG_ 271 RtGFA7Cksm 250;
BA_REL_ "GenSigTimeoutMsg" BU_SG_REL_ LDM_RH SG_ 271 RtGFA7Cksm 271;
BA_REL_ "GenSigTimeoutTime" BU_SG_REL_ LDM_LH SG_ 272 LftGFA8Cksm 250;
BA_REL_ "GenSigTimeoutMsg" BU_SG_REL_ LDM_LH SG_ 272 LftGFA8Cksm 272;
BA_REL_ "GenSigTimeoutTime" BU_SG_REL_ LDM_RH SG_ 273 RtGFA8Cksm 250;
BA_REL_ "GenSigTimeoutMsg" BU_SG_REL_ LDM_RH SG_ 273 RtGFA8Cksm 273;
BA_REL_ "GenSigTimeoutTime" BU_SG_REL_ LDM_LH SG_ 274 LftGFA9Cksm 250;
BA_REL_ "GenSigTimeoutMsg" BU_SG_REL_ LDM_LH SG_ 274 LftGFA9Cksm 274;
BA_REL_ "GenSigTimeoutTime" BU_SG_REL_ LDM_RH SG_ 275 RtGFA9Cksm 250;
BA_REL_ "GenSigTimeoutMsg" BU_SG_REL_ LDM_RH SG_ 275 RtGFA9Cksm 275;
BA_REL_ "GenSigTimeoutTime" BU_SG_REL_ LDM_LH SG_ 276 LftGFA10Cksm 250;
BA_REL_ "GenSigTimeoutMsg" BU_SG_REL_ LDM_LH SG_ 276 LftGFA10Cksm 276;
BA_REL_ "GenSigTimeoutTime" BU_SG_REL_ LDM_RH SG_ 277 RtGFA10Cksm 250;
BA_REL_ "GenSigTimeoutMsg" BU_SG_REL_ LDM_RH SG_ 277 RtGFA10Cksm 277;
BA_REL_ "GenSigTimeoutTime" BU_SG_REL_ LDM_LH SG_ 278 LftGFA11Cksm 250;
BA_REL_ "GenSigTimeoutMsg" BU_SG_REL_ LDM_LH SG_ 278 LftGFA11Cksm 278;
BA_REL_ "GenSigTimeoutTime" BU_SG_REL_ LDM_RH SG_ 279 RtGFA11Cksm 250;
BA_REL_ "GenSigTimeoutMsg" BU_SG_REL_ LDM_RH SG_ 279 RtGFA11Cksm 279;
BA_REL_ "GenSigTimeoutTime" BU_SG_REL_ LDM_LH SG_ 280 LftGFA12Cksm 250;
BA_REL_ "GenSigTimeoutMsg" BU_SG_REL_ LDM_LH SG_ 280 LftGFA12Cksm 280;
BA_REL_ "GenSigTimeoutTime" BU_SG_REL_ LDM_RH SG_ 281 RtGFA12Cksm 250;
BA_REL_ "GenSigTimeoutMsg" BU_SG_REL_ LDM_RH SG_ 281 RtGFA12Cksm 281;
BA_REL_ "GenSigTimeoutTime" BU_SG_REL_ LDM_LH SG_ 513 LftHdlmpLvlSysStat 250;
BA_REL_ "GenSigTimeoutMsg" BU_SG_REL_ LDM_LH SG_ 513 LftHdlmpLvlSysStat 513;
BA_REL_ "GenSigTimeoutTime" BU_SG_REL_ LDM_RH SG_ 513 RtHdlmpLvlSysStat 250;
BA_REL_ "GenSigTimeoutMsg" BU_SG_REL_ LDM_RH SG_ 513 RtHdlmpLvlSysStat 513;
BA_REL_ "GenSigTimeoutTime" BU_SG_REL_ LDM_RH SG_ 514 DBLS_Chcksm 250;
BA_REL_ "GenSigTimeoutMsg" BU_SG_REL_ LDM_RH SG_ 514 DBLS_Chcksm 514;
BA_REL_ "GenSigTimeoutTime" BU_SG_REL_ LDM_LH SG_ 514 DBLS_Chcksm 250;
BA_REL_ "GenSigTimeoutMsg" BU_SG_REL_ LDM_LH SG_ 514 DBLS_Chcksm 514;
BA_REL_ "GenSigTimeoutTime" BU_SG_REL_ LDM_LH SG_ 516 LftBndDim 250;
BA_REL_ "GenSigTimeoutMsg" BU_SG_REL_ LDM_LH SG_ 516 LftBndDim 516;
BA_REL_ "GenSigTimeoutTime" BU_SG_REL_ LDM_RH SG_ 516 RtBndDim 250;
BA_REL_ "GenSigTimeoutMsg" BU_SG_REL_ LDM_RH SG_ 516 RtBndDim 516;
BA_REL_ "GenSigTimeoutMsg" BU_SG_REL_ LDM_LH SG_ 525 DhlInitCmd 525;
BA_REL_ "GenSigTimeoutTime" BU_SG_REL_ LDM_LH SG_ 525 DhlInitCmd 250;
BA_REL_ "GenSigTimeoutTime" BU_SG_REL_ LDM_RH SG_ 525 DhlInitCmd 250;
BA_REL_ "GenSigTimeoutMsg" BU_SG_REL_ LDM_RH SG_ 525 DhlInitCmd 525;
SIG_GROUP_ 515 LftLghtDistSystmGrp 1 : LftCntryLghtDstrbtn LftAdvrsWthrLghtDstrbtn LftGFHBLghtDstrbtnMtrwyLvl LftDistrGFHB LftMtrwyLghtDstrbtnLvl LftHBLghtDstrbtn LftHBFlshrLghtDstrbtn LftTwnLghtDstrbtn LftPdstrnLghtDstrbtn;
SIG_GROUP_ 515 RtLghtDistSystmGrp 1 : RtDistrGFHB RtPdstrnLghtDstrbtn RtTwnLghtDstrbtn RtHBFlshrLghtDstrbtn RtHBLghtDstrbtn RtMtrwyLghtDstrbtnLvl RtGFHBLghtDstrbtnMtrwyLvl RtCntryLghtDstrbtn RtAdvrsWthrLghtDstrbtn;
SIG_GROUP_ 258 GlareFreeArea_1_LHGrp 1 : LftGFA1Valid LftGFA1Cksm LftGFA1PointX LftGFA1PointY LftGFA1LghtOffTmr LftGFA1LghtOnTmr LftGFA1Dim LftGFA1XWidth LftGFA1MsgCnt LftGFA1YWidth;
SIG_GROUP_ 259 GlareFreeArea_1_RHGrp 1 : RtGFA1Valid RtGFA1Cksm RtGFA1PointX RtGFA1PointY RtGFA1LghtOffTmr RtGFA1LghtOnTmr RtGFA1Dim RtGFA1XWidth RtGFA1MsgCnt RtGFA1YWidth;
SIG_GROUP_ 260 GlareFreeArea_2_LHGrp 1 : LftGFA2Valid LftGFA2Cksm LftGFA2PointX LftGFA2PointY LftGFA2LghtOffTmr LftGFA2LghtOnTmr LftGFA2Dim LftGFA2XWidth LftGFA2MsgCnt LftGFA2YWidth;
SIG_GROUP_ 261 GlareFreeArea_2_RHGrp 1 : RtGFA2Valid RtGFA2Cksm RtGFA2PointX RtGFA2PointY RtGFA2LghtOffTmr RtGFA2LghtOnTmr RtGFA2Dim RtGFA2XWidth RtGFA2MsgCnt RtGFA2YWidth;
SIG_GROUP_ 262 GlareFreeArea_3_LHGrp 1 : LftGFA3Valid LftGFA3Cksm LftGFA3PointX LftGFA3PointY LftGFA3LghtOffTmr LftGFA3LghtOnTmr LftGFA3Dim LftGFA3XWidth LftGFA3MsgCnt LftGFA3YWidth;
SIG_GROUP_ 263 GlareFreeArea_3_RHGrp 1 : RtGFA3Valid RtGFA3Cksm RtGFA3PointX RtGFA3PointY RtGFA3LghtOffTmr RtGFA3LghtOnTmr RtGFA3Dim RtGFA3XWidth RtGFA3MsgCnt RtGFA3YWidth;
SIG_GROUP_ 264 GlareFreeArea_4_LHGrp 1 : LftGFA4Valid LftGFA4Cksm LftGFA4PointX LftGFA4PointY LftGFA4LghtOffTmr LftGFA4LghtOnTmr LftGFA4Dim LftGFA4XWidth LftGFA4MsgCnt LftGFA4YWidth;
SIG_GROUP_ 265 GlareFreeArea_4_RHGrp 1 : RtGFA4Valid RtGFA4Cksm RtGFA4PointX RtGFA4PointY RtGFA4LghtOffTmr RtGFA4LghtOnTmr RtGFA4Dim RtGFA4XWidth RtGFA4MsgCnt RtGFA4YWidth;
SIG_GROUP_ 266 GlareFreeArea_5_LHGrp 1 : LftGFA5Valid LftGFA5Cksm LftGFA5PointX LftGFA5PointY LftGFA5LghtOffTmr LftGFA5LghtOnTmr LftGFA5Dim LftGFA5XWidth LftGFA5MsgCnt LftGFA5YWidth;
SIG_GROUP_ 267 GlareFreeArea_5_RHGrp 1 : RtGFA5Valid RtGFA5Cksm RtGFA5PointX RtGFA5PointY RtGFA5LghtOffTmr RtGFA5LghtOnTmr RtGFA5Dim RtGFA5XWidth RtGFA5MsgCnt RtGFA5YWidth;
SIG_GROUP_ 268 GlareFreeArea_6_LHGrp 1 : LftGFA6Valid LftGFA6Cksm LftGFA6PointX LftGFA6PointY LftGFA6LghtOffTmr LftGFA6LghtOnTmr LftGFA6Dim LftGFA6XWidth LftGFA6MsgCnt LftGFA6YWidth;
SIG_GROUP_ 269 GlareFreeArea_6_RHGrp 1 : RtGFA6Valid RtGFA6Cksm RtGFA6PointX RtGFA6PointY RtGFA6LghtOffTmr RtGFA6LghtOnTmr RtGFA6Dim RtGFA6XWidth RtGFA6MsgCnt RtGFA6YWidth;
SIG_GROUP_ 270 GlareFreeArea_7_LHGrp 1 : LftGFA7Valid LftGFA7Cksm LftGFA7PointX LftGFA7PointY LftGFA7LghtOffTmr LftGFA7LghtOnTmr LftGFA7Dim LftGFA7XWidth LftGFA7MsgCnt LftGFA7YWidth;
SIG_GROUP_ 271 GlareFreeArea_7_RHGrp 1 : RtGFA7Valid RtGFA7Cksm RtGFA7PointX RtGFA7PointY RtGFA7LghtOffTmr RtGFA7LghtOnTmr RtGFA7Dim RtGFA7XWidth RtGFA7MsgCnt RtGFA7YWidth;
SIG_GROUP_ 272 GlareFreeArea_8_LHGrp 1 : LftGFA8Valid LftGFA8Cksm LftGFA8PointX LftGFA8PointY LftGFA8LghtOffTmr LftGFA8LghtOnTmr LftGFA8Dim LftGFA8XWidth LftGFA8MsgCnt LftGFA8YWidth;
SIG_GROUP_ 273 GlareFreeArea_8_RHGrp 1 : RtGFA8Valid RtGFA8Cksm RtGFA8PointX RtGFA8PointY RtGFA8LghtOffTmr RtGFA8LghtOnTmr RtGFA8Dim RtGFA8XWidth RtGFA8MsgCnt RtGFA8YWidth;
SIG_GROUP_ 274 GlareFreeArea_9_LHGrp 1 : LftGFA9Valid LftGFA9Cksm LftGFA9PointX LftGFA9PointY LftGFA9LghtOffTmr LftGFA9LghtOnTmr LftGFA9Dim LftGFA9XWidth LftGFA9MsgCnt LftGFA9YWidth;
SIG_GROUP_ 275 GlareFreeArea_9_RHGrp 1 : RtGFA9Valid RtGFA9Cksm RtGFA9PointX RtGFA9PointY RtGFA9LghtOffTmr RtGFA9LghtOnTmr RtGFA9Dim RtGFA9XWidth RtGFA9MsgCnt RtGFA9YWidth;
SIG_GROUP_ 276 GlareFreeArea_10_LHGrp 1 : LftGFA10Valid LftGFA10Cksm LftGFA10PointX LftGFA10PointY LftGFA10LghtOffTmr LftGFA10LghtOnTmr LftGFA10Dim LftGFA10XWidth LftGFA10MsgCnt LftGFA10YWidth;
SIG_GROUP_ 277 GlareFreeArea_10_RHGrp 1 : RtGFA10Valid RtGFA10Cksm RtGFA10PointX RtGFA10PointY RtGFA10LghtOffTmr RtGFA10LghtOnTmr RtGFA10Dim RtGFA10XWidth RtGFA10MsgCnt RtGFA10YWidth;
SIG_GROUP_ 278 GlareFreeArea_11_LHGrp 1 : LftGFA11Valid LftGFA11Cksm LftGFA11PointX LftGFA11PointY LftGFA11LghtOffTmr LftGFA11LghtOnTmr LftGFA11Dim LftGFA11XWidth LftGFA11MsgCnt LftGFA11YWidth;
SIG_GROUP_ 279 GlareFreeArea_11_RHGrp 1 : RtGFA11Valid RtGFA11Cksm RtGFA11PointX RtGFA11PointY RtGFA11LghtOffTmr RtGFA11LghtOnTmr RtGFA11Dim RtGFA11XWidth RtGFA11MsgCnt RtGFA11YWidth;
SIG_GROUP_ 280 GlareFreeArea_12_LHGrp 1 : LftGFA12Valid LftGFA12Cksm LftGFA12PointX LftGFA12PointY LftGFA12LghtOffTmr LftGFA12LghtOnTmr LftGFA12Dim LftGFA12XWidth LftGFA12MsgCnt LftGFA12YWidth;
SIG_GROUP_ 281 GlareFreeArea_12_RHGrp 1 : RtGFA12Valid RtGFA12Cksm RtGFA12PointX RtGFA12PointY RtGFA12LghtOffTmr RtGFA12LghtOnTmr RtGFA12Dim RtGFA12XWidth RtGFA12MsgCnt RtGFA12YWidth;
SIG_GROUP_ 481 RtRtnCtrl 1 : RtRoutineCtrl RtDiagLed;
SIG_GROUP_ 512 LightCenterOfGravityMovementGrp 1 : LCGM_BckgrndLghtLvl LCGM_CntrLghtLvl LCGM_FnctnStat LCGM_LghtCntrWdthLftSdEdg LCGM_LghtCntrWdthRtSdEdg;
SIG_GROUP_ 523 StartStopLightSystemGrp 1 : SSLS_Chcksm SSLS_LftHdlmpStrtStpIntnstyVal SSLS_MssgCntr SSLS_RtHdlmpStrtStpIntnstyVal;
SIG_GROUP_ 1536 GlareFreeArea_1_LH_ActualPosGrp 1 : LftGFA1PointXAct LftGFA1PointYAct LftGFA1DimAct LftGFA1XWidthAct LftGFA1YWidthAct;
SIG_GROUP_ 1537 GlareFreeArea_1_RH_ActualPosGrp 1 : RtGFA1PointXAct RtGFA1PointYAct RtGFA1DimAct RtGFA1XWidthAct RtGFA1YWidthAct;
SIG_GROUP_ 1538 GlareFreeArea_2_LH_ActualPosGrp 1 : LftGFA2PointXAct LftGFA2PointYAct LftGFA2DimAct LftGFA2XWidthAct LftGFA2YWidthAct;
SIG_GROUP_ 1539 GlareFreeArea_2_RH_ActualPosGrp 1 : RtGFA2PointXAct RtGFA2PointYAct RtGFA2DimAct RtGFA2XWidthAct RtGFA2YWidthAct;
SIG_GROUP_ 1540 GlareFreeArea_3_LH_ActualPosGrp 1 : LftGFA3PointXAct LftGFA3PointYAct LftGFA3DimAct LftGFA3XWidthAct LftGFA3YWidthAct;
SIG_GROUP_ 1541 GlareFreeArea_3_RH_ActualPosGrp 1 : RtGFA3PointXAct RtGFA3PointYAct RtGFA3DimAct RtGFA3XWidthAct RtGFA3YWidthAct;
SIG_GROUP_ 1542 GlareFreeArea_4_LH_ActualPosGrp 1 : LftGFA4PointXAct LftGFA4PointYAct LftGFA4DimAct LftGFA4XWidthAct LftGFA4YWidthAct;
SIG_GROUP_ 1543 GlareFreeArea_4_RH_ActualPosGrp 1 : RtGFA4PointXAct RtGFA4PointYAct RtGFA4DimAct RtGFA4XWidthAct RtGFA4YWidthAct;
SIG_GROUP_ 1544 GlareFreeArea_5_LH_ActualPosGrp 1 : LftGFA5PointXAct LftGFA5PointYAct LftGFA5DimAct LftGFA5XWidthAct LftGFA5YWidthAct;
SIG_GROUP_ 1545 GlareFreeArea_5_RH_ActualPosGrp 1 : RtGFA5PointXAct RtGFA5PointYAct RtGFA5DimAct RtGFA5XWidthAct RtGFA5YWidthAct;
SIG_GROUP_ 1546 GlareFreeArea_6_LH_ActualPosGrp 1 : LftGFA6PointXAct LftGFA6PointYAct LftGFA6DimAct LftGFA6XWidthAct LftGFA6YWidthAct;
SIG_GROUP_ 1547 GlareFreeArea_6_RH_ActualPosGrp 1 : RtGFA6PointXAct RtGFA6PointYAct RtGFA6DimAct RtGFA6XWidthAct RtGFA6YWidthAct;
SIG_GROUP_ 1552 LftLghtCentOfGravMovActPosGrp 1 : LftBckgrndLghtLvlActPos LftCntrLghtLvlActPos LftLghtCntrWdthLftSdActPos LftLghtCntrWdthRtSdActPos;
SIG_GROUP_ 1553 RtLghtCentOfGravMovActPosGrp 1 : RtBckgrndLghtLvlActPos RtCntrLghtLvlActPos RtLghtCntrWdthLftSdActPos RtLghtCntrWdthRtSdActPos;
SIG_GROUP_ 1560 LftLghtDistActStatGrp 1 : LftAdvrsWthrLghtActStatus LftCntryLghtActStatus LftDistrSts LftHBFlshrLghtActStatus LftHBLghtActStatus LftMtrwyLghtActStatus LftPdstrnLghtActStatus LftTouristMdAct LftTwnLghtActStatus;
SIG_GROUP_ 1561 RtLghtDistActStatGrp 1 : RtAdvrsWthrLghtActStatus RtCntryLghtActStatus RtDistrSts RtHBFlshrLghtActStatus RtHBLghtActStatus RtMtrwyLghtActStatus RtPdstrnLghtActStatus RtTouristMdAct RtTwnLghtActStatus;
SIG_GROUP_ 1584 GlareFreeArea_7_LH_ActualPosGrp 1 : LftGFA7PointXAct LftGFA7PointYAct LftGFA7DimAct LftGFA7XWidthAct LftGFA7YWidthAct;
SIG_GROUP_ 1585 GlareFreeArea_7_RH_ActualPosGrp 1 : RtGFA7PointXAct RtGFA7PointYAct RtGFA7DimAct RtGFA7XWidthAct RtGFA7YWidthAct;
SIG_GROUP_ 1586 GlareFreeArea_8_LH_ActualPosGrp 1 : LftGFA8PointXAct LftGFA8PointYAct LftGFA8DimAct LftGFA8XWidthAct LftGFA8YWidthAct;
SIG_GROUP_ 1587 GlareFreeArea_8_RH_ActualPosGrp 1 : RtGFA8PointXAct RtGFA8PointYAct RtGFA8DimAct RtGFA8XWidthAct RtGFA8YWidthAct;
SIG_GROUP_ 1588 GlareFreeArea_9_LH_ActualPosGrp 1 : LftGFA9PointXAct LftGFA9PointYAct LftGFA9DimAct LftGFA9XWidthAct LftGFA9YWidthAct;
SIG_GROUP_ 1589 GlareFreeArea_9_RH_ActualPosGrp 1 : RtGFA9PointXAct RtGFA9PointYAct RtGFA9DimAct RtGFA9XWidthAct RtGFA9YWidthAct;
SIG_GROUP_ 1590 GlareFreeArea_10_LH_ActualPosGrp 1 : LftGFA10PointXAct LftGFA10PointYAct LftGFA10DimAct LftGFA10XWidthAct LftGFA10YWidthAct;
SIG_GROUP_ 1591 GlareFreeArea_10_RH_ActualPosGrp 1 : RtGFA10PointXAct RtGFA10PointYAct RtGFA10DimAct RtGFA10XWidthAct RtGFA10YWidthAct;
SIG_GROUP_ 1592 GlareFreeArea_11_LH_ActualPosGrp 1 : LftGFA11PointXAct LftGFA11PointYAct LftGFA11DimAct LftGFA11XWidthAct LftGFA11YWidthAct;
SIG_GROUP_ 1593 GlareFreeArea_11_RH_ActualPosGrp 1 : RtGFA11PointXAct RtGFA11PointYAct RtGFA11DimAct RtGFA11XWidthAct RtGFA11YWidthAct;
SIG_GROUP_ 1594 GlareFreeArea_12_LH_ActualPosGrp 1 : LftGFA12PointXAct LftGFA12PointYAct LftGFA12DimAct LftGFA12XWidthAct LftGFA12YWidthAct;
SIG_GROUP_ 1595 GlareFreeArea_12_RH_ActualPosGrp 1 : RtGFA12PointXAct RtGFA12PointYAct RtGFA12DimAct RtGFA12XWidthAct RtGFA12YWidthAct;
SIG_GROUP_ 1792 VehicleIdentNumberGrp 1 : VINDts6 VINDts5 VINDts4 VINDts3 VINDts2 VINDts1 VINDts0 VINIdx;
